VERSION ""

NS_ :

BS_:

BU_: TCM HCM IPMA_ADAS PSCM ABS_ESC TCCM TCM_DSL PCM_HEV PCM ECM_HEVDSL ECM_HEV ECM_Diesel ECM SIMA_DLCS BCMD_IPDB VDM CMR_DSMC SOBDMC_HPCM_FD1 CHCM GWM _delete AWD_DLCM GENERIC TSTR

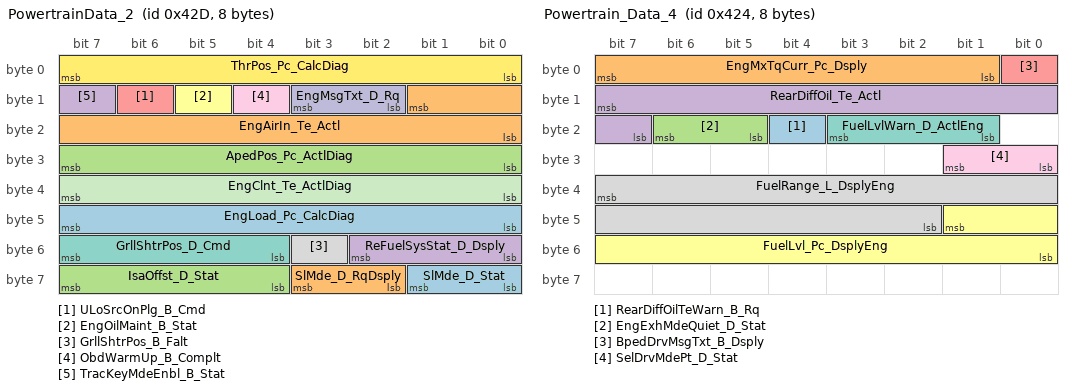
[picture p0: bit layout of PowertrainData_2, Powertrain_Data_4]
BO_ 1069 PowertrainData_2: 8 PCM_HEV
 SG_ SlMde_D_Stat : 57|2@0+ (1,0) [0|3] "SED"  GWM
 SG_ SlMde_D_RqDsply : 59|2@0+ (1,0) [0|3] "SED"  GWM
 SG_ IsaOffst_D_Stat : 63|4@0+ (1,0) [0|15] "SED"  GWM
 SG_ ReFuelSysStat_D_Dsply : 50|3@0+ (1,0) [0|7] "SED"  GWM
 SG_ ULoSrcOnPlg_B_Cmd : 14|1@0+ (1,0) [0|1] "SED"  SOBDMC_HPCM_FD1,GWM
 SG_ EngOilMaint_B_Stat : 13|1@0+ (1,0) [0|1] "SED"  SOBDMC_HPCM_FD1,GWM
 SG_ GrllShtrPos_D_Cmd : 55|4@0+ (1,0) [0|15] "SED"  GWM
 SG_ GrllShtrPos_B_Falt : 51|1@0+ (1,0) [0|1] "SED"  GWM
 SG_ ObdWarmUp_B_Complt : 12|1@0+ (1,0) [0|1] "SED"  SOBDMC_HPCM_FD1,GWM,TCM,TCM_DSL
 SG_ EngMsgTxt_D_Rq : 11|2@0+ (1,0) [0|3] "SED"  GWM
 SG_ EngClnt_Te_ActlDiag : 39|8@0+ (1,-40) [-40|215] "degC"  TCM,SOBDMC_HPCM_FD1,TCM_DSL,GWM,CHCM
 SG_ ThrPos_Pc_CalcDiag : 7|8@0+ (0.392157,0) [0|100.000035] "%"  TCM,GWM,TCM_DSL
 SG_ EngLoad_Pc_CalcDiag : 47|8@0+ (0.392157,0) [0|100.000035] "%"  TCM,SOBDMC_HPCM_FD1,TCM_DSL,GWM
 SG_ EngAirIn_Te_Actl : 9|10@0+ (0.25,-128) [-128|127.25] "degC"  TCM,GWM,TCM_DSL
 SG_ ApedPos_Pc_ActlDiag : 31|8@0+ (0.392157,0) [0|100.000035] "%"  TCM,SOBDMC_HPCM_FD1,TCM_DSL,GWM
 SG_ TracKeyMdeEnbl_B_Stat : 15|1@0+ (1,0) [0|1] "SED"  GWM

BO_ 1060 Powertrain_Data_4: 8 PCM_HEV
 SG_ RearDiffOilTeWarn_B_Rq : 20|1@0+ (1,0) [0|1] "SED"  GWM
 SG_ EngMxTqCurr_Pc_Dsply : 7|7@0+ (1,0) [0|100] "percent"  GWM
 SG_ EngExhMdeQuiet_D_Stat : 22|2@0+ (1,0) [0|3] "SED"  GWM
 SG_ RearDiffOil_Te_Actl : 15|9@0+ (1,-40) [-40|470] "degC"  GWM,AWD_DLCM
 SG_ BpedDrvMsgTxt_B_Dsply : 0|1@0+ (1,0) [0|1] "SED"  GWM
 SG_ FuelLvl_Pc_DsplyEng : 41|10@0+ (0.108696,-5.217408) [-5.217408|105.9786] "percent"  GWM
 SG_ FuelLvlWarn_D_ActlEng : 19|3@0+ (1,0) [0|7] "SED"  GWM
 SG_ FuelRange_L_DsplyEng : 39|14@0+ (0.1,0) [0|1638.3] "kilometer"  GWM
 SG_ SelDrvMdePt_D_Stat : 25|2@0+ (1,0) [0|3] "SED"  ABS_ESC,GWM

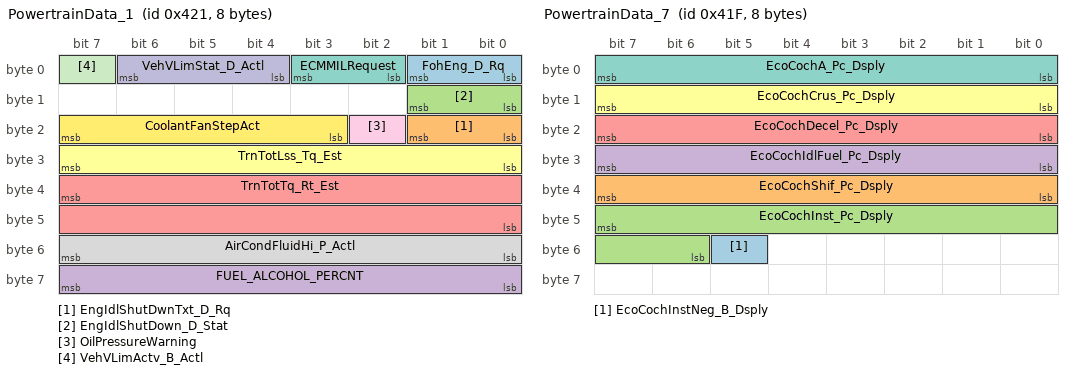
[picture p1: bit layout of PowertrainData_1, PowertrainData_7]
BO_ 1057 PowertrainData_1: 8 PCM_HEV
 SG_ FohEng_D_Rq : 1|2@0+ (1,0) [0|3] "SED"  GWM
 SG_ EngIdlShutDwnTxt_D_Rq : 17|2@0+ (1,0) [0|3] "SED"  GWM
 SG_ EngIdlShutDown_D_Stat : 9|2@0+ (1,0) [0|3] "SED"  GWM
 SG_ FUEL_ALCOHOL_PERCNT : 63|8@0+ (0.393700787,0) [0|99.999899898] "Percent"  GWM
 SG_ TrnTotTq_Rt_Est : 39|16@0+ (0.001,0) [0|65.533] "Unitless"  ABS_ESC,TCM,GWM,TCM_DSL
 SG_ TrnTotLss_Tq_Est : 31|8@0+ (0.5,0) [0|126.5] "Nm"  ABS_ESC,TCM,GWM,TCM_DSL
 SG_ ECMMILRequest : 3|2@0+ (1,0) [0|3] "SED"  GWM
 SG_ AirCondFluidHi_P_Actl : 55|8@0+ (0.125,0) [0|31.625] "bar"  SOBDMC_HPCM_FD1,GWM
 SG_ OilPressureWarning : 18|1@0+ (1,0) [0|1] "SED"  GWM
 SG_ VehVLimStat_D_Actl : 6|3@0+ (1,0) [0|7] "SED"  TCM,GWM,TCM_DSL
 SG_ VehVLimActv_B_Actl : 7|1@0+ (1,0) [0|1] "SED"  SOBDMC_HPCM_FD1,TCM,GWM,TCM_DSL
 SG_ CoolantFanStepAct : 23|5@0+ (1,0) [0|31] "Steps"  GWM

BO_ 1055 PowertrainData_7: 8 PCM_HEV
 SG_ EcoCochInstNeg_B_Dsply : 53|1@0+ (1,0) [0|1] "SED"  GWM
 SG_ EcoCochShif_Pc_Dsply : 39|8@0+ (0.392157,0) [0|100.000035] "percent"  GWM
 SG_ EcoCochInst_Pc_Dsply : 47|10@0+ (0.1,0) [0|102.3] "percent"  GWM
 SG_ EcoCochIdlFuel_Pc_Dsply : 31|8@0+ (0.392157,0) [0|100.000035] "percent"  GWM
 SG_ EcoCochDecel_Pc_Dsply : 23|8@0+ (0.392157,0) [0|100.000035] "percent"  GWM
 SG_ EcoCochCrus_Pc_Dsply : 15|8@0+ (0.392157,0) [0|100.000035] "percent"  GWM
 SG_ EcoCochA_Pc_Dsply : 7|8@0+ (0.392157,0) [0|100.000035] "percent"  GWM

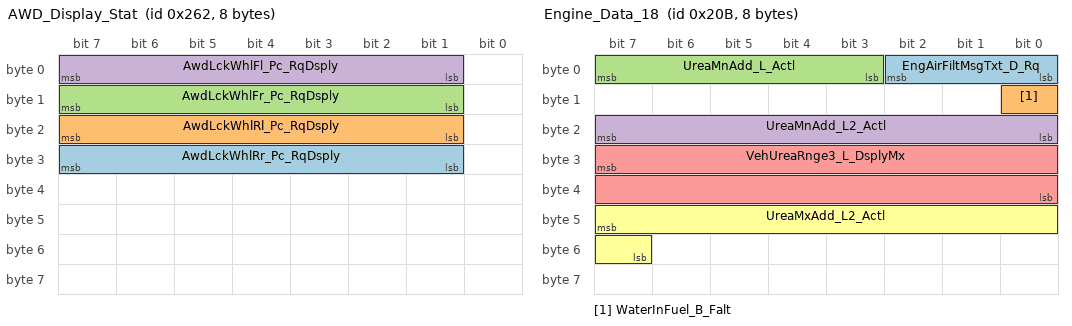
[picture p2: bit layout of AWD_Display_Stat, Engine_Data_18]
BO_ 610 AWD_Display_Stat: 8 PCM_HEV
 SG_ AwdLckWhlRr_Pc_RqDsply : 31|7@0+ (1,0) [0|127] "percent"  GWM
 SG_ AwdLckWhlRl_Pc_RqDsply : 23|7@0+ (1,0) [0|127] "percent"  GWM
 SG_ AwdLckWhlFr_Pc_RqDsply : 15|7@0+ (1,0) [0|127] "percent"  GWM
 SG_ AwdLckWhlFl_Pc_RqDsply : 7|7@0+ (1,0) [0|127] "percent"  GWM

BO_ 562 PowertrainData_11: 8 ECM
 SG_ GearNtrl_No_Cs : 15|8@0+ (1,0) [0|255] "unitless"  ABS_ESC,GWM
 SG_ GearNtrl_D_Stat : 7|2@0+ (1,0) [0|3] "SED"  ABS_ESC,GWM
 SG_ OnePdlDrv_D_Stat : 1|2@0+ (1,0) [0|3] "SED"  ABS_ESC,SOBDMC_HPCM_FD1
 SG_ GearNtrl_No_Cnt : 5|4@0+ (1,0) [0|15] "unitless"  ABS_ESC,GWM

BO_ 523 Engine_Data_18: 8 PCM
 SG_ EngAirFiltMsgTxt_D_Rq : 2|3@0+ (1,0) [0|7] "SED"  GWM
 SG_ WaterInFuel_B_Falt : 8|1@0+ (1,0) [0|1] "SED"  GWM
 SG_ UreaMnAdd_L_Actl : 7|5@0+ (1,0) [0|31] "litre"  GWM
 SG_ UreaMnAdd_L2_Actl : 23|8@0+ (0.1,0) [0|25.4] "litre"  GWM
 SG_ VehUreaRnge3_L_DsplyMx : 31|16@0+ (1,0) [0|65535] "unitless"  GWM
 SG_ UreaMxAdd_L2_Actl : 47|9@0+ (0.1,0) [0|51] "litre"  GWM

BO_ 519 PowertrainData_8: 8 ECM
 SG_ RearDiffLck_Tq_Rq : 7|14@0+ (1,0) [0|16381] "Nm"  GWM

BO_ 517 PowertrainData_6: 8 PCM_HEV
 SG_ FapLc_B_Err : 10|1@0+ (1,0) [0|1] "SED"  IPMA_ADAS,GWM
 SG_ BrkTot_Tq_RqFapLc : 7|13@0+ (4,0) [0|32764] "Nm"  ABS_ESC,GWM
 SG_ TrnAin_Pc_RqDrv : 9|10@0+ (0.1,0) [0|102.3] "percent"  GWM,AWD_DLCM,TCCM

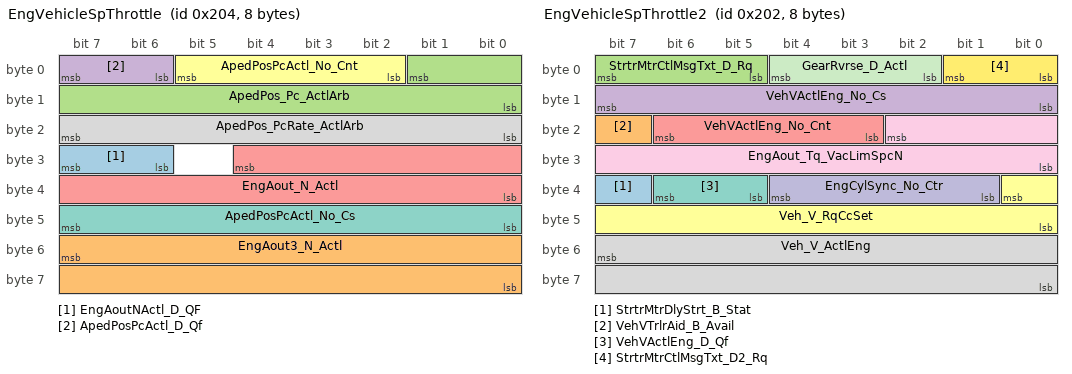
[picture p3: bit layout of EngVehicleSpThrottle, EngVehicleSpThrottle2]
BO_ 516 EngVehicleSpThrottle: 8 PCM_HEV
 SG_ EngAoutNActl_D_QF : 31|2@0+ (1,0) [0|3] "SED"  TCM,TCM_DSL,GWM
 SG_ EngAout3_N_Actl : 55|16@0+ (0.25,0) [0|16383.5] "RPM"  SOBDMC_HPCM_FD1,GWM
 SG_ ApedPos_Pc_ActlArb : 1|10@0+ (0.1,0) [0|102.3] "%"  TCM,CMR_DSMC,VDM,SOBDMC_HPCM_FD1,HCM,IPMA_ADAS,TCCM,ABS_ESC,PSCM,TCM_DSL,GWM,AWD_DLCM
 SG_ ApedPosPcActl_D_Qf : 7|2@0+ (1,0) [0|3] "SED"  CMR_DSMC,TCM,VDM,SOBDMC_HPCM_FD1,HCM,IPMA_ADAS,ABS_ESC,PSCM,TCM_DSL,GWM,AWD_DLCM
 SG_ EngAout_N_Actl : 28|13@0+ (2,0) [0|16382] "rpm"  TCM,VDM,HCM,ABS_ESC,PSCM,TCCM,TCM_DSL,GWM,AWD_DLCM
 SG_ ApedPosPcActl_No_Cnt : 5|4@0+ (1,0) [0|15] "Unitless"  TCM,SOBDMC_HPCM_FD1,ABS_ESC,TCM_DSL,GWM
 SG_ ApedPosPcActl_No_Cs : 47|8@0+ (1,0) [0|255] "Unitless"  TCM,SOBDMC_HPCM_FD1,ABS_ESC,TCM_DSL,GWM
 SG_ ApedPos_PcRate_ActlArb : 23|8@0+ (0.04,-5) [-5|5.12] "%/ms"  AWD_DLCM,TCM,TCM_DSL,GWM

BO_ 514 EngVehicleSpThrottle2: 8 PCM_HEV
 SG_ StrtrMtrDlyStrt_B_Stat : 39|1@0+ (1,0) [0|1] "SED"  GWM
 SG_ VehVTrlrAid_B_Avail : 23|1@0+ (1,0) [0|1] "SED"  PSCM,GWM
 SG_ StrtrMtrCtlMsgTxt_D_Rq : 7|3@0+ (1,0) [0|7] "SED"  GWM
 SG_ VehVActlEng_No_Cs : 15|8@0+ (1,0) [0|255] "Unitless"  ABS_ESC,PSCM,GWM
 SG_ VehVActlEng_No_Cnt : 22|4@0+ (1,0) [0|15] "Unitless"  ABS_ESC,PSCM,GWM
 SG_ Veh_V_RqCcSet : 32|9@0+ (0.5,0) [0|255.5] "kph"  TCM,IPMA_ADAS,PSCM,ABS_ESC,TCM_DSL,GWM,SOBDMC_HPCM_FD1
 SG_ VehVActlEng_D_Qf : 38|2@0+ (1,0) [0|3] "SED"  TCM,HCM,IPMA_ADAS,ABS_ESC,PSCM,TCM_DSL,GWM,VDM,AWD_DLCM
 SG_ Veh_V_ActlEng : 55|16@0+ (0.01,0) [0|655.35] "kph"  TCM,SOBDMC_HPCM_FD1,HCM,IPMA_ADAS,ABS_ESC,PSCM,TCM_DSL,VDM,GWM,AWD_DLCM
 SG_ EngAout_Tq_VacLimSpcN : 18|11@0+ (1,-500) [-500|1547] "Nm"  SOBDMC_HPCM_FD1,GWM
 SG_ EngCylSync_No_Ctr : 36|4@0+ (1,0) [0|15] "unitless"  SOBDMC_HPCM_FD1,GWM
 SG_ GearRvrse_D_Actl : 4|3@0+ (1,0) [0|7] "SED"  IPMA_ADAS,CMR_DSMC,ABS_ESC,PSCM,GWM,VDM,HCM,CHCM
 SG_ StrtrMtrCtlMsgTxt_D2_Rq : 1|2@0+ (1,0) [0|3] "SED"  GWM

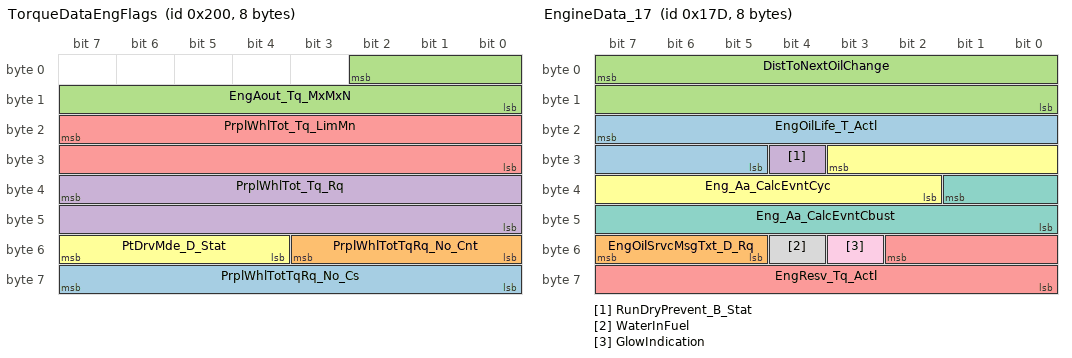
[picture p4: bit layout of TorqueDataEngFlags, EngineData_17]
BO_ 512 TorqueDataEngFlags: 8 PCM_HEV
 SG_ PrplWhlTotTqRq_No_Cs : 63|8@0+ (1,0) [0|255] "Unitless"  SOBDMC_HPCM_FD1,ABS_ESC,GWM
 SG_ PrplWhlTotTqRq_No_Cnt : 51|4@0+ (1,0) [0|15] "Unitless"  SOBDMC_HPCM_FD1,ABS_ESC,GWM
 SG_ EngAout_Tq_MxMxN : 2|11@0+ (1,-500) [-500|1547] "Nm"  SOBDMC_HPCM_FD1,GWM
 SG_ PrplWhlTot_Tq_Rq : 39|16@0+ (4,-131072) [-131072|131068] "Nm"  VDM,SOBDMC_HPCM_FD1,TCCM,ABS_ESC,GWM,AWD_DLCM
 SG_ PrplWhlTot_Tq_LimMn : 23|16@0+ (4,-131072) [-131072|131068] "Nm"  ABS_ESC,GWM
 SG_ PtDrvMde_D_Stat : 55|4@0+ (1,0) [0|15] "SED"  IPMA_ADAS,ABS_ESC,GWM

BO_ 382 EngineData_Gas: 8 PCM
 SG_ EngMnfldChrg_Te_Actl : 15|7@0+ (1,-20) [-20|105] "degC"  GWM
 SG_ EngInnrClnt_Te_Actl : 7|7@0+ (1,50) [50|175] "degC"  GWM

BO_ 381 EngineData_17: 8 ECM_HEVDSL
 SG_ EngOilLife_T_Actl : 23|11@0+ (1,0) [0|2047] "days"  GWM
 SG_ EngOilSrvcMsgTxt_D_Rq : 55|3@0+ (1,0) [0|7] "SED"  GWM
 SG_ DistToNextOilChange : 7|16@0+ (1,0) [0|65535] "unitless"  GWM
 SG_ RunDryPrevent_B_Stat : 28|1@0+ (1,0) [0|1] "SED"  GWM
 SG_ EngResv_Tq_Actl : 50|11@0+ (1,-500) [-500|1547] "Nm"  GWM
 SG_ Eng_Aa_CalcEvntCyc : 27|10@0+ (0.05,-25.6) [-25.6|25.55] "rpm/ms"  GWM
 SG_ Eng_Aa_CalcEvntCbust : 33|10@0+ (0.05,-25.6) [-25.6|25.55] "rpm/ms"  GWM
 SG_ WaterInFuel : 52|1@0+ (1,0) [0|1] "SED"  GWM
 SG_ GlowIndication : 51|1@0+ (1,0) [0|1] "SED"  GWM

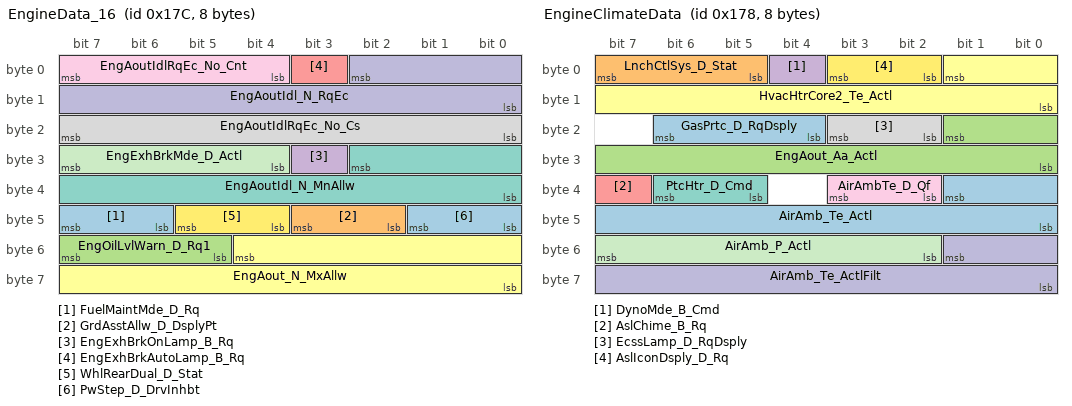
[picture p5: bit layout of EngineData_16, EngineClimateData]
BO_ 380 EngineData_16: 8 PCM
 SG_ FuelMaintMde_D_Rq : 47|2@0+ (1,0) [0|3] "SED"  SOBDMC_HPCM_FD1,GWM
 SG_ GrdAsstAllw_D_DsplyPt : 43|2@0+ (1,0) [0|3] "SED"  SOBDMC_HPCM_FD1,GWM
 SG_ EngOilLvlWarn_D_Rq1 : 55|3@0+ (1,0) [0|7] "SED"  GWM
 SG_ EngExhBrkOnLamp_B_Rq : 27|1@0+ (1,0) [0|1] "SED"  GWM
 SG_ EngExhBrkAutoLamp_B_Rq : 3|1@0+ (1,0) [0|1] "SED"  GWM
 SG_ EngAout_N_MxAllw : 52|13@0+ (2,0) [0|16382] "rpm"  TCM,SOBDMC_HPCM_FD1,TCM_DSL,GWM
 SG_ EngAoutIdl_N_MnAllw : 26|11@0+ (2,0) [0|4094] "rpm"  GWM
 SG_ EngAoutIdlRqEc_No_Cs : 23|8@0+ (1,0) [0|255] "Unitless"  GWM
 SG_ EngAoutIdlRqEc_No_Cnt : 7|4@0+ (1,0) [0|15] "Unitless"  GWM
 SG_ EngAoutIdl_N_RqEc : 2|11@0+ (2,0) [0|4094] "rpm"  GWM
 SG_ EngExhBrkMde_D_Actl : 31|4@0+ (1,0) [0|15] "SED"  TCM,TCM_DSL,GWM
 SG_ WhlRearDual_D_Stat : 45|2@0+ (1,0) [0|3] "SED"  TCM,TCM_DSL,GWM
 SG_ PwStep_D_DrvInhbt : 41|2@0+ (1,0) [0|3] "SED"  GWM

BO_ 377 EngineData_7: 8 PCM_HEV
 SG_ HvacAirFullOut_B_Rq : 23|1@0+ (1,0) [0|1] "SED"  GWM
 SG_ TrnManShif_D_IndDrv : 7|3@0+ (1,0) [0|7] "Unitless"  GWM
 SG_ EngAout_Tq_Actl : 2|11@0+ (1,-500) [-500|1547] "Nm"  SOBDMC_HPCM_FD1,GWM
 SG_ TrnManShifGear_D_IndDrv : 54|3@0+ (1,0) [0|7] "SED"  GWM
 SG_ EngFuelCutFull_B_Inhbt : 22|1@0+ (1,0) [0|1] "SED"  SOBDMC_HPCM_FD1,GWM
 SG_ EngDecelFuelCut_B_Allw : 21|1@0+ (1,0) [0|1] "SED"  TCM,TCM_DSL,GWM
 SG_ FuelFlw_Vl_Dsply : 49|10@0+ (25,0) [0|25575] "Micro_Liter"  SOBDMC_HPCM_FD1,GWM
 SG_ FuelFillInlet_B_Dsply : 32|1@0+ (1,0) [0|1] "SED"  GWM
 SG_ EngSrvcRqd_B_Rq : 19|1@0+ (1,0) [0|1] "SED"  GWM
 SG_ OdoCount : 47|8@0+ (0.2,0) [0|50.8] "Meters"  GWM
 SG_ EngOilLife_Pc_Actl : 39|7@0+ (1,0) [0|100] "Percent"  GWM
 SG_ EngTqSlwDly_T_Est : 18|11@0+ (1,0) [0|2047] "ms"  TCM,TCM_DSL,GWM
 SG_ TrnKickDown_B_RqDrv : 20|1@0+ (1,0) [0|1] "SED"  TCM,TCM_DSL,GWM
 SG_ FuelFilterLamp_B_Dsply : 50|1@0+ (1,0) [0|1] "SED"  GWM
 SG_ AirCondRec_B_Rq : 55|1@0+ (1,0) [0|1] "SED"  GWM
 SG_ AirCondClutch_B_Stats : 51|1@0+ (1,0) [0|1] "SED"  TCM,TCM_DSL,GWM
 SG_ EngAoutTqActl_D_Qf : 4|2@0+ (1,0) [0|3] "SED"  SOBDMC_HPCM_FD1,GWM

BO_ 376 EngineClimateData: 8 PCM_HEV
 SG_ GasPrtc_D_RqDsply : 22|3@0+ (1,0) [0|7] "SED"  GWM
 SG_ LnchCtlSys_D_Stat : 7|3@0+ (1,0) [0|7] "SED"  ABS_ESC,GWM
 SG_ EngAout_Aa_Actl : 17|10@0+ (0.05,-25.6) [-25.6|25.55] "rpm/ms"  TCM,TCM_DSL,ABS_ESC,GWM
 SG_ DynoMde_B_Cmd : 4|1@0+ (1,0) [0|1] "SED"  TCM,TCM_DSL,ABS_ESC,GWM
 SG_ AslChime_B_Rq : 39|1@0+ (1,0) [0|1] "SED"  GWM
 SG_ HvacHtrCore2_Te_Actl : 1|10@0+ (0.25,-50) [-50|205.5] "degC"  SOBDMC_HPCM_FD1,GWM
 SG_ PtcHtr_D_Cmd : 38|2@0+ (1,0) [0|3] "SED"  SOBDMC_HPCM_FD1,GWM
 SG_ EcssLamp_D_RqDsply : 19|2@0+ (1,0) [0|3] "SED"  GWM
 SG_ AirAmbTe_D_Qf : 35|2@0+ (1,0) [0|3] "SED"  TCM,SOBDMC_HPCM_FD1,IPMA_ADAS,TCM_DSL,ABS_ESC,TCCM,GWM,VDM,AWD_DLCM,CHCM
 SG_ AirAmb_Te_ActlFilt : 49|10@0+ (0.25,-128) [-128|127.75] "deg C"  TCM,SOBDMC_HPCM_FD1,IPMA_ADAS,TCM_DSL,VDM,GWM,CHCM
 SG_ AirAmb_P_Actl : 55|6@0+ (10,500) [500|1110] "mbar"  TCM,TCM_DSL,ABS_ESC,GWM,VDM
 SG_ AslIconDsply_D_Rq : 3|2@0+ (1,0) [0|3] "SED"  GWM
 SG_ AirAmb_Te_Actl : 33|10@0+ (0.25,-128) [-128|127.75] "degC"  VDM,TCM_DSL,TCM,TCCM,HCM,AWD_DLCM,ABS_ESC,GWM,CHCM

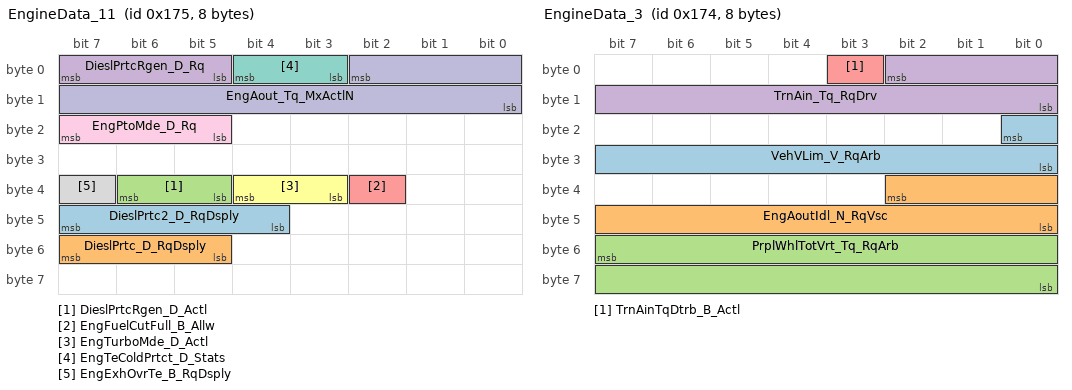
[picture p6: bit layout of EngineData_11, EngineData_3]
BO_ 373 EngineData_11: 8 ECM_HEVDSL
 SG_ DieslPrtc2_D_RqDsply : 47|4@0+ (1,0) [0|15] "SED"  GWM
 SG_ DieslPrtc_D_RqDsply : 55|3@0+ (1,0) [0|7] "SED"  GWM
 SG_ DieslPrtcRgen_D_Actl : 38|2@0+ (1,0) [0|3] "SED"  TCM,TCM_DSL,GWM
 SG_ DieslPrtcRgen_D_Rq : 7|3@0+ (1,0) [0|7] "SED"  GWM
 SG_ EngFuelCutFull_B_Allw : 34|1@0+ (1,0) [0|1] "SED"  SOBDMC_HPCM_FD1,GWM
 SG_ EngTurboMde_D_Actl : 36|2@0+ (1,0) [0|3] "SED"  TCM,TCM_DSL,GWM
 SG_ EngTeColdPrtct_D_Stats : 4|2@0+ (1,0) [0|3] "SED"  GWM
 SG_ EngExhOvrTe_B_RqDsply : 39|1@0+ (1,0) [0|1] "SED"  GWM
 SG_ EngPtoMde_D_Rq : 23|3@0+ (1,0) [0|7] "SED"  TCM,TCM_DSL,GWM
 SG_ EngAout_Tq_MxActlN : 2|11@0+ (1,-500) [-500|1547] "Nm"  GWM,GENERIC

BO_ 372 EngineData_3: 8 ECM
 SG_ VehVLim_V_RqArb : 16|9@0+ (0.5,0) [0|255.5] "kph"  TCM,TCM_DSL,GWM
 SG_ EngAoutIdl_N_RqVsc : 34|11@0+ (2,0) [0|4094] "rpm"  TCM,TCM_DSL,ABS_ESC,GWM
 SG_ PrplWhlTotVrt_Tq_RqArb : 55|16@0+ (4,-131072) [-131072|131068] "Nm"  TCM,TCM_DSL,GWM
 SG_ TrnAin_Tq_RqDrv : 2|11@0+ (1,-500) [-500|1547] "Nm"  TCM,TCM_DSL,GWM
 SG_ TrnAinTqDtrb_B_Actl : 3|1@0+ (1,0) [0|1] "SED"  TCM,TCM_DSL,GWM

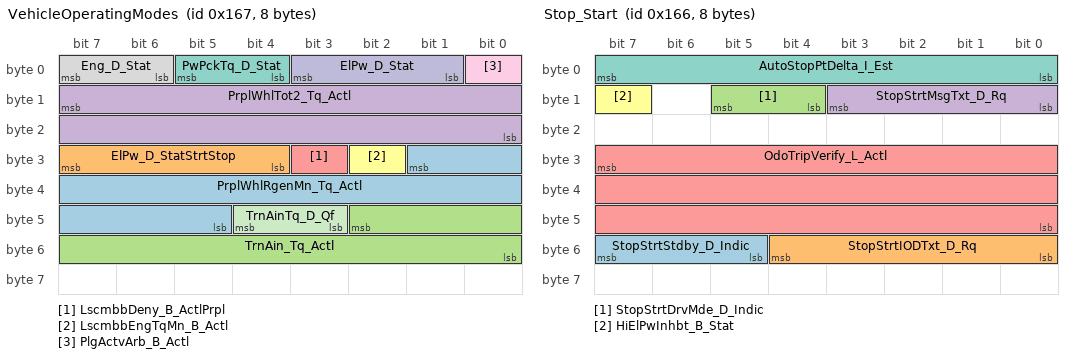
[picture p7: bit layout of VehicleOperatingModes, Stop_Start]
BO_ 359 VehicleOperatingModes: 8 PCM_HEV
 SG_ PrplWhlRgenMn_Tq_Actl : 25|13@0+ (4,-16380) [-16380|16380] "Nm"  ABS_ESC,GWM,AWD_DLCM
 SG_ ElPw_D_StatStrtStop : 31|4@0+ (1,0) [0|15] "SED"  PSCM,GWM,ABS_ESC
 SG_ TrnAin_Tq_Actl : 42|11@0+ (1,-500) [-500|1547] "Nm"  TCM,ABS_ESC,TCM_DSL,GWM,AWD_DLCM
 SG_ PrplWhlTot2_Tq_Actl : 15|16@0+ (4,-131072) [-131072|131060] "Nm"  VDM,ABS_ESC,ECM_HEV,PSCM,TCCM,GWM,AWD_DLCM
 SG_ LscmbbDeny_B_ActlPrpl : 27|1@0+ (1,0) [0|1] "SED"  ABS_ESC,GWM
 SG_ LscmbbEngTqMn_B_Actl : 26|1@0+ (1,0) [0|1] "SED"  ABS_ESC,GWM
 SG_ PwPckTq_D_Stat : 5|2@0+ (1,0) [0|3] "SED"  TCM,SOBDMC_HPCM_FD1,VDM,HCM,IPMA_ADAS,ABS_ESC,ECM_HEV,PSCM,TCCM,TCM_DSL,CMR_DSMC,GWM,AWD_DLCM,CHCM
 SG_ Eng_D_Stat : 7|2@0+ (1,0) [0|3] "SED"  TCM,VDM,ABS_ESC,TCM_DSL,GWM,AWD_DLCM
 SG_ PlgActvArb_B_Actl : 0|1@0+ (1,0) [0|1] "SED"  SOBDMC_HPCM_FD1,GWM,ECM_HEV
 SG_ ElPw_D_Stat : 3|3@0+ (1,0) [0|7] "SED"  TCM,VDM,HCM,IPMA_ADAS,ABS_ESC,ECM_HEV,PSCM,TCCM,TCM_DSL,GWM,CMR_DSMC,AWD_DLCM,CHCM
 SG_ TrnAinTq_D_Qf : 44|2@0+ (1,0) [0|3] "SED"  TCM,ABS_ESC,TCM_DSL,GWM,AWD_DLCM

BO_ 358 Stop_Start: 8 PCM_HEV
 SG_ StopStrtStdby_D_Indic : 55|3@0+ (1,0) [0|7] "SED"  GWM
 SG_ StopStrtIODTxt_D_Rq : 52|5@0+ (1,0) [0|31] "SED"  GWM
 SG_ StopStrtDrvMde_D_Indic : 13|2@0+ (1,0) [0|3] "SED"  GWM
 SG_ StopStrtMsgTxt_D_Rq : 11|4@0+ (1,0) [0|15] "SED"  GWM
 SG_ OdoTripVerify_L_Actl : 31|24@0+ (0.1,0) [0|1677721.4] "km"  GWM
 SG_ HiElPwInhbt_B_Stat : 15|1@0+ (1,0) [0|1] "SED"  GWM
 SG_ AutoStopPtDelta_I_Est : 7|8@0+ (1,-127) [-127|127] "Amps"  GWM

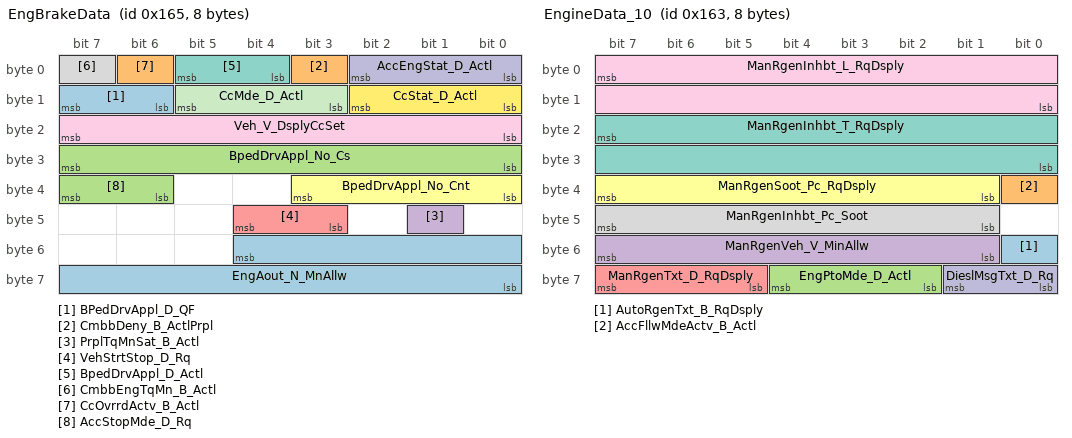
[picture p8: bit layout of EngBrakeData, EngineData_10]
BO_ 357 EngBrakeData: 8 PCM_HEV
 SG_ BPedDrvAppl_D_QF : 15|2@0+ (1,0) [0|3] "SED"  TCM,SOBDMC_HPCM_FD1,IPMA_ADAS,ABS_ESC,PSCM,TCM_DSL,GWM,VDM,CMR_DSMC,AWD_DLCM
 SG_ CmbbDeny_B_ActlPrpl : 3|1@0+ (1,0) [0|1] "SED"  IPMA_ADAS,GWM
 SG_ BpedDrvAppl_No_Cs : 31|8@0+ (1,0) [0|255] "Unitless"  SOBDMC_HPCM_FD1,GWM
 SG_ PrplTqMnSat_B_Actl : 41|1@0+ (1,0) [0|1] "SED"  IPMA_ADAS,GWM
 SG_ VehStrtStop_D_Rq : 44|2@0+ (1,0) [0|3] "SED"  SOBDMC_HPCM_FD1,GWM
 SG_ BpedDrvAppl_No_Cnt : 35|4@0+ (1,0) [0|15] "Unitless"  SOBDMC_HPCM_FD1,GWM
 SG_ BpedDrvAppl_D_Actl : 5|2@0+ (1,0) [0|3] "SED"  TCM,SOBDMC_HPCM_FD1,IPMA_ADAS,ABS_ESC,PSCM,TCCM,TCM_DSL,VDM,GWM,CMR_DSMC,AWD_DLCM
 SG_ CmbbEngTqMn_B_Actl : 7|1@0+ (1,0) [0|1] "SED"  IPMA_ADAS,GWM
 SG_ Veh_V_DsplyCcSet : 23|8@0+ (1,0) [0|253] "Unitless"  GWM,IPMA_ADAS
 SG_ AccEngStat_D_Actl : 2|3@0+ (1,0) [0|7] "SED"  IPMA_ADAS,GWM
 SG_ CcMde_D_Actl : 13|3@0+ (1,0) [0|7] "SED"  TCM,TCM_DSL,ABS_ESC,GWM,VDM
 SG_ CcStat_D_Actl : 10|3@0+ (1,0) [0|7] "SED"  TCM,SOBDMC_HPCM_FD1,IPMA_ADAS,ABS_ESC,TCCM,TCM_DSL,GWM,CMR_DSMC,AWD_DLCM
 SG_ EngAout_N_MnAllw : 52|13@0+ (2,0) [0|16382] "rpm"  TCM,SOBDMC_HPCM_FD1,TCM_DSL,GWM
 SG_ CcOvrrdActv_B_Actl : 6|1@0+ (1,0) [0|1] "SED"  TCM,IPMA_ADAS,ABS_ESC,TCCM,TCM_DSL,GWM,VDM,AWD_DLCM
 SG_ AccStopMde_D_Rq : 39|2@0+ (1,0) [0|3] "SED"  IPMA_ADAS,ABS_ESC,GWM

BO_ 355 EngineData_10: 8 ECM_HEVDSL
 SG_ AutoRgenTxt_B_RqDsply : 48|1@0+ (1,0) [0|1] "SED"  GWM
 SG_ AccFllwMdeActv_B_Actl : 32|1@0+ (1,0) [0|1] "SED"  TCM,TCM_DSL,GWM
 SG_ EngPtoMde_D_Actl : 60|3@0+ (1,0) [0|7] "SED"  TCM,TCM_DSL,GWM
 SG_ ManRgenVeh_V_MinAllw : 55|7@0+ (1,0) [0|126] "kilometer/hour"  GWM
 SG_ ManRgenTxt_D_RqDsply : 63|3@0+ (1,0) [0|7] "SED"  GWM
 SG_ ManRgenSoot_Pc_RqDsply : 39|7@0+ (1,0) [0|126] "%"  GWM
 SG_ ManRgenInhbt_T_RqDsply : 23|16@0+ (1,0) [0|65534] "Minutes"  GWM
 SG_ ManRgenInhbt_Pc_Soot : 47|7@0+ (1,0) [0|126] "%"  GWM
 SG_ ManRgenInhbt_L_RqDsply : 7|16@0+ (1,0) [0|65534] "kilometer"  GWM
 SG_ DieslMsgTxt_D_Rq : 57|2@0+ (1,0) [0|3] "SED"  GWM

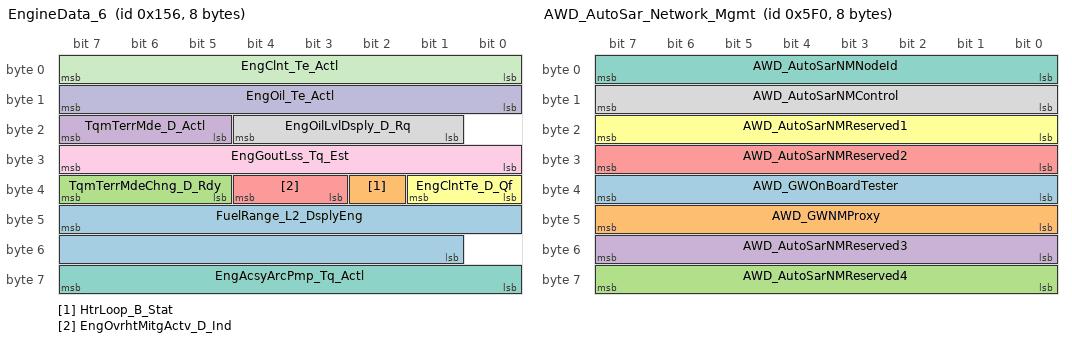
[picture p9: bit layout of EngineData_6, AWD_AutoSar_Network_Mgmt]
BO_ 342 EngineData_6: 8 PCM_HEV
 SG_ FuelRange_L2_DsplyEng : 47|15@0+ (0.1,0) [0|3276.7] "kilometer"  GWM
 SG_ HtrLoop_B_Stat : 34|1@0+ (1,0) [0|1] "SED"  SOBDMC_HPCM_FD1,GWM
 SG_ TqmTerrMdeChng_D_Rdy : 39|3@0+ (1,0) [0|7] "SED"  GWM
 SG_ TqmTerrMde_D_Actl : 23|3@0+ (1,0) [0|7] "SED"  GWM
 SG_ EngOvrhtMitgActv_D_Ind : 36|2@0+ (1,0) [0|3] "SED"  GWM
 SG_ EngClntTe_D_Qf : 33|2@0+ (1,0) [0|3] "SED"  VDM,SOBDMC_HPCM_FD1,ABS_ESC,TCM,TCM_DSL,GWM,AWD_DLCM,CHCM
 SG_ EngAcsyArcPmp_Tq_Actl : 63|8@0+ (0.5,0) [0|126.5] "Nm"  TCM,TCM_DSL,GWM
 SG_ EngOilLvlDsply_D_Rq : 20|4@0+ (1,0) [0|15] "SED"  GWM
 SG_ EngGoutLss_Tq_Est : 31|8@0+ (1,0) [0|255] "Nm"  SOBDMC_HPCM_FD1,GWM
 SG_ EngOil_Te_Actl : 15|8@0+ (1,-60) [-60|193] "degC"  TCM,TCM_DSL,GWM,AWD_DLCM
 SG_ EngClnt_Te_Actl : 7|8@0+ (1,-60) [-60|195] "degC"  VDM,SOBDMC_HPCM_FD1,ABS_ESC,TCM,TCM_DSL,GWM,AWD_DLCM,CHCM

BO_ 1520 AWD_AutoSar_Network_Mgmt: 8 AWD_DLCM
 SG_ AWD_GWOnBoardTester : 39|8@0+ (1,0) [0|255] "unitless"  GENERIC
 SG_ AWD_GWNMProxy : 47|8@0+ (1,0) [0|255] "unitless"  GENERIC
 SG_ AWD_AutoSarNMReserved4 : 63|8@0+ (1,0) [0|255] "unitless"  GENERIC
 SG_ AWD_AutoSarNMReserved3 : 55|8@0+ (1,0) [0|255] "unitless"  GENERIC
 SG_ AWD_AutoSarNMReserved2 : 31|8@0+ (1,0) [0|255] "unitless"  GENERIC
 SG_ AWD_AutoSarNMReserved1 : 23|8@0+ (1,0) [0|255] "unitless"  GENERIC
 SG_ AWD_AutoSarNMNodeId : 7|8@0+ (1,0) [0|255] "unitless"  GENERIC
 SG_ AWD_AutoSarNMControl : 15|8@0+ (1,0) [0|255] "unitless"  GENERIC

BO_ 71 Global_PATS_TargetInfo: 8 SOBDMC_HPCM_FD1
 SG_ immoTarget1Status : 7|3@0+ (1,0) [0|7] "SED"  TCM,ABS_ESC,TCM_DSL,GWM
 SG_ immoTarget1Data : 15|40@0+ (1,0) [0|1099511627775] "Encrypted"  ABS_ESC,GWM
 SG_ immoTarget1Cmd : 4|3@0+ (1,0) [0|7] "SED"  ABS_ESC,GWM

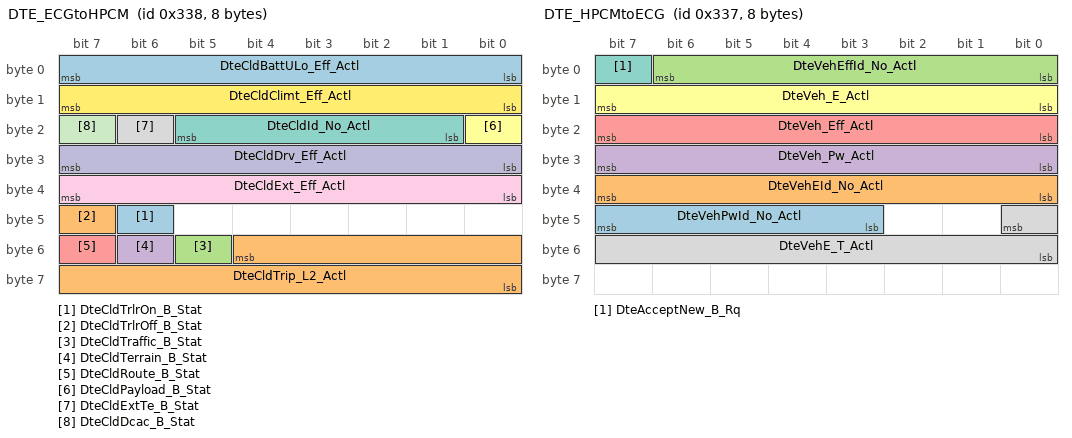
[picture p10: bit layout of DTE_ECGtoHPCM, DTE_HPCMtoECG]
BO_ 824 DTE_ECGtoHPCM: 8 GWM
 SG_ DteCldTrlrOn_B_Stat : 46|1@0+ (1,0) [0|1] "SED"  SOBDMC_HPCM_FD1
 SG_ DteCldTrlrOff_B_Stat : 47|1@0+ (1,0) [0|1] "SED"  SOBDMC_HPCM_FD1
 SG_ DteCldTraffic_B_Stat : 53|1@0+ (1,0) [0|1] "SED"  SOBDMC_HPCM_FD1
 SG_ DteCldTerrain_B_Stat : 54|1@0+ (1,0) [0|1] "SED"  SOBDMC_HPCM_FD1
 SG_ DteCldRoute_B_Stat : 55|1@0+ (1,0) [0|1] "SED"  SOBDMC_HPCM_FD1
 SG_ DteCldPayload_B_Stat : 16|1@0+ (1,0) [0|1] "SED"  SOBDMC_HPCM_FD1
 SG_ DteCldId_No_Actl : 21|5@0+ (1,0) [0|31] "unitless"  SOBDMC_HPCM_FD1
 SG_ DteCldExtTe_B_Stat : 22|1@0+ (1,0) [0|1] "SED"  SOBDMC_HPCM_FD1
 SG_ DteCldExt_Eff_Actl : 39|8@0+ (10,-1000) [-1000|1550] "watt*hour/km"  SOBDMC_HPCM_FD1
 SG_ DteCldDrv_Eff_Actl : 31|8@0+ (10,-1000) [-1000|1550] "watt*hour/km"  SOBDMC_HPCM_FD1
 SG_ DteCldDcac_B_Stat : 23|1@0+ (1,0) [0|1] "SED"  SOBDMC_HPCM_FD1
 SG_ DteCldClimt_Eff_Actl : 15|8@0+ (10,-1000) [-1000|1550] "watt*hour/km"  SOBDMC_HPCM_FD1
 SG_ DteCldBattULo_Eff_Actl : 7|8@0+ (10,-1000) [-1000|1550] "watt*hour/km"  SOBDMC_HPCM_FD1
 SG_ DteCldTrip_L2_Actl : 52|13@0+ (0.1,0) [0|818.9] "kilometer"  SOBDMC_HPCM_FD1

BO_ 823 DTE_HPCMtoECG: 8 SOBDMC_HPCM_FD1
 SG_ DteVehPwId_No_Actl : 47|5@0+ (1,0) [0|31] "unitless"  GWM
 SG_ DteVehEId_No_Actl : 39|8@0+ (1,0) [0|255] "unitless"  GWM
 SG_ DteVehEffId_No_Actl : 6|7@0+ (1,0) [0|127] "unitless"  GWM
 SG_ DteVeh_Pw_Actl : 31|8@0+ (50,0) [0|12750] "watts"  GWM
 SG_ DteVeh_Eff_Actl : 23|8@0+ (10,-1000) [-1000|1550] "watt*hour/km"  GWM
 SG_ DteVeh_E_Actl : 15|8@0+ (100,0) [0|25500] "watt*hour"  GWM
 SG_ DteAcceptNew_B_Rq : 7|1@0+ (1,0) [0|1] "SED"  GWM
 SG_ DteVehE_T_Actl : 40|9@0+ (10,0) [0|5110] "second"  GWM

BO_ 1920 TesterPhysicalReqSGM_FD1: 64 TSTR
 SG_ TesterPhysicalReqSGM : 7|64@0+ (1,0) [0|1.84467E+019] "unitless"  ECM_HEVDSL,PCM_HEV

BO_ 811 APIM_Data_FD1: 8 GWM
 SG_ SpeedoMajorUnit_D_Confg : 59|2@0+ (1,0) [0|3] "SED"  SOBDMC_HPCM_FD1
 SG_ ScMnSoc_Pc_RqMnu : 55|7@0+ (1,0) [0|125] "percent"  SOBDMC_HPCM_FD1
 SG_ ScEnbl_D_RqMnu : 57|2@0+ (1,0) [0|3] "SED"  SOBDMC_HPCM_FD1
 SG_ OnePdlDrvButtn_B_Falt : 16|1@0+ (1,0) [0|1] "SED"  PCM
 SG_ OnePdlDrvButtn_B_Stat : 48|1@0+ (1,0) [0|1] "SED"  PCM
 SG_ DistToStopover_L_Actl : 31|16@0+ (0.1,0) [0|6553.4] "kilometer"  SOBDMC_HPCM_FD1
 SG_ StopoverType_D_Stat : 47|3@0+ (1,0) [0|0] "SED"  SOBDMC_HPCM_FD1
 SG_ ExtLghtDsply_D_Stat : 7|3@0+ (1,0) [0|7] "SED"  GENERIC
 SG_ ExtLghtRight_D_RqMnu : 11|3@0+ (1,0) [0|7] "SED"  GENERIC
 SG_ AutoLghtOvrrd_B_RqDrv : 8|1@0+ (1,0) [0|1] "SED"  GENERIC
 SG_ ExtLghtRear_D_RqMnu : 14|3@0+ (1,0) [0|7] "SED"  GENERIC
 SG_ LongTermReset_B_RqMnu : 17|1@0+ (1,0) [0|1] "SED"  SOBDMC_HPCM_FD1
 SG_ ExtLghtLeft_D_RqMnu : 1|3@0+ (1,0) [0|7] "SED"  GENERIC
 SG_ ExtLghtFront_D_RqMnu : 4|3@0+ (1,0) [0|7] "SED"  GENERIC
 SG_ GoTEditMnte_T_RqMnu : 63|4@0+ (1,0) [0|15] "SED"  SOBDMC_HPCM_FD1
 SG_ GoTEditHr_T_RqMnu : 44|5@0+ (1,0) [0|29] "SED"  SOBDMC_HPCM_FD1
 SG_ BecRleas_No_RqMnu : 23|3@0+ (1,0) [0|7] "unitless"  GENERIC
 SG_ TrnkFrontRleas_No_RqMnu : 20|3@0+ (1,0) [0|7] "unitless"  GENERIC

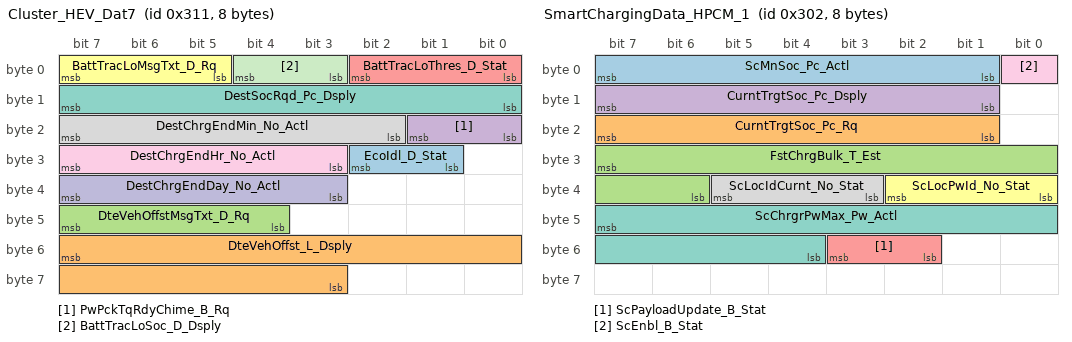
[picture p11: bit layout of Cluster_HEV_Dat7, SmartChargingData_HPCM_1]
BO_ 785 Cluster_HEV_Dat7: 8 SOBDMC_HPCM_FD1
 SG_ EcoIdl_D_Stat : 26|2@0+ (1,0) [0|3] "SED"  GWM
 SG_ DteVehOffst_L_Dsply : 55|13@0+ (0.1,-400) [-400|418.9] "kilometer"  GWM
 SG_ DteVehOffstMsgTxt_D_Rq : 47|4@0+ (1,0) [0|15] "SED"  GWM
 SG_ PwPckTqRdyChime_B_Rq : 17|2@0+ (1,0) [0|3] "SED"  GWM
 SG_ BattTracLoThres_D_Stat : 2|3@0+ (1,0) [0|7] "SED"  GWM
 SG_ BattTracLoMsgTxt_D_Rq : 7|3@0+ (1,0) [0|7] "SED"  GWM
 SG_ DestSocRqd_Pc_Dsply : 15|8@0+ (0.5,0) [0|127.5] "percent"  GWM
 SG_ DestChrgEndMin_No_Actl : 23|6@0+ (1,0) [0|63] "Minutes"  GWM
 SG_ DestChrgEndHr_No_Actl : 31|5@0+ (1,0) [0|31] "Hours"  GWM
 SG_ DestChrgEndDay_No_Actl : 39|5@0+ (1,0) [1|31] "days"  GWM
 SG_ BattTracLoSoc_D_Dsply : 4|2@0+ (1,0) [0|3] "SED"  GWM

BO_ 770 SmartChargingData_HPCM_1: 8 SOBDMC_HPCM_FD1
 SG_ ScMnSoc_Pc_Actl : 7|7@0+ (1,0) [0|127] "percent"  GWM
 SG_ CurntTrgtSoc_Pc_Rq : 23|7@0+ (1,0) [0|127] "percent"  GWM
 SG_ FstChrgBulk_T_Est : 31|10@0+ (1,0) [0|1023] "minute"  GWM
 SG_ CurntTrgtSoc_Pc_Dsply : 15|7@0+ (1,0) [0|127] "percent"  GWM
 SG_ ScPayloadUpdate_B_Stat : 51|2@0+ (1,0) [0|3] "SED"  GWM
 SG_ ScLocPwId_No_Stat : 34|3@0+ (1,0) [0|7] "unitless"  GWM
 SG_ ScChrgrPwMax_Pw_Actl : 47|12@0+ (50,0) [0|204700] "watts"  GWM
 SG_ ScLocIdCurnt_No_Stat : 37|3@0+ (1,0) [0|7] "unitless"  GWM
 SG_ ScEnbl_B_Stat : 0|1@0+ (1,0) [0|1] "SED"  GWM

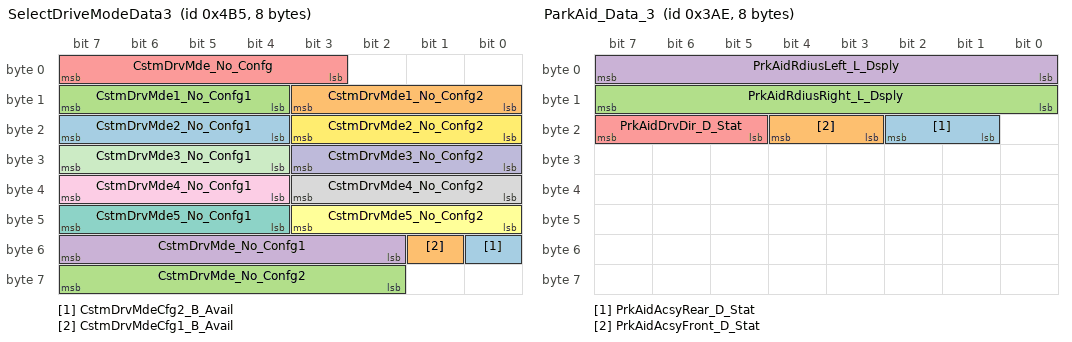
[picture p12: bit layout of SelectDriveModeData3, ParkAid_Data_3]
BO_ 1205 SelectDriveModeData3: 8 ABS_ESC
 SG_ CstmDrvMdeCfg2_B_Avail : 48|1@0+ (1,0) [0|1] "SED"  GWM
 SG_ CstmDrvMdeCfg1_B_Avail : 49|1@0+ (1,0) [0|1] "SED"  GWM
 SG_ CstmDrvMde_No_Confg2 : 63|6@0+ (1,0) [0|63] "unitless"  GWM
 SG_ CstmDrvMde_No_Confg1 : 55|6@0+ (1,0) [0|63] "unitless"  GWM
 SG_ CstmDrvMde_No_Confg : 7|5@0+ (1,0) [0|31] "unitless"  GWM
 SG_ CstmDrvMde5_No_Confg2 : 43|4@0+ (1,0) [0|15] "unitless"  GWM
 SG_ CstmDrvMde5_No_Confg1 : 47|4@0+ (1,0) [0|15] "unitless"  GWM
 SG_ CstmDrvMde4_No_Confg2 : 35|4@0+ (1,0) [0|15] "unitless"  GWM
 SG_ CstmDrvMde4_No_Confg1 : 39|4@0+ (1,0) [0|15] "unitless"  GWM
 SG_ CstmDrvMde3_No_Confg2 : 27|4@0+ (1,0) [0|15] "unitless"  GWM
 SG_ CstmDrvMde3_No_Confg1 : 31|4@0+ (1,0) [0|15] "unitless"  GWM
 SG_ CstmDrvMde2_No_Confg2 : 19|4@0+ (1,0) [0|15] "unitless"  GWM
 SG_ CstmDrvMde2_No_Confg1 : 23|4@0+ (1,0) [0|15] "unitless"  GWM
 SG_ CstmDrvMde1_No_Confg2 : 11|4@0+ (1,0) [0|15] "unitless"  GWM
 SG_ CstmDrvMde1_No_Confg1 : 15|4@0+ (1,0) [0|15] "unitless"  GWM

BO_ 942 ParkAid_Data_3: 8 IPMA_ADAS
 SG_ PrkAidAcsyRear_D_Stat : 18|2@0+ (1,0) [0|3] "SED"  GWM
 SG_ PrkAidAcsyFront_D_Stat : 20|2@0+ (1,0) [0|3] "SED"  GWM
 SG_ PrkAidRdiusRight_L_Dsply : 15|8@0+ (1,0) [0|255] "unitless"  GWM
 SG_ PrkAidRdiusLeft_L_Dsply : 7|8@0+ (1,0) [0|255] "unitless"  GWM
 SG_ PrkAidDrvDir_D_Stat : 23|3@0+ (1,0) [0|7] "SED"  GWM

BO_ 123 Battery_Traction_2_FD1: 8 GWM
 SG_ BattTrac_U2_Actl : 21|12@0+ (0.5,0) [0|2046.5] "volt"  SOBDMC_HPCM_FD1,ECM_HEV,PCM_HEV
 SG_ BattTrac_I2_Actl : 7|18@0+ (0.05,-6553.52) [-6553.52|6553.53] "ampere"  ECM_HEV,PCM_HEV

BO_ 1053 Battery_Data1_FD1: 8 GWM
 SG_ BattAuxCnnct_D_Cmd : 7|3@0+ (1,0) [0|7] "SED"  SOBDMC_HPCM_FD1

BO_ 2612052184 PARSEDPushFcGWM_ECGtoPSCM: 64 GWM
 SG_ PARSEDPushFcGWM_ECGtoPSCM : 7|29@0+ (1,0) [0|536870911] "unitless"  PSCM

BO_ 2612224187 PARSEDPushFc_CMRtoGWM_ECG: 64 CMR_DSMC
 SG_ PARSEDPushFcCMRtoGWM_ECG : 7|29@0+ (1,0) [0|536870911] "unitless"  GWM

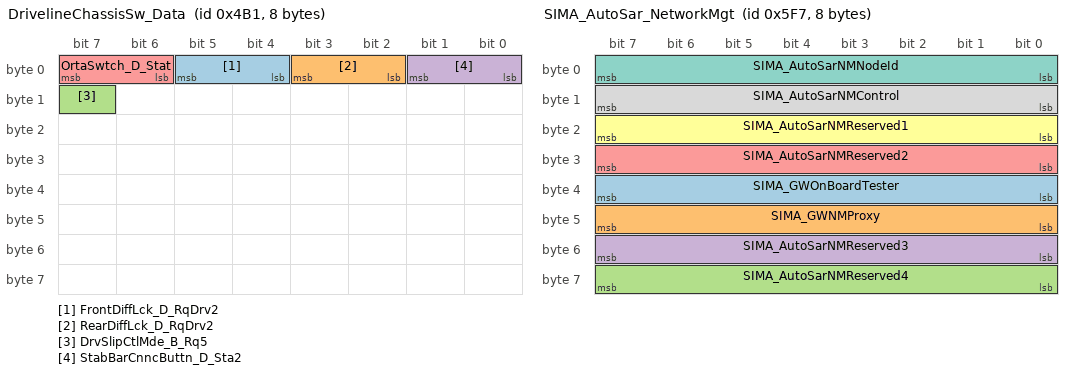
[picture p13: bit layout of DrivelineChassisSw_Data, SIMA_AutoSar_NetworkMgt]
BO_ 1201 DrivelineChassisSw_Data: 8 SIMA_DLCS
 SG_ FrontDiffLck_D_RqDrv2 : 5|2@0+ (1,0) [0|3] "SED"  GWM
 SG_ RearDiffLck_D_RqDrv2 : 3|2@0+ (1,0) [0|3] "SED"  GWM
 SG_ DrvSlipCtlMde_B_Rq5 : 15|1@0+ (1,0) [0|1] "SED"  GWM
 SG_ StabBarCnncButtn_D_Sta2 : 1|2@0+ (1,0) [0|3] "SED"  GWM
 SG_ OrtaSwtch_D_Stat : 7|2@0+ (1,0) [0|3] "SED"  ABS_ESC

BO_ 1912 TesterPhysicalResSIMA_DLCS: 64 SIMA_DLCS
 SG_ TesterPhysicalResSIMA : 7|64@0+ (1,0) [0|1.84467E+019] "unitless"  TSTR

BO_ 1904 TesterPhysicalReqSIMA_DLCS: 64 TSTR
 SG_ TesterPhysicalReqSIMA : 7|64@0+ (1,0) [0|1.84467E+019] "unitless"  SIMA_DLCS

BO_ 1527 SIMA_AutoSar_NetworkMgt: 8 SIMA_DLCS
 SG_ SIMA_GWOnBoardTester : 39|8@0+ (1,0) [0|255] "unitless"  GENERIC
 SG_ SIMA_GWNMProxy : 47|8@0+ (1,0) [0|255] "unitless"  GENERIC
 SG_ SIMA_AutoSarNMReserved4 : 63|8@0+ (1,0) [0|255] "unitless"  GENERIC
 SG_ SIMA_AutoSarNMReserved3 : 55|8@0+ (1,0) [0|255] "unitless"  GENERIC
 SG_ SIMA_AutoSarNMReserved2 : 31|8@0+ (1,0) [0|255] "unitless"  GENERIC
 SG_ SIMA_AutoSarNMReserved1 : 23|8@0+ (1,0) [0|255] "unitless"  GENERIC
 SG_ SIMA_AutoSarNMNodeId : 7|8@0+ (1,0) [0|255] "unitless"  GENERIC
 SG_ SIMA_AutoSarNMControl : 15|8@0+ (1,0) [0|255] "unitless"  GENERIC

BO_ 949 Tire_Pressure_Data_FD1: 8 GWM
 SG_ Tire_Press_RR_ORR_Data : 39|16@0+ (1,0) [0|65533] "kilopascal"  VDM
 SG_ Tire_Press_LR_OLR_Data : 55|16@0+ (1,0) [0|65533] "kilopascal"  VDM
 SG_ Tire_Press_LF_Data : 7|16@0+ (1,0) [0|65533] "kilopascal"  VDM
 SG_ Tire_Press_RF_Data : 23|16@0+ (1,0) [0|65533] "kilopascal"  VDM

BO_ 2612118744 PARSEDPushFcGWMtoHCM: 64 GWM
 SG_ PARSEDPushFcGWM_ECGtoHCM : 7|29@0+ (1,0) [0|536870911] "unitless"  HCM

BO_ 2612074712 PARSEDPushFcGWMtoSODCMD: 64 GWM
 SG_ PARSEDPushFcGWMtoSODCMD : 7|29@0+ (1,0) [0|536870911] "unitless"  IPMA_ADAS

BO_ 2612024536 PARSEDPushFcGWM_ECGtoCCM: 64 GWM
 SG_ PARSEDPushFcGWM_ECGtoCCM : 7|29@0+ (1,0) [0|536870911] "unitless"  IPMA_ADAS

BO_ 2612036824 PARSEDPushFcGWM_ECGtoIPMA: 64 GWM
 SG_ PARSEDPushFcGWM_ECGtoIPMA : 7|29@0+ (1,0) [0|536870911] "unitless"  IPMA_ADAS

BO_ 2612103384 PARSEDPushFcGWMtoSODL: 64 GWM
 SG_ PARSEDPushFcGWM_ECGtoSODL : 7|29@0+ (1,0) [0|536870911] "unitless"  IPMA_ADAS

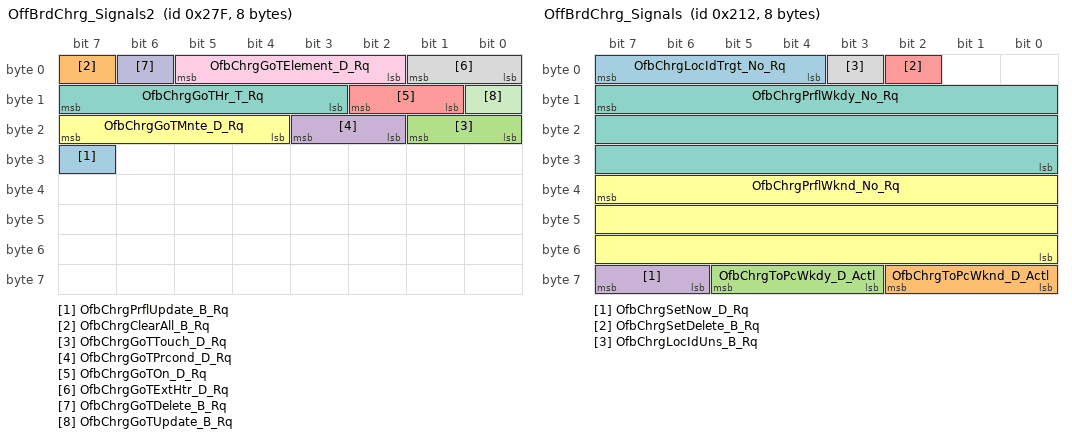
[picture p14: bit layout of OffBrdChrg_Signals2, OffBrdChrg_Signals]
BO_ 639 OffBrdChrg_Signals2: 8 GWM
 SG_ OfbChrgPrflUpdate_B_Rq : 31|1@0+ (1,0) [0|1] "SED"  SOBDMC_HPCM_FD1
 SG_ OfbChrgClearAll_B_Rq : 7|1@0+ (1,0) [0|1] "SED"  SOBDMC_HPCM_FD1
 SG_ OfbChrgGoTTouch_D_Rq : 17|2@0+ (1,0) [0|3] "SED"  SOBDMC_HPCM_FD1
 SG_ OfbChrgGoTPrcond_D_Rq : 19|2@0+ (1,0) [0|3] "SED"  SOBDMC_HPCM_FD1
 SG_ OfbChrgGoTOn_D_Rq : 10|2@0+ (1,0) [0|3] "SED"  SOBDMC_HPCM_FD1
 SG_ OfbChrgGoTMnte_D_Rq : 23|4@0+ (1,0) [0|15] "minute"  SOBDMC_HPCM_FD1
 SG_ OfbChrgGoTHr_T_Rq : 15|5@0+ (1,0) [0|29] "hour"  SOBDMC_HPCM_FD1
 SG_ OfbChrgGoTExtHtr_D_Rq : 1|2@0+ (1,0) [0|3] "SED"  SOBDMC_HPCM_FD1
 SG_ OfbChrgGoTElement_D_Rq : 5|4@0+ (1,0) [0|15] "Unitless"  SOBDMC_HPCM_FD1
 SG_ OfbChrgGoTDelete_B_Rq : 6|1@0+ (1,0) [0|1] "SED"  SOBDMC_HPCM_FD1
 SG_ OfbChrgGoTUpdate_B_Rq : 8|1@0+ (1,0) [0|1] "SED"  SOBDMC_HPCM_FD1

BO_ 530 OffBrdChrg_Signals: 8 GWM
 SG_ OfbChrgLocIdTrgt_No_Rq : 7|4@0+ (1,0) [0|15] "Unitless"  SOBDMC_HPCM_FD1
 SG_ OfbChrgToPcWknd_D_Actl : 58|3@0+ (1,0) [0|7] "percent"  SOBDMC_HPCM_FD1
 SG_ OfbChrgToPcWkdy_D_Actl : 61|3@0+ (1,0) [0|7] "percent"  SOBDMC_HPCM_FD1
 SG_ OfbChrgSetNow_D_Rq : 63|2@0+ (1,0) [0|3] "SED"  SOBDMC_HPCM_FD1
 SG_ OfbChrgSetDelete_B_Rq : 2|1@0+ (1,0) [0|1] "SED"  SOBDMC_HPCM_FD1
 SG_ OfbChrgPrflWknd_No_Rq : 39|24@0+ (1,0) [0|16777215] "unitless"  SOBDMC_HPCM_FD1
 SG_ OfbChrgPrflWkdy_No_Rq : 15|24@0+ (1,0) [0|16777215] "unitless"  SOBDMC_HPCM_FD1
 SG_ OfbChrgLocIdUns_B_Rq : 3|1@0+ (1,0) [0|1] "SED"  SOBDMC_HPCM_FD1

BO_ 550 ECG_Data4_FD1: 8 GWM
 SG_ PtWakeupActv1_B_Rq : 7|1@0+ (1,0) [0|1] "SED"  SOBDMC_HPCM_FD1

BO_ 879 BCMC_Data_FD1: 8 GWM
 SG_ WndwRearHeat_I_Actl : 7|11@0+ (0.1,0) [0|204.6] "ampere"  ECM_Diesel,ECM_HEVDSL
 SG_ WndwRearHeat_D_Stat : 12|3@0+ (1,0) [0|7] "SED"  ECM_Diesel,ECM_HEVDSL

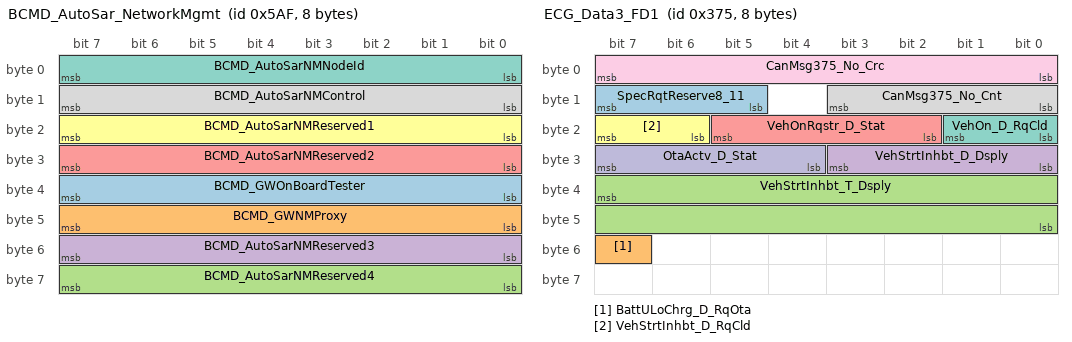
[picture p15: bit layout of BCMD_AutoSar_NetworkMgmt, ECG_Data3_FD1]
BO_ 1455 BCMD_AutoSar_NetworkMgmt: 8 BCMD_IPDB
 SG_ BCMD_GWOnBoardTester : 39|8@0+ (1,0) [0|255] "unitless"  GENERIC
 SG_ BCMD_GWNMProxy : 47|8@0+ (1,0) [0|255] "unitless"  GENERIC
 SG_ BCMD_AutoSarNMReserved4 : 63|8@0+ (1,0) [0|255] "unitless"  GENERIC
 SG_ BCMD_AutoSarNMReserved3 : 55|8@0+ (1,0) [0|255] "unitless"  GENERIC
 SG_ BCMD_AutoSarNMReserved2 : 31|8@0+ (1,0) [0|255] "unitless"  GENERIC
 SG_ BCMD_AutoSarNMReserved1 : 23|8@0+ (1,0) [0|255] "unitless"  GENERIC
 SG_ BCMD_AutoSarNMNodeId : 7|8@0+ (1,0) [0|255] "unitless"  GENERIC
 SG_ BCMD_AutoSarNMControl : 15|8@0+ (1,0) [0|255] "unitless"  GENERIC

BO_ 1775 TesterPhysicalResBCMD_IPDB: 64 BCMD_IPDB
 SG_ TesterPhysicalResBCMD_IPDB : 7|64@0+ (1,0) [0|1.84467E+019] "unitless"  TSTR

BO_ 1767 TesterPhysicalReqBCMD_IPDB: 64 TSTR
 SG_ TesterPhysicalReqBCMD_IPDB : 7|64@0+ (1,0) [0|1.84467E+019] "unitless"  BCMD_IPDB

BO_ 2612019416 PARSEDPushFcGWM_ECGtoPCM: 64 GWM
 SG_ PARSEDPushFcGWM_ECGtoPCM : 7|29@0+ (1,0) [0|536870911] "unitless"  SOBDMC_HPCM_FD1,ECM,ECM_Diesel,ECM_HEV,ECM_HEVDSL,PCM,PCM_HEV

BO_ 885 ECG_Data3_FD1: 8 GWM
 SG_ SpecRqtReserve8_11 : 15|3@0+ (1,0) [0|7] "unitless"  GENERIC
 SG_ BattULoChrg_D_RqOta : 55|1@0+ (1,0) [0|1] "SED"  GENERIC
 SG_ VehStrtInhbt_T_Dsply : 39|16@0+ (1,0) [0|65535] "second"  GENERIC
 SG_ VehStrtInhbt_D_Dsply : 27|4@0+ (1,0) [0|15] "SED"  GENERIC
 SG_ VehOnRqstr_D_Stat : 21|4@0+ (1,0) [0|15] "SED"  GENERIC
 SG_ VehStrtInhbt_D_RqCld : 23|2@0+ (1,0) [0|3] "SED"  GENERIC
 SG_ VehOn_D_RqCld : 17|2@0+ (1,0) [0|3] "SED"  GENERIC
 SG_ CanMsg375_No_Cnt : 11|4@0+ (1,0) [0|15] "unitless"  GENERIC
 SG_ CanMsg375_No_Crc : 7|8@0+ (1,0) [0|255] "unitless"  GENERIC
 SG_ OtaActv_D_Stat : 31|4@0+ (1,0) [0|15] "SED"  AWD_DLCM,TCM,TCM_DSL

BO_ 2612104408 PARSEDPushFcGWMtoSODR: 64 GWM
 SG_ PARSEDPushFcGWM_ECGtoSODR : 7|29@0+ (1,0) [0|536870911] "unitless"  IPMA_ADAS

BO_ 2612020440 PARSEDPushFcGWMtoSOBDMCFD1: 64 GWM
 SG_ PARSEDPushFcGWMtoSOBDMC : 7|29@0+ (1,0) [0|536870911] "unitless"  SOBDMC_HPCM_FD1

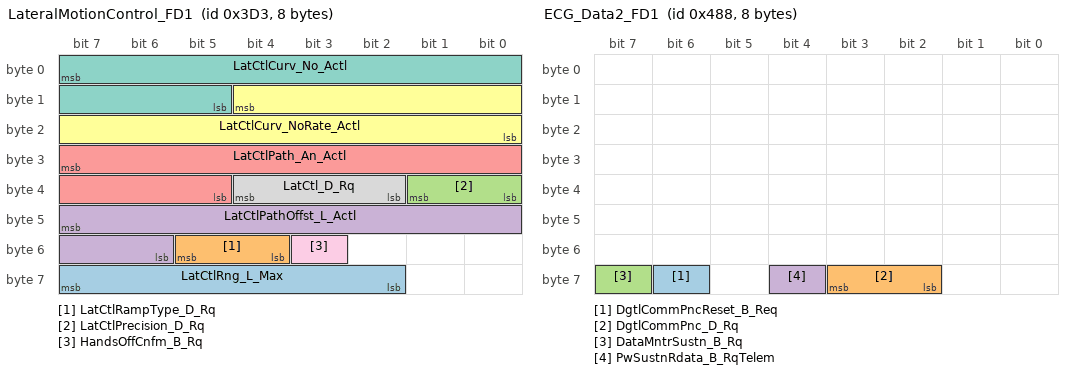
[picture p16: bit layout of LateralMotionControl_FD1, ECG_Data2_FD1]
BO_ 979 LateralMotionControl_FD1: 8 GWM
 SG_ LatCtlRng_L_Max : 63|6@0+ (2,0) [0|126] "meter"  PSCM
 SG_ LatCtlRampType_D_Rq : 53|2@0+ (1,0) [0|3] "SED"  PSCM
 SG_ LatCtlPrecision_D_Rq : 33|2@0+ (1,0) [0|3] "SED"  PSCM
 SG_ LatCtlPathOffst_L_Actl : 47|10@0+ (0.01,-5.12) [-5.12|5.11] "meter"  PSCM
 SG_ LatCtlPath_An_Actl : 31|11@0+ (0.0005,-0.5) [-0.5|0.5235] "radians"  PSCM
 SG_ LatCtlCurv_NoRate_Actl : 12|13@0+ (2.5E-007,-0.001024) [-0.001024|0.00102375] "1/meter"  PSCM
 SG_ LatCtlCurv_No_Actl : 7|11@0+ (2E-005,-0.02) [-0.02|0.02094] "1/meter"  PSCM
 SG_ LatCtl_D_Rq : 36|3@0+ (1,0) [0|7] "SED"  PSCM
 SG_ HandsOffCnfm_B_Rq : 51|1@0+ (1,0) [0|1] "SED"  PSCM

BO_ 739 HMI_Send_Signals_7_FD1: 8 GWM
 SG_ Partial_Amp_Shutdown : 15|1@0+ (1,0) [0|1] "SED"  GENERIC
 SG_ HMI_HMIMode_St : 2|3@0+ (1,0) [0|7] "SED"  PCM

BO_ 1160 ECG_Data2_FD1: 8 GWM
 SG_ DgtlCommPncReset_B_Req : 62|1@0+ (1,0) [0|1] "SED"  GENERIC
 SG_ DgtlCommPnc_D_Rq : 59|2@0+ (1,0) [0|3] "SED"  GENERIC
 SG_ DataMntrSustn_B_Rq : 63|1@0+ (1,0) [0|1] "SED"  ECM_HEV,PCM_HEV
 SG_ PwSustnRdata_B_RqTelem : 60|1@0+ (1,0) [0|1] "SED"  ECM_HEV,PCM_HEV

BO_ 1825 TesterPhysicalReqVDM_FD1: 64 TSTR
 SG_ TesterPhysicalReqVDM : 7|64@0+ (1,0) [0|1.84467E+019] "unitless"  VDM

BO_ 1001 Personality_SUMA_Data_FD1: 8 GWM
 SG_ AirSuspMsgTxt_D_Rq2 : 36|2@0+ (1,0) [0|3] "SED"  VDM
 SG_ PersIndexSuma_D_Actl : 39|3@0+ (1,0) [0|7] "SED"  GENERIC
 SG_ FeatNoSumaActl : 23|16@0+ (1,0) [0|65535] "Number"  GENERIC
 SG_ FeatConfigSumaActl : 7|16@0+ (1,0) [0|65535] "Undefined"  GENERIC

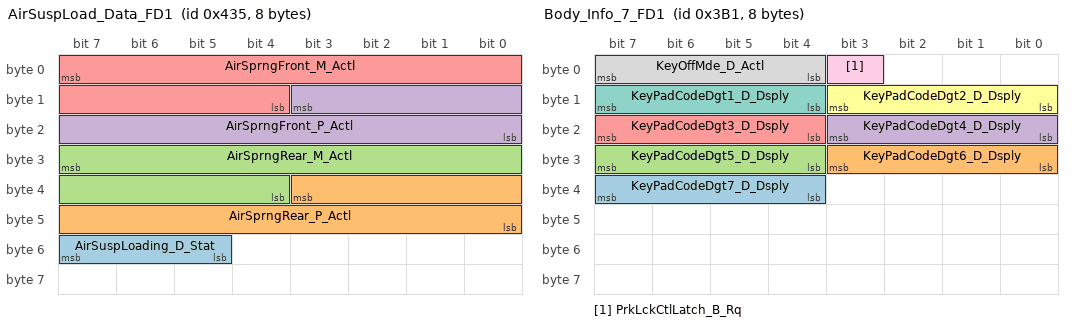
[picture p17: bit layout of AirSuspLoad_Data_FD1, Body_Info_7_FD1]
BO_ 1077 AirSuspLoad_Data_FD1: 8 GWM
 SG_ AirSuspLoading_D_Stat : 55|3@0+ (1,0) [0|7] "SED"  VDM
 SG_ AirSprngRear_P_Actl : 35|12@0+ (0.01,-5.92) [-5.92|35.02] "bar"  VDM
 SG_ AirSprngRear_M_Actl : 31|12@0+ (1,0) [0|4094] "kilogram"  VDM
 SG_ AirSprngFront_P_Actl : 11|12@0+ (0.01,-5.92) [-5.92|35.02] "bar"  VDM
 SG_ AirSprngFront_M_Actl : 7|12@0+ (1,0) [0|4094] "kilogram"  VDM

BO_ 945 Body_Info_7_FD1: 8 GWM
 SG_ KeyPadCodeDgt7_D_Dsply : 39|4@0+ (1,0) [0|15] "SED"  GENERIC
 SG_ KeyPadCodeDgt6_D_Dsply : 27|4@0+ (1,0) [0|15] "SED"  GENERIC
 SG_ KeyPadCodeDgt5_D_Dsply : 31|4@0+ (1,0) [0|15] "SED"  GENERIC
 SG_ KeyPadCodeDgt4_D_Dsply : 19|4@0+ (1,0) [0|15] "SED"  GENERIC
 SG_ KeyPadCodeDgt3_D_Dsply : 23|4@0+ (1,0) [0|15] "SED"  GENERIC
 SG_ KeyPadCodeDgt2_D_Dsply : 11|4@0+ (1,0) [0|15] "SED"  GENERIC
 SG_ KeyPadCodeDgt1_D_Dsply : 15|4@0+ (1,0) [0|15] "SED"  GENERIC
 SG_ KeyOffMde_D_Actl : 7|4@0+ (1,0) [0|15] "SED"  VDM
 SG_ PrkLckCtlLatch_B_Rq : 3|1@0+ (1,0) [0|1] "SED"  GENERIC

BO_ 2612073688 PARSEDPushFcGWMtoSODCMC: 64 GWM
 SG_ PARSEDPushFcGWMtoSODCMC : 7|29@0+ (1,0) [0|536870911] "unitless"  IPMA_ADAS

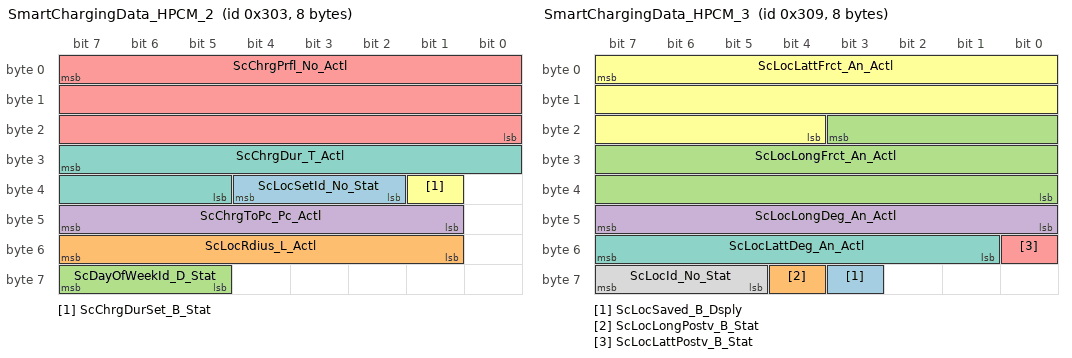
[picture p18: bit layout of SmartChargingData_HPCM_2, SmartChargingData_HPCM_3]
BO_ 771 SmartChargingData_HPCM_2: 8 SOBDMC_HPCM_FD1
 SG_ ScLocSetId_No_Stat : 36|3@0+ (1,0) [0|7] "unitless"  GWM
 SG_ ScLocRdius_L_Actl : 55|7@0+ (100,0) [0|12700] "meter"  GWM
 SG_ ScDayOfWeekId_D_Stat : 63|3@0+ (1,0) [0|7] "SED"  GWM
 SG_ ScChrgToPc_Pc_Actl : 47|7@0+ (1,0) [0|127] "percent"  GWM
 SG_ ScChrgPrfl_No_Actl : 7|24@0+ (1,0) [0|16777215] "unitless"  GWM
 SG_ ScChrgDurSet_B_Stat : 33|1@0+ (1,0) [0|1] "SED"  GWM
 SG_ ScChrgDur_T_Actl : 31|11@0+ (1,0) [0|2047] "minute"  GWM

BO_ 777 SmartChargingData_HPCM_3: 8 SOBDMC_HPCM_FD1
 SG_ ScLocSaved_B_Dsply : 59|1@0+ (1,0) [0|1] "SED"  GWM
 SG_ ScLocLongPostv_B_Stat : 60|1@0+ (1,0) [0|1] "SED"  GWM
 SG_ ScLocLongFrct_An_Actl : 19|20@0+ (1E-006,0) [0|1.048575] "degrees"  GWM
 SG_ ScLocLongDeg_An_Actl : 47|8@0+ (1,0) [0|255] "degrees"  GWM
 SG_ ScLocLattPostv_B_Stat : 48|1@0+ (1,0) [0|1] "SED"  GWM
 SG_ ScLocLattFrct_An_Actl : 7|20@0+ (1E-006,0) [0|1.048575] "degrees"  GWM
 SG_ ScLocLattDeg_An_Actl : 55|7@0+ (1,0) [0|127] "degrees"  GWM
 SG_ ScLocId_No_Stat : 63|3@0+ (1,0) [0|7] "unitless"  GWM

BO_ 1043 ABS_BrkData: 8 ABS_ESC
 SG_ SelDrvMdeHmi02_D_Rq : 47|5@0+ (1,0) [0|31] "SED"  GWM
 SG_ SelDrvMdeHmi04_D_Rq : 55|5@0+ (1,0) [0|31] "SED"  GWM
 SG_ IndvMdeSusp_No_Stat : 27|4@0+ (1,0) [0|15] "unitless"  GWM
 SG_ IndvMdeSte_No_Stat : 31|4@0+ (1,0) [0|15] "unitless"  GWM
 SG_ IndvMdeSel_No_Rq : 19|4@0+ (1,0) [0|15] "unitless"  GWM
 SG_ IndvMdeSel_D_Stat : 9|2@0+ (1,0) [0|3] "SED"  GWM
 SG_ IndvMdeMsgTxt_D_Rq : 23|4@0+ (1,0) [0|15] "SED"  GWM
 SG_ IndvMde5_B_Avail : 35|1@0+ (1,0) [0|1] "SED"  GWM
 SG_ IndvMde4_B_Avail : 36|1@0+ (1,0) [0|1] "SED"  GWM
 SG_ IndvMde3_B_Avail : 37|1@0+ (1,0) [0|1] "SED"  GWM
 SG_ IndvMde2_B_Avail : 38|1@0+ (1,0) [0|1] "SED"  GWM
 SG_ IndvMde1_B_Avail : 39|1@0+ (1,0) [0|1] "SED"  GWM
 SG_ TrailOnePdlMde_D_Ind : 15|3@0+ (1,0) [0|7] "SED"  GWM
 SG_ TrailOnePdlMsgTxt_D_Rq : 12|3@0+ (1,0) [0|7] "SED"  GWM
 SG_ OrtaSwtchLamp_B_Rq : 0|1@0+ (1,0) [0|1] "SED"  SIMA_DLCS,GWM
 SG_ OrtaMsgTxt_D_Rq : 4|4@0+ (1,0) [0|15] "SED"  GWM
 SG_ OrtaMde_D_Ind : 7|3@0+ (1,0) [0|7] "SED"  GWM

BO_ 1833 TesterPhysicalResVDM: 64 VDM
 SG_ TesterPhysicalResVDM : 7|64@0+ (1,0) [0|1.84467E+019] "unitless"  TSTR

BO_ 991 Personality_VDM_Data: 8 VDM
 SG_ PersIndexVdm_D_Actl : 39|3@0+ (1,0) [0|7] "SED"  GWM
 SG_ FeatNoVdmActl : 23|16@0+ (1,0) [0|65535] "Number"  GWM
 SG_ FeatConfigVdmActl : 7|16@0+ (1,0) [0|65535] "Undefined"  GWM

BO_ 395 HeadUpDisplayReq_FD1: 8 GWM
 SG_ SelDrvMdeCnfm_D_Stat : 35|2@0+ (1,0) [0|3] "SED"  ABS_ESC
 SG_ HudShifPoint_N_Rq : 29|6@0+ (100,2000) [2000|8300] "rpm"  GENERIC
 SG_ HudMde_D_Rq : 38|3@0+ (1,0) [0|7] "SED"  GENERIC
 SG_ HudLedMde_D_Rq : 31|2@0+ (1,0) [0|3] "SED"  GENERIC
 SG_ HudLedIntns_Pc_Rq : 22|7@0+ (1,0) [0|127] "percent"  GENERIC
 SG_ HudLed9On_B_Rq : 15|1@0+ (1,0) [0|1] "SED"  GENERIC
 SG_ HudLed8On_B_Rq : 0|1@0+ (1,0) [0|1] "SED"  GENERIC
 SG_ HudLed7On_B_Rq : 1|1@0+ (1,0) [0|1] "SED"  GENERIC
 SG_ HudLed6On_B_Rq : 2|1@0+ (1,0) [0|1] "SED"  GENERIC
 SG_ HudLed5On_B_Rq : 3|1@0+ (1,0) [0|1] "SED"  GENERIC
 SG_ HudLed4On_B_Rq : 4|1@0+ (1,0) [0|1] "SED"  GENERIC
 SG_ HudLed3On_B_Rq : 5|1@0+ (1,0) [0|1] "SED"  GENERIC
 SG_ HudLed2On_B_Rq : 6|1@0+ (1,0) [0|1] "SED"  GENERIC
 SG_ HudLed1On_B_Rq : 7|1@0+ (1,0) [0|1] "SED"  GENERIC
 SG_ HudLed18On_B_Rq : 39|1@0+ (1,0) [0|1] "SED"  GENERIC
 SG_ HudLed17On_B_Rq : 23|1@0+ (1,0) [0|1] "SED"  GENERIC
 SG_ HudLed16On_B_Rq : 8|1@0+ (1,0) [0|1] "SED"  GENERIC
 SG_ HudLed15On_B_Rq : 9|1@0+ (1,0) [0|1] "SED"  GENERIC
 SG_ HudLed14On_B_Rq : 10|1@0+ (1,0) [0|1] "SED"  GENERIC
 SG_ HudLed13On_B_Rq : 11|1@0+ (1,0) [0|1] "SED"  GENERIC
 SG_ HudLed12On_B_Rq : 12|1@0+ (1,0) [0|1] "SED"  GENERIC
 SG_ HudLed11On_B_Rq : 13|1@0+ (1,0) [0|1] "SED"  GENERIC
 SG_ HudLed10On_B_Rq : 14|1@0+ (1,0) [0|1] "SED"  GENERIC

BO_ 542 LocationServices_3_FD1: 8 GWM
 SG_ LocationServices_3 : 7|64@0+ (1,0) [0|1.84467440737096E+019] "unitless"  SOBDMC_HPCM_FD1

BO_ 1689 AWD_Rapid_Data_Response_2: 8 AWD_DLCM
 SG_ UUDTAWDResponse2 : 7|64@0+ (1,0) [0|1.84467440737096E+019] "unitless"  TSTR

BO_ 515 PowertrainData_12: 8 SOBDMC_HPCM_FD1
 SG_ PtIgnSwtch_D_Stat : 7|2@0+ (1,0) [0|3] "SED"  GWM

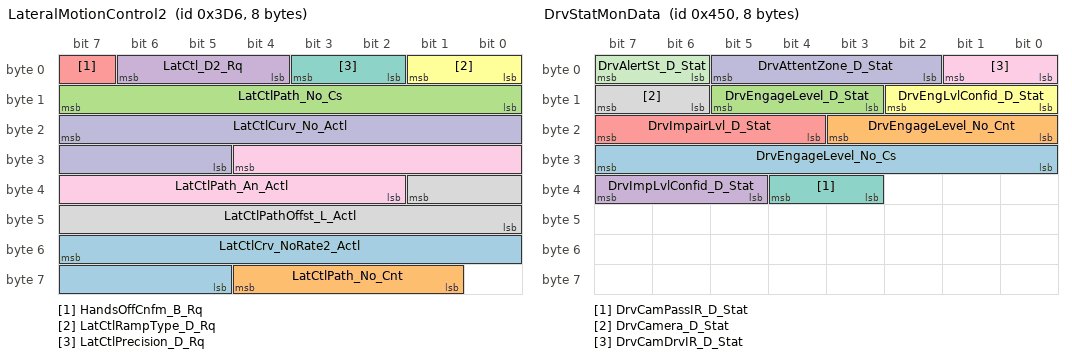
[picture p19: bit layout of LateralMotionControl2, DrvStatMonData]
BO_ 982 LateralMotionControl2: 8 IPMA_ADAS
 SG_ LatCtlCrv_NoRate2_Actl : 55|11@0+ (1E-006,-0.001024) [-0.001024|0.001023] "meter^2"  PSCM
 SG_ LatCtlPath_No_Cnt : 60|4@0+ (1,0) [0|15] "Unitless"  PSCM
 SG_ LatCtlPath_No_Cs : 15|8@0+ (1,0) [0|255] "Unitless"  PSCM
 SG_ LatCtl_D2_Rq : 6|3@0+ (1,0) [0|7] "SED"  PSCM
 SG_ HandsOffCnfm_B_Rq : 7|1@0+ (1,0) [0|1] "SED"  PSCM
 SG_ LatCtlRampType_D_Rq : 1|2@0+ (1,0) [0|3] "SED"  PSCM
 SG_ LatCtlPrecision_D_Rq : 3|2@0+ (1,0) [0|3] "SED"  PSCM
 SG_ LatCtlPathOffst_L_Actl : 33|10@0+ (0.01,-5.12) [-5.12|5.11] "meter"  PSCM
 SG_ LatCtlPath_An_Actl : 28|11@0+ (0.0005,-0.5) [-0.5|0.5235] "radians"  PSCM
 SG_ LatCtlCurv_No_Actl : 23|11@0+ (2E-005,-0.02) [-0.02|0.02094] "1/meter"  PSCM

BO_ 1104 DrvStatMonData: 8 CMR_DSMC
 SG_ DrvEngageLevel_No_Cs : 31|8@0+ (1,0) [0|255] "Unitless"  IPMA_ADAS
 SG_ DrvEngageLevel_No_Cnt : 19|4@0+ (1,0) [0|15] "Unitless"  IPMA_ADAS
 SG_ DrvEngageLevel_D_Stat : 13|3@0+ (1,0) [0|7] "SED"  IPMA_ADAS
 SG_ DrvImpLvlConfid_D_Stat : 39|3@0+ (1,0) [0|7] "SED"  IPMA_ADAS
 SG_ DrvImpairLvl_D_Stat : 23|4@0+ (1,0) [0|15] "SED"  IPMA_ADAS
 SG_ DrvEngLvlConfid_D_Stat : 10|3@0+ (1,0) [0|7] "SED"  IPMA_ADAS
 SG_ DrvCamPassIR_D_Stat : 36|2@0+ (1,0) [0|3] "SED"  IPMA_ADAS
 SG_ DrvCamera_D_Stat : 15|2@0+ (1,0) [0|3] "SED"  IPMA_ADAS
 SG_ DrvCamDrvIR_D_Stat : 1|2@0+ (1,0) [0|3] "SED"  IPMA_ADAS
 SG_ DrvAttentZone_D_Stat : 5|4@0+ (1,0) [0|15] "SED"  IPMA_ADAS
 SG_ DrvAlertSt_D_Stat : 7|2@0+ (1,0) [0|3] "SED"  IPMA_ADAS

BO_ 829 Low_Voltage_Power_Dat2_FD1: 8 GWM
 SG_ PwSrcULoMde2_D_Actl : 12|2@0+ (1,0) [0|3] "SED"  SOBDMC_HPCM_FD1,ECM_HEV,ECM_HEVDSL,PCM_HEV
 SG_ DcdcUHi3_I_Actl : 7|11@0+ (0.1,0) [0|204.5] "ampere"  ECM_HEV,ECM_HEVDSL,PCM_HEV,SOBDMC_HPCM_FD1

BO_ 2611070168 PARSEDPhysGWM_ECGtoHCM: 64 GWM
 SG_ PARSEDPhysGWM_ECGtoHCM : 7|29@0+ (1,0) [0|536870911] "unitless"  HCM,GENERIC

BO_ 2611175537 PARSEDPhysHCMtoGWM_ECG: 64 HCM
 SG_ PARSEDPhysHCMtoGWM_ECG : 7|29@0+ (1,0) [0|536870911] "unitless"  GWM

BO_ 2612224113 PARSEDPushHCMtoGWM_ECG: 64 HCM
 SG_ PARSEDPushHCMtoGWM_ECG : 7|29@0+ (1,0) [0|536870911] "unitless"  GWM

BO_ 2610021592 OTAPhysGWM_ECGtoHCM: 64 GWM
 SG_ OTAPhysGWM_ECGtoHCM : 7|29@0+ (1,0) [0|536870911] "unitless"  HCM,GENERIC

BO_ 2610126961 OTAPhysHCMtoGWM_ECG: 64 HCM
 SG_ OTAPhysHCMtoGWM_ECG : 7|29@0+ (1,0) [0|536870911] "unitless"  GWM

BO_ 2610975960 PARSEDPhysGWM_ECGtoCCM: 64 GWM
 SG_ PARSEDPhysGWM_ECGtoCCM : 7|29@0+ (1,0) [0|536870911] "unitless"  IPMA_ADAS

BO_ 2611175445 PARSEDPhysCCMtoGWM_ECG: 64 IPMA_ADAS
 SG_ PARSEDPhysCCMtoGWM_ECG : 7|29@0+ (1,0) [0|536870911] "unitless"  GWM

BO_ 2612224021 PARSEDPushCCMtoGWM_ECG: 64 IPMA_ADAS
 SG_ PARSEDPushCCMtoGWM_ECG : 7|29@0+ (1,0) [0|536870911] "unitless"  GWM

BO_ 2611025112 PARSEDPhysGWM_ECGtoSODCMC: 64 GWM
 SG_ PARSEDPhysGWM_ECGtoSODCMC : 7|29@0+ (1,0) [0|536870911] "unitless"  IPMA_ADAS

BO_ 2611175493 PARSEDPhysSODCMCtoGWM_ECG: 64 IPMA_ADAS
 SG_ PARSEDPhysSODCMCtoGWM_ECG : 7|29@0+ (1,0) [0|536870911] "unitless"  GWM

BO_ 2612224069 PARSEDPushSODCMCtoGWM: 64 IPMA_ADAS
 SG_ PARSEDPushSODCMCtoGWM : 7|29@0+ (1,0) [0|536870911] "unitless"  GWM

CM_ SG_ 1069 SlMde_D_Stat "IPC and HUD_ADV Receve from HS3 FGW 0x42D, not HS3 0x38A, MSG DCR 506.";
CM_ SG_ 1069 SlMde_D_RqDsply "IPC and HUD_ADV Receve from HS3 FGW 0x42D, not HS3 0x38A, MSG DCR 506.";
CM_ SG_ 1069 ObdWarmUp_B_Complt "Signal not transmitted on gas and diesel variants.";
CM_ SG_ 1069 EngMsgTxt_D_Rq "Signal not transmitted on diesel variants.";
CM_ SG_ 1069 EngClnt_Te_ActlDiag "Signal not transmitted on gas variants.";
CM_ SG_ 1069 EngLoad_Pc_CalcDiag "Signal not transmitted on gas variants.";
CM_ SG_ 1069 ApedPos_Pc_ActlDiag "Signal not transmitted on gas variants.";
CM_ SG_ 1057 FohEng_D_Rq "Signal not transmitted on vehicles that do not have the fuel operated heater feature.";
CM_ SG_ 1057 EngIdlShutDown_D_Stat "Signal not transmitted on diesel variants.";
CM_ SG_ 1057 FUEL_ALCOHOL_PERCNT "signal not transmitted on diesel and HEV variants.";
CM_ SG_ 1057 TrnTotTq_Rt_Est "Signal not transmitted on gas and HEV variants.";
CM_ SG_ 1057 TrnTotLss_Tq_Est "Signal not transmitted on gas and HEV variants.";
CM_ SG_ 1057 VehVLimStat_D_Actl "Signal not transmitted on gas and HEV variants.";
CM_ SG_ 1057 VehVLimActv_B_Actl "Signal not transmitted on gas and HEV variants.";
CM_ SG_ 562 GearNtrl_No_Cs "Powersplit HEVs with HF45, HPCM will Tx  this message.  For all other programs it will be Tx by PCM or TCM. ";
CM_ SG_ 562 GearNtrl_No_Cnt "Powersplit HEVs with HF45, HPCM will Tx  this message.  For all other programs it will be Tx by PCM or TCM. ";
CM_ SG_ 516 EngAout3_N_Actl "Signal not transmitted on gas and diesel variants.";
CM_ SG_ 516 ApedPos_Pc_ActlArb "ABSGenSigTimeoutTime=1000";
CM_ SG_ 516 ApedPosPcActl_No_Cnt "Signal not transmitted on gas and diesel variants.";
CM_ SG_ 516 ApedPosPcActl_No_Cs "Signal not transmitted on gas and diesel variants.";
CM_ SG_ 514 EngAout_Tq_VacLimSpcN "Signal not transmitted on gas and diesel variances.";
CM_ SG_ 514 EngCylSync_No_Ctr "Signal not transmitted on gas and diesel variances.";
CM_ SG_ 514 GearRvrse_D_Actl "Do not implement GearRvrse_D_Actl  until eTracker 8804151 is approved, 11/24/09";
CM_ SG_ 512 PrplWhlTotTqRq_No_Cs "Signal not transmitted on gas variants.";
CM_ SG_ 512 PrplWhlTotTqRq_No_Cnt "Signal not transmitted on gas variants.";
CM_ SG_ 512 EngAout_Tq_MxMxN "Signal not transmitted on gas variants.";
CM_ BO_ 382 "ECM, PCM Gas Only msg";
CM_ SG_ 377 EngFuelCutFull_B_Inhbt "Signal not transmitted on diesel variants.";
CM_ SG_ 377 FuelFlw_Vl_Dsply "Signal not transmitted on diesel variants.";
CM_ SG_ 377 FuelFillInlet_B_Dsply "Signal not transmitted on diesel variants.";
CM_ SG_ 377 OdoCount "Signal not transmitted on diesel variants.";
CM_ SG_ 377 EngOilLife_Pc_Actl "Signal not transmitted on diesel variants.";
CM_ SG_ 377 TrnKickDown_B_RqDrv "Signal not transmitted on diesel variants.";
CM_ SG_ 377 AirCondRec_B_Rq "Signal not transmitted on diesel variants.";
CM_ SG_ 377 AirCondClutch_B_Stats "Signal not transmitted on diesel variants.";
CM_ SG_ 376 EngAout_Aa_Actl "Signal not transmitted on HEV variants.";
CM_ SG_ 373 EngFuelCutFull_B_Allw "Signal not transmitted on diesel variances.";
CM_ SG_ 373 EngAout_Tq_MxActlN "Signal not transmitted on diesel variances.";
CM_ SG_ 359 TrnAin_Tq_Actl "Signal not transmitted on HEV variances.";
CM_ SG_ 359 PlgActvArb_B_Actl "Only supported on PHEV programs.  PlgActvArb_B_Actl HPCM will Tx on Powersplit PHEV’s,  On MHT PHEVs the PCM_HEV will Tx and HPCM will Rx. 
";
CM_ SG_ 359 TrnAinTq_D_Qf "Signal not transmitted on HEV variances.";
CM_ SG_ 358 HiElPwInhbt_B_Stat "Signal not transmitted on HEV programs";
CM_ SG_ 358 AutoStopPtDelta_I_Est "Signal not transmitted on vehicles that do not have autostop/stop-start feature.";
CM_ SG_ 357 BpedDrvAppl_D_Actl "CCMGenSigTimeoutTime=1000";
CM_ SG_ 357 CcStat_D_Actl "ABSGenSigTimeoutTime=1000";
CM_ SG_ 357 AccStopMde_D_Rq "ABSGenSigTimeoutTime=1000";
CM_ SG_ 342 EngOvrhtMitgActv_D_Ind "Signal not transmitted on diesel.";
CM_ SG_ 342 EngGoutLss_Tq_Est "Signal not transmitted on gas and diesel variants.";
CM_ BO_ 71 "Provide target function info. to control function of PATS";
CM_ SG_ 942 PrkAidRdiusRight_L_Dsply "MSGDCR 679, set all signals to OnChange";
CM_ SG_ 942 PrkAidRdiusLeft_L_Dsply "MSGDCR 679, set all signals to OnChange";
CM_ SG_ 942 PrkAidDrvDir_D_Stat "MSGDCR 679, set all signals to OnChange";
CM_ BO_ 949 "For 2010MY and beyond, use for SCT (non-CGEA) and CGEA modules";
CM_ SG_ 550 PtWakeupActv1_B_Rq "ECG Application signal";
CM_ BO_ 885 "NOTE: START BITS 8-11 MUST BE OPEN SPEC REQUIREMENT";
CM_ BO_ 739 "FCDIM Tx";
CM_ SG_ 739 Partial_Amp_Shutdown "Method Partial_Amp_Shutdown";
CM_ SG_ 739 HMI_HMIMode_St "Object ACU System Master.HMIMode
OR
Object NAV System Master.HMIMode
Refer Method HMIAudioMode in the SPSS";
CM_ SG_ 542 LocationServices_3 "Tx by HS3 APIM";
CM_ SG_ 982 LatCtlPath_No_Cnt "Signal not transmitted on gas variants.";
CM_ SG_ 982 LatCtlPath_No_Cs "Signal not transmitted on gas variants.";
CM_ SG_ 1104 DrvEngageLevel_No_Cs "Signal not transmitted on gas variants.";
CM_ SG_ 1104 DrvEngageLevel_No_Cnt "Signal not transmitted on gas variants.";
BA_DEF_ BO_  "VFrameFormat" ENUM  "StandardCAN","ExtendedCAN","reserved","reserved","reserved","reserved","reserved","reserved","reserved","reserved","reserved","reserved","reserved","reserved","StandardCAN_FD","ExtendedCAN_FD";
BA_DEF_ BO_  "DiagConnection" INT 0 256;
BA_DEF_ BO_  "FrameRouting" STRING ;
BA_DEF_ BO_  "FrameGatewayNetwork" STRING ;
BA_DEF_ BO_  "NetworkInitialization" ENUM  "No","Yes";
BA_DEF_ BO_  "FrameGatewayId" HEX 0 1407;
BA_DEF_ BO_  "EventRateOfChange" INT 10 10000;
BA_DEF_ BO_  "GenMsgStartDelayTime" INT 0 10000;
BA_DEF_ BO_  "GenMsgNrOfRepetition" INT 0 100;
BA_DEF_ BO_  "GenMsgDelayTime" INT 0 1000;
BA_DEF_ BO_  "GenMsgCycleTime" INT 0 100000;
BA_DEF_ BO_  "GenMsgSendType" ENUM  "FixedPeriodic","Event","EnabledPeriodic","NotUsed","NotUsed","EventPeriodic","NotUsed","NotUsed","NoMsgSendType";
BA_DEF_ SG_  "U_U55X_MY2022_Tx" ENUM  "No","Yes";
BA_DEF_ SG_  "U_CD542_MY2021_Tx" ENUM  "No","Yes";
BA_DEF_ SG_  "ECGUsedTxSignal" ENUM  "No","Yes";
BA_DEF_ SG_  "U_T6_MCA_MY2020_Tx" ENUM  "No","Yes";
BA_DEF_ SG_  "U_P702_MY2021_Tx" ENUM  "No","Yes";
BA_DEF_ SG_  "U_CX727_MY2021_Tx" ENUM  "No","Yes";
BA_DEF_ SG_  "U_U55X_MY2022_Rx" ENUM  "No","Yes";
BA_DEF_ SG_  "U_CD542_MY2021_Rx" ENUM  "No","Yes";
BA_DEF_ SG_  "ECGUsedRxSignal" ENUM  "No","Yes";
BA_DEF_ SG_  "U_T6_MCA_MY2020_Rx" ENUM  "No","Yes";
BA_DEF_ SG_  "U_P702_MY2021_Rx" ENUM  "No","Yes";
BA_DEF_ SG_  "U_CX727_MY2021_Rx" ENUM  "No","Yes";
BA_DEF_ SG_  "GenSigStartValue" HEX 0 268435455;
BA_DEF_ SG_  "MetaData" ENUM  "No","Yes";
BA_DEF_ SG_  "ContentDependant" ENUM  "No","Yes";
BA_DEF_ SG_  "GenSigStartValueInteger" INT 0 1000000000;
BA_DEF_ SG_  "UsedOnPgmDBC" ENUM  "No","Yes";
BA_DEF_ SG_  "WakeupSignal" ENUM  "No","Yes";
BA_DEF_ SG_  "GenSigInactiveValue" INT 0 100000;
BA_DEF_ SG_  "GenSigSendType" ENUM  "Cyclic","OnWrite","vector_leerstring","OnChange","vector_leerstring","IfActive","vector_leerstring","NoSigSendType";
BA_DEF_ BO_  "OvtpPushApplication" ENUM  "FALSE","TRUE";
BA_DEF_ BO_  "SCP_FreshnessValueLength" INT 0 512;
BA_DEF_ BO_  "SCP_FreshnessValueTxLength" INT 0 512;
BA_DEF_ BO_  "SCP_AuthInfoTxLength" INT 0 512;
BA_DEF_ BO_  "ProgBWConditional" STRING ;
BA_DEF_ BO_  "NmAsrMessage" ENUM  "No","Yes";
BA_DEF_ BO_  "TpApplType" STRING ;
BA_DEF_ BO_  "DiagState" ENUM  "No","Yes";
BA_DEF_ BO_  "TpTxIndex" INT 0 536870911;
BA_DEF_ BO_  "DiagRequest" ENUM  "No","Yes";
BA_DEF_ BO_  "DiagResponse" ENUM  "No","Yes";
BA_DEF_ BO_  "GenMsgILSupport" ENUM  "No","Yes";
BA_DEF_DEF_  "VFrameFormat" "ExtendedCAN_FD";
BA_DEF_DEF_  "DiagConnection" 0;
BA_DEF_DEF_  "FrameRouting" "";
BA_DEF_DEF_  "FrameGatewayNetwork" "NONE";
BA_DEF_DEF_  "NetworkInitialization" "Yes";
BA_DEF_DEF_  "FrameGatewayId" 0;
BA_DEF_DEF_  "EventRateOfChange" 10000;
BA_DEF_DEF_  "GenMsgStartDelayTime" 0;
BA_DEF_DEF_  "GenMsgNrOfRepetition" 1;
BA_DEF_DEF_  "GenMsgDelayTime" 20;
BA_DEF_DEF_  "GenMsgCycleTime" 0;
BA_DEF_DEF_  "GenMsgSendType" "NoMsgSendType";
BA_DEF_DEF_  "U_U55X_MY2022_Tx" "No";
BA_DEF_DEF_  "U_CD542_MY2021_Tx" "No";
BA_DEF_DEF_  "ECGUsedTxSignal" "No";
BA_DEF_DEF_  "U_T6_MCA_MY2020_Tx" "No";
BA_DEF_DEF_  "U_P702_MY2021_Tx" "No";
BA_DEF_DEF_  "U_CX727_MY2021_Tx" "No";
BA_DEF_DEF_  "U_U55X_MY2022_Rx" "No";
BA_DEF_DEF_  "U_CD542_MY2021_Rx" "No";
BA_DEF_DEF_  "ECGUsedRxSignal" "No";
BA_DEF_DEF_  "U_T6_MCA_MY2020_Rx" "No";
BA_DEF_DEF_  "U_P702_MY2021_Rx" "No";
BA_DEF_DEF_  "U_CX727_MY2021_Rx" "No";
BA_DEF_DEF_  "GenSigStartValue" 0;
BA_DEF_DEF_  "MetaData" "No";
BA_DEF_DEF_  "ContentDependant" "No";
BA_DEF_DEF_  "GenSigStartValueInteger" 0;
BA_DEF_DEF_  "UsedOnPgmDBC" "Yes";
BA_DEF_DEF_  "WakeupSignal" "No";
BA_DEF_DEF_  "GenSigInactiveValue" 0;
BA_DEF_DEF_  "GenSigSendType" "NoSigSendType";
BA_DEF_DEF_  "OvtpPushApplication" "FALSE";
BA_DEF_DEF_  "SCP_FreshnessValueLength" 64;
BA_DEF_DEF_  "SCP_FreshnessValueTxLength" 11;
BA_DEF_DEF_  "SCP_AuthInfoTxLength" 53;
BA_DEF_DEF_  "ProgBWConditional" "NONE";
BA_DEF_DEF_  "NmAsrMessage" "No";
BA_DEF_DEF_  "TpApplType" "";
BA_DEF_DEF_  "DiagState" "No";
BA_DEF_DEF_  "TpTxIndex" 0;
BA_DEF_DEF_  "DiagRequest" "No";
BA_DEF_DEF_  "DiagResponse" "No";
BA_DEF_DEF_  "GenMsgILSupport" "Yes";
BA_ "GenMsgCycleTime" BO_ 1069 100;
BA_ "GenMsgSendType" BO_ 1069 0;
BA_ "VFrameFormat" BO_ 1069 14;
BA_ "GenMsgCycleTime" BO_ 1060 100;
BA_ "GenMsgSendType" BO_ 1060 0;
BA_ "VFrameFormat" BO_ 1060 14;
BA_ "GenMsgCycleTime" BO_ 1057 100;
BA_ "GenMsgSendType" BO_ 1057 0;
BA_ "VFrameFormat" BO_ 1057 14;
BA_ "GenMsgCycleTime" BO_ 1055 100;
BA_ "GenMsgSendType" BO_ 1055 0;
BA_ "VFrameFormat" BO_ 1055 14;
BA_ "GenMsgCycleTime" BO_ 610 100;
BA_ "GenMsgSendType" BO_ 610 0;
BA_ "VFrameFormat" BO_ 610 14;
BA_ "GenMsgCycleTime" BO_ 562 100;
BA_ "GenMsgSendType" BO_ 562 0;
BA_ "VFrameFormat" BO_ 562 14;
BA_ "GenMsgCycleTime" BO_ 523 1000;
BA_ "GenMsgSendType" BO_ 523 0;
BA_ "VFrameFormat" BO_ 523 14;
BA_ "GenMsgDelayTime" BO_ 519 10;
BA_ "GenMsgCycleTime" BO_ 519 20;
BA_ "GenMsgSendType" BO_ 519 0;
BA_ "VFrameFormat" BO_ 519 14;
BA_ "GenMsgDelayTime" BO_ 517 0;
BA_ "GenMsgCycleTime" BO_ 517 10;
BA_ "GenMsgSendType" BO_ 517 0;
BA_ "VFrameFormat" BO_ 517 14;
BA_ "GenMsgDelayTime" BO_ 516 0;
BA_ "GenMsgCycleTime" BO_ 516 10;
BA_ "GenMsgSendType" BO_ 516 0;
BA_ "VFrameFormat" BO_ 516 14;
BA_ "GenMsgDelayTime" BO_ 514 10;
BA_ "GenMsgCycleTime" BO_ 514 20;
BA_ "GenMsgSendType" BO_ 514 0;
BA_ "VFrameFormat" BO_ 514 14;
BA_ "GenMsgDelayTime" BO_ 512 10;
BA_ "GenMsgCycleTime" BO_ 512 20;
BA_ "GenMsgSendType" BO_ 512 0;
BA_ "VFrameFormat" BO_ 512 14;
BA_ "GenMsgCycleTime" BO_ 382 1000;
BA_ "GenMsgSendType" BO_ 382 0;
BA_ "VFrameFormat" BO_ 382 14;
BA_ "GenMsgCycleTime" BO_ 381 100;
BA_ "GenMsgSendType" BO_ 381 0;
BA_ "VFrameFormat" BO_ 381 14;
BA_ "GenMsgCycleTime" BO_ 380 100;
BA_ "GenMsgSendType" BO_ 380 0;
BA_ "VFrameFormat" BO_ 380 14;
BA_ "GenMsgCycleTime" BO_ 377 100;
BA_ "GenMsgSendType" BO_ 377 0;
BA_ "VFrameFormat" BO_ 377 14;
BA_ "GenMsgCycleTime" BO_ 376 100;
BA_ "GenMsgSendType" BO_ 376 0;
BA_ "VFrameFormat" BO_ 376 14;
BA_ "GenMsgDelayTime" BO_ 373 10;
BA_ "GenMsgCycleTime" BO_ 373 20;
BA_ "GenMsgSendType" BO_ 373 0;
BA_ "VFrameFormat" BO_ 373 14;
BA_ "GenMsgDelayTime" BO_ 372 10;
BA_ "GenMsgCycleTime" BO_ 372 20;
BA_ "GenMsgSendType" BO_ 372 0;
BA_ "VFrameFormat" BO_ 372 14;
BA_ "GenMsgDelayTime" BO_ 359 0;
BA_ "GenMsgCycleTime" BO_ 359 10;
BA_ "GenMsgSendType" BO_ 359 0;
BA_ "VFrameFormat" BO_ 359 14;
BA_ "GenMsgCycleTime" BO_ 358 100;
BA_ "GenMsgSendType" BO_ 358 0;
BA_ "VFrameFormat" BO_ 358 14;
BA_ "GenMsgDelayTime" BO_ 357 10;
BA_ "GenMsgCycleTime" BO_ 357 20;
BA_ "GenMsgSendType" BO_ 357 0;
BA_ "VFrameFormat" BO_ 357 14;
BA_ "GenMsgCycleTime" BO_ 355 100;
BA_ "GenMsgSendType" BO_ 355 0;
BA_ "VFrameFormat" BO_ 355 14;
BA_ "GenMsgCycleTime" BO_ 342 100;
BA_ "GenMsgSendType" BO_ 342 0;
BA_ "VFrameFormat" BO_ 342 14;
BA_ "NetworkInitialization" BO_ 1520 0;
BA_ "GenMsgCycleTime" BO_ 1520 1000;
BA_ "GenMsgSendType" BO_ 1520 0;
BA_ "NmAsrMessage" BO_ 1520 1;
BA_ "GenMsgILSupport" BO_ 1520 0;
BA_ "VFrameFormat" BO_ 1520 14;
BA_ "GenMsgDelayTime" BO_ 71 10;
BA_ "GenMsgCycleTime" BO_ 71 20;
BA_ "GenMsgSendType" BO_ 71 0;
BA_ "VFrameFormat" BO_ 71 14;
BA_ "GenMsgCycleTime" BO_ 824 1000;
BA_ "GenMsgSendType" BO_ 824 5;
BA_ "VFrameFormat" BO_ 824 14;
BA_ "GenMsgCycleTime" BO_ 823 1000;
BA_ "GenMsgSendType" BO_ 823 5;
BA_ "VFrameFormat" BO_ 823 14;
BA_ "NetworkInitialization" BO_ 1920 0;
BA_ "GenMsgDelayTime" BO_ 1920 0;
BA_ "GenMsgSendType" BO_ 1920 1;
BA_ "DiagRequest" BO_ 1920 1;
BA_ "GenMsgILSupport" BO_ 1920 0;
BA_ "VFrameFormat" BO_ 1920 14;
BA_ "FrameRouting" BO_ 811 "HS3_CAN,0x32B;";
BA_ "FrameGatewayNetwork" BO_ 811 "HS3_CAN";
BA_ "FrameGatewayId" BO_ 811 811;
BA_ "VFrameFormat" BO_ 811 14;
BA_ "GenMsgCycleTime" BO_ 785 1000;
BA_ "GenMsgSendType" BO_ 785 5;
BA_ "VFrameFormat" BO_ 785 14;
BA_ "GenMsgCycleTime" BO_ 770 1000;
BA_ "GenMsgSendType" BO_ 770 5;
BA_ "VFrameFormat" BO_ 770 14;
BA_ "GenMsgStartDelayTime" BO_ 1205 1130;
BA_ "GenMsgCycleTime" BO_ 1205 100000;
BA_ "GenMsgSendType" BO_ 1205 5;
BA_ "VFrameFormat" BO_ 1205 14;
BA_ "GenMsgCycleTime" BO_ 942 1000;
BA_ "GenMsgSendType" BO_ 942 5;
BA_ "VFrameFormat" BO_ 942 14;
BA_ "FrameRouting" BO_ 123 "HS1_CAN,0x7B;";
BA_ "FrameGatewayNetwork" BO_ 123 "HS1_CAN";
BA_ "FrameGatewayId" BO_ 123 123;
BA_ "VFrameFormat" BO_ 123 14;
BA_ "FrameRouting" BO_ 1053 "HS1_CAN,0x41D;";
BA_ "FrameGatewayNetwork" BO_ 1053 "HS1_CAN";
BA_ "FrameGatewayId" BO_ 1053 1053;
BA_ "VFrameFormat" BO_ 1053 14;
BA_ "NetworkInitialization" BO_ 2612052184 0;
BA_ "GenMsgDelayTime" BO_ 2612052184 0;
BA_ "GenMsgSendType" BO_ 2612052184 1;
BA_ "OvtpPushApplication" BO_ 2612052184 1;
BA_ "TpTxIndex" BO_ 2612052184 464568536;
BA_ "NetworkInitialization" BO_ 2612224187 0;
BA_ "GenMsgDelayTime" BO_ 2612224187 0;
BA_ "GenMsgSendType" BO_ 2612224187 1;
BA_ "TpTxIndex" BO_ 2612224187 464710872;
BA_ "GenMsgCycleTime" BO_ 1201 1000;
BA_ "GenMsgSendType" BO_ 1201 5;
BA_ "VFrameFormat" BO_ 1201 14;
BA_ "NetworkInitialization" BO_ 1912 0;
BA_ "GenMsgDelayTime" BO_ 1912 0;
BA_ "GenMsgSendType" BO_ 1912 1;
BA_ "DiagResponse" BO_ 1912 1;
BA_ "GenMsgILSupport" BO_ 1912 0;
BA_ "VFrameFormat" BO_ 1912 14;
BA_ "NetworkInitialization" BO_ 1904 0;
BA_ "GenMsgDelayTime" BO_ 1904 0;
BA_ "GenMsgSendType" BO_ 1904 1;
BA_ "DiagRequest" BO_ 1904 1;
BA_ "GenMsgILSupport" BO_ 1904 0;
BA_ "VFrameFormat" BO_ 1904 14;
BA_ "NetworkInitialization" BO_ 1527 0;
BA_ "GenMsgCycleTime" BO_ 1527 1000;
BA_ "GenMsgSendType" BO_ 1527 0;
BA_ "NmAsrMessage" BO_ 1527 1;
BA_ "GenMsgILSupport" BO_ 1527 0;
BA_ "VFrameFormat" BO_ 1527 14;
BA_ "FrameRouting" BO_ 949 "HS1_CAN,0x3B5;";
BA_ "FrameGatewayNetwork" BO_ 949 "HS1_CAN";
BA_ "FrameGatewayId" BO_ 949 949;
BA_ "VFrameFormat" BO_ 949 14;
BA_ "NetworkInitialization" BO_ 2612118744 0;
BA_ "GenMsgDelayTime" BO_ 2612118744 0;
BA_ "GenMsgSendType" BO_ 2612118744 1;
BA_ "OvtpPushApplication" BO_ 2612118744 1;
BA_ "TpTxIndex" BO_ 2612118744 464635096;
BA_ "DiagRequest" BO_ 2612074712 1;
BA_ "DiagConnection" BO_ 2612074712 29;
BA_ "NetworkInitialization" BO_ 2612074712 0;
BA_ "GenMsgDelayTime" BO_ 2612074712 0;
BA_ "GenMsgSendType" BO_ 2612074712 1;
BA_ "OvtpPushApplication" BO_ 2612074712 1;
BA_ "TpTxIndex" BO_ 2612074712 464591064;
BA_ "DiagRequest" BO_ 2612024536 1;
BA_ "DiagConnection" BO_ 2612024536 27;
BA_ "NetworkInitialization" BO_ 2612024536 0;
BA_ "GenMsgDelayTime" BO_ 2612024536 0;
BA_ "GenMsgSendType" BO_ 2612024536 1;
BA_ "OvtpPushApplication" BO_ 2612024536 1;
BA_ "TpTxIndex" BO_ 2612024536 464540888;
BA_ "DiagRequest" BO_ 2612036824 1;
BA_ "DiagConnection" BO_ 2612036824 28;
BA_ "NetworkInitialization" BO_ 2612036824 0;
BA_ "GenMsgDelayTime" BO_ 2612036824 0;
BA_ "GenMsgSendType" BO_ 2612036824 1;
BA_ "OvtpPushApplication" BO_ 2612036824 1;
BA_ "TpTxIndex" BO_ 2612036824 464553176;
BA_ "DiagRequest" BO_ 2612103384 1;
BA_ "DiagConnection" BO_ 2612103384 30;
BA_ "NetworkInitialization" BO_ 2612103384 0;
BA_ "GenMsgDelayTime" BO_ 2612103384 0;
BA_ "GenMsgSendType" BO_ 2612103384 1;
BA_ "OvtpPushApplication" BO_ 2612103384 1;
BA_ "TpTxIndex" BO_ 2612103384 464619736;
BA_ "GenMsgCycleTime" BO_ 639 1000;
BA_ "GenMsgSendType" BO_ 639 5;
BA_ "VFrameFormat" BO_ 639 14;
BA_ "GenMsgCycleTime" BO_ 530 1000;
BA_ "GenMsgSendType" BO_ 530 5;
BA_ "VFrameFormat" BO_ 530 14;
BA_ "GenMsgCycleTime" BO_ 550 1000;
BA_ "GenMsgSendType" BO_ 550 5;
BA_ "VFrameFormat" BO_ 550 14;
BA_ "FrameRouting" BO_ 879 "HS1_CAN,0x36F;";
BA_ "FrameGatewayNetwork" BO_ 879 "HS1_CAN";
BA_ "FrameGatewayId" BO_ 879 879;
BA_ "VFrameFormat" BO_ 879 14;
BA_ "NetworkInitialization" BO_ 1455 0;
BA_ "GenMsgCycleTime" BO_ 1455 1000;
BA_ "GenMsgSendType" BO_ 1455 0;
BA_ "NmAsrMessage" BO_ 1455 1;
BA_ "GenMsgILSupport" BO_ 1455 0;
BA_ "VFrameFormat" BO_ 1455 14;
BA_ "NetworkInitialization" BO_ 1775 0;
BA_ "GenMsgDelayTime" BO_ 1775 0;
BA_ "GenMsgSendType" BO_ 1775 1;
BA_ "DiagResponse" BO_ 1775 1;
BA_ "GenMsgILSupport" BO_ 1775 0;
BA_ "VFrameFormat" BO_ 1775 14;
BA_ "NetworkInitialization" BO_ 1767 0;
BA_ "GenMsgDelayTime" BO_ 1767 0;
BA_ "GenMsgSendType" BO_ 1767 1;
BA_ "DiagRequest" BO_ 1767 1;
BA_ "GenMsgILSupport" BO_ 1767 0;
BA_ "VFrameFormat" BO_ 1767 14;
BA_ "NetworkInitialization" BO_ 2612019416 0;
BA_ "GenMsgDelayTime" BO_ 2612019416 0;
BA_ "GenMsgSendType" BO_ 2612019416 1;
BA_ "OvtpPushApplication" BO_ 2612019416 1;
BA_ "TpTxIndex" BO_ 2612019416 464535768;
BA_ "GenMsgCycleTime" BO_ 885 200;
BA_ "GenMsgSendType" BO_ 885 0;
BA_ "VFrameFormat" BO_ 885 14;
BA_ "DiagRequest" BO_ 2612104408 1;
BA_ "DiagConnection" BO_ 2612104408 31;
BA_ "NetworkInitialization" BO_ 2612104408 0;
BA_ "GenMsgDelayTime" BO_ 2612104408 0;
BA_ "GenMsgSendType" BO_ 2612104408 1;
BA_ "OvtpPushApplication" BO_ 2612104408 1;
BA_ "TpTxIndex" BO_ 2612104408 464620760;
BA_ "NetworkInitialization" BO_ 2612020440 0;
BA_ "GenMsgDelayTime" BO_ 2612020440 0;
BA_ "GenMsgSendType" BO_ 2612020440 1;
BA_ "OvtpPushApplication" BO_ 2612020440 1;
BA_ "TpTxIndex" BO_ 2612020440 464536792;
BA_ "FrameRouting" BO_ 979 "HS2_CAN,0x3D3";
BA_ "FrameGatewayNetwork" BO_ 979 "HS2_CAN";
BA_ "FrameGatewayId" BO_ 979 979;
BA_ "VFrameFormat" BO_ 979 14;
BA_ "FrameRouting" BO_ 739 "HS3_CAN,0x2E3;";
BA_ "FrameGatewayNetwork" BO_ 739 "HS3_CAN";
BA_ "FrameGatewayId" BO_ 739 739;
BA_ "VFrameFormat" BO_ 739 14;
BA_ "GenMsgCycleTime" BO_ 1160 1000;
BA_ "GenMsgSendType" BO_ 1160 5;
BA_ "VFrameFormat" BO_ 1160 14;
BA_ "NetworkInitialization" BO_ 1825 0;
BA_ "GenMsgDelayTime" BO_ 1825 0;
BA_ "GenMsgSendType" BO_ 1825 1;
BA_ "DiagRequest" BO_ 1825 1;
BA_ "GenMsgILSupport" BO_ 1825 0;
BA_ "VFrameFormat" BO_ 1825 14;
BA_ "FrameRouting" BO_ 1001 "HS2_CAN,0x3E9";
BA_ "FrameGatewayNetwork" BO_ 1001 "HS2_CAN";
BA_ "FrameGatewayId" BO_ 1001 1001;
BA_ "VFrameFormat" BO_ 1001 14;
BA_ "FrameRouting" BO_ 1077 "HS2_CAN,0x435;";
BA_ "FrameGatewayNetwork" BO_ 1077 "HS2_CAN";
BA_ "FrameGatewayId" BO_ 1077 1077;
BA_ "VFrameFormat" BO_ 1077 14;
BA_ "FrameRouting" BO_ 945 "HS1_CAN,0x3B1;";
BA_ "FrameGatewayNetwork" BO_ 945 "HS1_CAN";
BA_ "FrameGatewayId" BO_ 945 945;
BA_ "VFrameFormat" BO_ 945 14;
BA_ "DiagRequest" BO_ 2612073688 1;
BA_ "DiagConnection" BO_ 2612073688 80;
BA_ "NetworkInitialization" BO_ 2612073688 0;
BA_ "GenMsgDelayTime" BO_ 2612073688 0;
BA_ "GenMsgSendType" BO_ 2612073688 1;
BA_ "OvtpPushApplication" BO_ 2612073688 1;
BA_ "TpTxIndex" BO_ 2612073688 464590040;
BA_ "GenMsgCycleTime" BO_ 771 1000;
BA_ "GenMsgSendType" BO_ 771 5;
BA_ "VFrameFormat" BO_ 771 14;
BA_ "GenMsgCycleTime" BO_ 777 1000;
BA_ "GenMsgSendType" BO_ 777 5;
BA_ "VFrameFormat" BO_ 777 14;
BA_ "GenMsgCycleTime" BO_ 1043 1000;
BA_ "GenMsgSendType" BO_ 1043 5;
BA_ "VFrameFormat" BO_ 1043 14;
BA_ "NetworkInitialization" BO_ 1833 0;
BA_ "GenMsgDelayTime" BO_ 1833 0;
BA_ "GenMsgSendType" BO_ 1833 1;
BA_ "DiagResponse" BO_ 1833 1;
BA_ "GenMsgILSupport" BO_ 1833 0;
BA_ "VFrameFormat" BO_ 1833 14;
BA_ "GenMsgCycleTime" BO_ 991 1000;
BA_ "GenMsgSendType" BO_ 991 5;
BA_ "VFrameFormat" BO_ 991 14;
BA_ "FrameRouting" BO_ 395 "HS3_CAN,0x18B;";
BA_ "FrameGatewayNetwork" BO_ 395 "HS3_CAN";
BA_ "FrameGatewayId" BO_ 395 395;
BA_ "VFrameFormat" BO_ 395 14;
BA_ "FrameRouting" BO_ 542 "HS4_CAN,0x21E;";
BA_ "FrameGatewayNetwork" BO_ 542 "HS4_CAN";
BA_ "FrameGatewayId" BO_ 542 542;
BA_ "VFrameFormat" BO_ 542 14;
BA_ "GenMsgSendType" BO_ 1689 1;
BA_ "TpApplType" BO_ 1689 "DiagUUDTResponse";
BA_ "GenMsgILSupport" BO_ 1689 0;
BA_ "VFrameFormat" BO_ 1689 14;
BA_ "GenMsgCycleTime" BO_ 515 100;
BA_ "GenMsgSendType" BO_ 515 5;
BA_ "VFrameFormat" BO_ 515 14;
BA_ "GenMsgCycleTime" BO_ 982 50;
BA_ "GenMsgSendType" BO_ 982 0;
BA_ "VFrameFormat" BO_ 982 14;
BA_ "GenMsgCycleTime" BO_ 1104 200;
BA_ "GenMsgSendType" BO_ 1104 0;
BA_ "VFrameFormat" BO_ 1104 14;
BA_ "FrameRouting" BO_ 829 "HS1_CAN,0x33D;";
BA_ "FrameGatewayNetwork" BO_ 829 "HS1_CAN";
BA_ "FrameGatewayId" BO_ 829 829;
BA_ "VFrameFormat" BO_ 829 14;
BA_ "NetworkInitialization" BO_ 2611070168 0;
BA_ "GenMsgDelayTime" BO_ 2611070168 0;
BA_ "GenMsgSendType" BO_ 2611070168 1;
BA_ "TpTxIndex" BO_ 2611070168 463586520;
BA_ "NetworkInitialization" BO_ 2611175537 0;
BA_ "GenMsgDelayTime" BO_ 2611175537 0;
BA_ "GenMsgSendType" BO_ 2611175537 1;
BA_ "TpTxIndex" BO_ 2611175537 463586520;
BA_ "NetworkInitialization" BO_ 2612224113 0;
BA_ "GenMsgDelayTime" BO_ 2612224113 0;
BA_ "GenMsgSendType" BO_ 2612224113 1;
BA_ "OvtpPushApplication" BO_ 2612224113 1;
BA_ "TpTxIndex" BO_ 2612224113 464635096;
BA_ "NetworkInitialization" BO_ 2610021592 0;
BA_ "GenMsgDelayTime" BO_ 2610021592 0;
BA_ "GenMsgSendType" BO_ 2610021592 1;
BA_ "TpTxIndex" BO_ 2610021592 462537944;
BA_ "NetworkInitialization" BO_ 2610126961 0;
BA_ "GenMsgDelayTime" BO_ 2610126961 0;
BA_ "GenMsgSendType" BO_ 2610126961 1;
BA_ "TpTxIndex" BO_ 2610126961 462537944;
BA_ "DiagRequest" BO_ 2610975960 1;
BA_ "DiagConnection" BO_ 2610975960 21;
BA_ "NetworkInitialization" BO_ 2610975960 0;
BA_ "GenMsgDelayTime" BO_ 2610975960 0;
BA_ "GenMsgSendType" BO_ 2610975960 1;
BA_ "TpTxIndex" BO_ 2610975960 463492312;
BA_ "NetworkInitialization" BO_ 2611175445 0;
BA_ "GenMsgDelayTime" BO_ 2611175445 0;
BA_ "GenMsgSendType" BO_ 2611175445 1;
BA_ "TpTxIndex" BO_ 2611175445 463492312;
BA_ "DiagConnection" BO_ 2611175445 21;
BA_ "DiagResponse" BO_ 2611175445 1;
BA_ "NetworkInitialization" BO_ 2612224021 0;
BA_ "GenMsgDelayTime" BO_ 2612224021 0;
BA_ "GenMsgSendType" BO_ 2612224021 1;
BA_ "OvtpPushApplication" BO_ 2612224021 1;
BA_ "TpTxIndex" BO_ 2612224021 464540888;
BA_ "DiagResponse" BO_ 2612224021 1;
BA_ "DiagConnection" BO_ 2612224021 27;
BA_ "DiagRequest" BO_ 2611025112 1;
BA_ "DiagConnection" BO_ 2611025112 23;
BA_ "NetworkInitialization" BO_ 2611025112 0;
BA_ "GenMsgDelayTime" BO_ 2611025112 0;
BA_ "GenMsgSendType" BO_ 2611025112 1;
BA_ "TpTxIndex" BO_ 2611025112 463541464;
BA_ "NetworkInitialization" BO_ 2611175493 0;
BA_ "GenMsgDelayTime" BO_ 2611175493 0;
BA_ "GenMsgSendType" BO_ 2611175493 1;
BA_ "TpTxIndex" BO_ 2611175493 463541464;
BA_ "DiagConnection" BO_ 2611175493 23;
BA_ "DiagResponse" BO_ 2611175493 1;
BA_ "DiagConnection" BO_ 2612224069 80;
BA_ "NetworkInitialization" BO_ 2612224069 0;
BA_ "GenMsgDelayTime" BO_ 2612224069 0;
BA_ "GenMsgSendType" BO_ 2612224069 1;
BA_ "OvtpPushApplication" BO_ 2612224069 1;
BA_ "TpTxIndex" BO_ 2612224069 464590040;
BA_ "DiagResponse" BO_ 2612224069 1;
BA_ "U_P702_MY2021_Tx" SG_ 1069 SlMde_D_Stat 1;
BA_ "U_CD542_MY2021_Tx" SG_ 1069 SlMde_D_Stat 1;
BA_ "U_T6_MCA_MY2020_Tx" SG_ 1069 SlMde_D_Stat 1;
BA_ "U_P702_MY2021_Tx" SG_ 1069 SlMde_D_RqDsply 1;
BA_ "U_CD542_MY2021_Tx" SG_ 1069 SlMde_D_RqDsply 1;
BA_ "U_T6_MCA_MY2020_Tx" SG_ 1069 SlMde_D_RqDsply 1;
BA_ "U_P702_MY2021_Tx" SG_ 1069 IsaOffst_D_Stat 1;
BA_ "U_CD542_MY2021_Tx" SG_ 1069 IsaOffst_D_Stat 1;
BA_ "U_T6_MCA_MY2020_Tx" SG_ 1069 IsaOffst_D_Stat 1;
BA_ "U_CD542_MY2021_Tx" SG_ 1069 ReFuelSysStat_D_Dsply 1;
BA_ "U_CX727_MY2021_Tx" SG_ 1069 ReFuelSysStat_D_Dsply 1;
BA_ "WakeupSignal" SG_ 1069 ReFuelSysStat_D_Dsply 1;
BA_ "U_CD542_MY2021_Tx" SG_ 1069 ULoSrcOnPlg_B_Cmd 1;
BA_ "U_CX727_MY2021_Tx" SG_ 1069 ULoSrcOnPlg_B_Cmd 1;
BA_ "U_CD542_MY2021_Rx" SG_ 1069 ULoSrcOnPlg_B_Cmd 1;
BA_ "U_CX727_MY2021_Rx" SG_ 1069 ULoSrcOnPlg_B_Cmd 1;
BA_ "U_CD542_MY2021_Tx" SG_ 1069 EngOilMaint_B_Stat 1;
BA_ "U_CX727_MY2021_Tx" SG_ 1069 EngOilMaint_B_Stat 1;
BA_ "U_CD542_MY2021_Rx" SG_ 1069 EngOilMaint_B_Stat 1;
BA_ "U_CX727_MY2021_Rx" SG_ 1069 EngOilMaint_B_Stat 1;
BA_ "U_CX727_MY2021_Tx" SG_ 1069 GrllShtrPos_D_Cmd 1;
BA_ "U_U55X_MY2022_Tx" SG_ 1069 GrllShtrPos_D_Cmd 1;
BA_ "U_CD542_MY2021_Tx" SG_ 1069 GrllShtrPos_D_Cmd 1;
BA_ "U_T6_MCA_MY2020_Tx" SG_ 1069 GrllShtrPos_D_Cmd 1;
BA_ "U_P702_MY2021_Tx" SG_ 1069 GrllShtrPos_D_Cmd 1;
BA_ "U_CX727_MY2021_Tx" SG_ 1069 GrllShtrPos_B_Falt 1;
BA_ "U_U55X_MY2022_Tx" SG_ 1069 GrllShtrPos_B_Falt 1;
BA_ "U_CD542_MY2021_Tx" SG_ 1069 GrllShtrPos_B_Falt 1;
BA_ "U_T6_MCA_MY2020_Tx" SG_ 1069 GrllShtrPos_B_Falt 1;
BA_ "U_P702_MY2021_Tx" SG_ 1069 GrllShtrPos_B_Falt 1;
BA_ "U_CD542_MY2021_Tx" SG_ 1069 ObdWarmUp_B_Complt 1;
BA_ "U_CX727_MY2021_Tx" SG_ 1069 ObdWarmUp_B_Complt 1;
BA_ "U_P702_MY2021_Tx" SG_ 1069 ObdWarmUp_B_Complt 1;
BA_ "U_CD542_MY2021_Rx" SG_ 1069 ObdWarmUp_B_Complt 1;
BA_ "U_P702_MY2021_Rx" SG_ 1069 ObdWarmUp_B_Complt 1;
BA_ "U_CX727_MY2021_Rx" SG_ 1069 ObdWarmUp_B_Complt 1;
BA_ "ContentDependant" SG_ 1069 ObdWarmUp_B_Complt 1;
BA_ "U_CX727_MY2021_Tx" SG_ 1069 EngMsgTxt_D_Rq 1;
BA_ "U_U55X_MY2022_Tx" SG_ 1069 EngMsgTxt_D_Rq 1;
BA_ "U_CD542_MY2021_Tx" SG_ 1069 EngMsgTxt_D_Rq 1;
BA_ "U_T6_MCA_MY2020_Tx" SG_ 1069 EngMsgTxt_D_Rq 1;
BA_ "U_P702_MY2021_Tx" SG_ 1069 EngMsgTxt_D_Rq 1;
BA_ "ContentDependant" SG_ 1069 EngMsgTxt_D_Rq 1;
BA_ "U_T6_MCA_MY2020_Tx" SG_ 1069 EngClnt_Te_ActlDiag 1;
BA_ "U_CD542_MY2021_Tx" SG_ 1069 EngClnt_Te_ActlDiag 1;
BA_ "U_CX727_MY2021_Tx" SG_ 1069 EngClnt_Te_ActlDiag 1;
BA_ "U_P702_MY2021_Tx" SG_ 1069 EngClnt_Te_ActlDiag 1;
BA_ "U_T6_MCA_MY2020_Rx" SG_ 1069 EngClnt_Te_ActlDiag 1;
BA_ "U_CD542_MY2021_Rx" SG_ 1069 EngClnt_Te_ActlDiag 1;
BA_ "U_P702_MY2021_Rx" SG_ 1069 EngClnt_Te_ActlDiag 1;
BA_ "U_CX727_MY2021_Rx" SG_ 1069 EngClnt_Te_ActlDiag 1;
BA_ "ContentDependant" SG_ 1069 EngClnt_Te_ActlDiag 1;
BA_ "U_P702_MY2021_Rx" SG_ 1069 ThrPos_Pc_CalcDiag 1;
BA_ "U_T6_MCA_MY2020_Tx" SG_ 1069 EngLoad_Pc_CalcDiag 1;
BA_ "U_CD542_MY2021_Tx" SG_ 1069 EngLoad_Pc_CalcDiag 1;
BA_ "U_CX727_MY2021_Tx" SG_ 1069 EngLoad_Pc_CalcDiag 1;
BA_ "U_P702_MY2021_Tx" SG_ 1069 EngLoad_Pc_CalcDiag 1;
BA_ "U_T6_MCA_MY2020_Rx" SG_ 1069 EngLoad_Pc_CalcDiag 1;
BA_ "U_P702_MY2021_Rx" SG_ 1069 EngLoad_Pc_CalcDiag 1;
BA_ "U_CD542_MY2021_Rx" SG_ 1069 EngLoad_Pc_CalcDiag 1;
BA_ "U_CX727_MY2021_Rx" SG_ 1069 EngLoad_Pc_CalcDiag 1;
BA_ "ContentDependant" SG_ 1069 EngLoad_Pc_CalcDiag 1;
BA_ "U_CX727_MY2021_Tx" SG_ 1069 EngAirIn_Te_Actl 1;
BA_ "U_U55X_MY2022_Tx" SG_ 1069 EngAirIn_Te_Actl 1;
BA_ "U_CD542_MY2021_Tx" SG_ 1069 EngAirIn_Te_Actl 1;
BA_ "U_T6_MCA_MY2020_Tx" SG_ 1069 EngAirIn_Te_Actl 1;
BA_ "U_P702_MY2021_Tx" SG_ 1069 EngAirIn_Te_Actl 1;
BA_ "U_T6_MCA_MY2020_Rx" SG_ 1069 EngAirIn_Te_Actl 1;
BA_ "U_P702_MY2021_Rx" SG_ 1069 EngAirIn_Te_Actl 1;
BA_ "U_T6_MCA_MY2020_Tx" SG_ 1069 ApedPos_Pc_ActlDiag 1;
BA_ "U_CD542_MY2021_Tx" SG_ 1069 ApedPos_Pc_ActlDiag 1;
BA_ "U_CX727_MY2021_Tx" SG_ 1069 ApedPos_Pc_ActlDiag 1;
BA_ "U_P702_MY2021_Tx" SG_ 1069 ApedPos_Pc_ActlDiag 1;
BA_ "U_T6_MCA_MY2020_Rx" SG_ 1069 ApedPos_Pc_ActlDiag 1;
BA_ "U_CD542_MY2021_Rx" SG_ 1069 ApedPos_Pc_ActlDiag 1;
BA_ "U_P702_MY2021_Rx" SG_ 1069 ApedPos_Pc_ActlDiag 1;
BA_ "U_CX727_MY2021_Rx" SG_ 1069 ApedPos_Pc_ActlDiag 1;
BA_ "ContentDependant" SG_ 1069 ApedPos_Pc_ActlDiag 1;
BA_ "U_T6_MCA_MY2020_Tx" SG_ 1060 RearDiffOilTeWarn_B_Rq 1;
BA_ "U_P702_MY2021_Tx" SG_ 1060 RearDiffOilTeWarn_B_Rq 1;
BA_ "GenSigStartValue" SG_ 1060 EngExhMdeQuiet_D_Stat 2;
BA_ "GenSigStartValueInteger" SG_ 1060 EngExhMdeQuiet_D_Stat 2;
BA_ "U_T6_MCA_MY2020_Tx" SG_ 1060 RearDiffOil_Te_Actl 1;
BA_ "U_P702_MY2021_Tx" SG_ 1060 RearDiffOil_Te_Actl 1;
BA_ "U_T6_MCA_MY2020_Rx" SG_ 1060 RearDiffOil_Te_Actl 1;
BA_ "GenSigStartValue" SG_ 1060 RearDiffOil_Te_Actl 77;
BA_ "GenSigStartValueInteger" SG_ 1060 RearDiffOil_Te_Actl 77;
BA_ "U_CX727_MY2021_Tx" SG_ 1060 BpedDrvMsgTxt_B_Dsply 1;
BA_ "U_U55X_MY2022_Tx" SG_ 1060 BpedDrvMsgTxt_B_Dsply 1;
BA_ "U_CD542_MY2021_Tx" SG_ 1060 BpedDrvMsgTxt_B_Dsply 1;
BA_ "U_T6_MCA_MY2020_Tx" SG_ 1060 BpedDrvMsgTxt_B_Dsply 1;
BA_ "U_P702_MY2021_Tx" SG_ 1060 BpedDrvMsgTxt_B_Dsply 1;
BA_ "U_U55X_MY2022_Tx" SG_ 1060 FuelLvl_Pc_DsplyEng 1;
BA_ "U_CD542_MY2021_Tx" SG_ 1060 FuelLvl_Pc_DsplyEng 1;
BA_ "U_T6_MCA_MY2020_Tx" SG_ 1060 FuelLvl_Pc_DsplyEng 1;
BA_ "U_P702_MY2021_Tx" SG_ 1060 FuelLvl_Pc_DsplyEng 1;
BA_ "GenSigStartValueInteger" SG_ 1060 FuelLvl_Pc_DsplyEng 48;
BA_ "U_U55X_MY2022_Tx" SG_ 1060 FuelLvlWarn_D_ActlEng 1;
BA_ "U_CD542_MY2021_Tx" SG_ 1060 FuelLvlWarn_D_ActlEng 1;
BA_ "U_T6_MCA_MY2020_Tx" SG_ 1060 FuelLvlWarn_D_ActlEng 1;
BA_ "U_P702_MY2021_Tx" SG_ 1060 FuelLvlWarn_D_ActlEng 1;
BA_ "U_U55X_MY2022_Tx" SG_ 1060 FuelRange_L_DsplyEng 1;
BA_ "U_CD542_MY2021_Tx" SG_ 1060 FuelRange_L_DsplyEng 1;
BA_ "U_T6_MCA_MY2020_Tx" SG_ 1060 FuelRange_L_DsplyEng 1;
BA_ "U_P702_MY2021_Tx" SG_ 1060 FuelRange_L_DsplyEng 1;
BA_ "U_CX727_MY2021_Tx" SG_ 1060 SelDrvMdePt_D_Stat 1;
BA_ "U_U55X_MY2022_Tx" SG_ 1060 SelDrvMdePt_D_Stat 1;
BA_ "U_CD542_MY2021_Tx" SG_ 1060 SelDrvMdePt_D_Stat 1;
BA_ "U_T6_MCA_MY2020_Tx" SG_ 1060 SelDrvMdePt_D_Stat 1;
BA_ "U_P702_MY2021_Tx" SG_ 1060 SelDrvMdePt_D_Stat 1;
BA_ "U_U55X_MY2022_Rx" SG_ 1060 SelDrvMdePt_D_Stat 1;
BA_ "U_CD542_MY2021_Rx" SG_ 1060 SelDrvMdePt_D_Stat 1;
BA_ "U_T6_MCA_MY2020_Rx" SG_ 1060 SelDrvMdePt_D_Stat 1;
BA_ "U_P702_MY2021_Rx" SG_ 1060 SelDrvMdePt_D_Stat 1;
BA_ "U_T6_MCA_MY2020_Tx" SG_ 1057 FohEng_D_Rq 1;
BA_ "U_P702_MY2021_Tx" SG_ 1057 FohEng_D_Rq 1;
BA_ "GenSigStartValue" SG_ 1057 FohEng_D_Rq 2;
BA_ "ContentDependant" SG_ 1057 FohEng_D_Rq 1;
BA_ "GenSigStartValueInteger" SG_ 1057 FohEng_D_Rq 2;
BA_ "U_U55X_MY2022_Tx" SG_ 1057 EngIdlShutDwnTxt_D_Rq 1;
BA_ "U_T6_MCA_MY2020_Tx" SG_ 1057 EngIdlShutDwnTxt_D_Rq 1;
BA_ "U_P702_MY2021_Tx" SG_ 1057 EngIdlShutDwnTxt_D_Rq 1;
BA_ "U_CD542_MY2021_Tx" SG_ 1057 EngIdlShutDwnTxt_D_Rq 1;
BA_ "U_CX727_MY2021_Tx" SG_ 1057 EngIdlShutDwnTxt_D_Rq 1;
BA_ "U_U55X_MY2022_Tx" SG_ 1057 EngIdlShutDown_D_Stat 1;
BA_ "U_T6_MCA_MY2020_Tx" SG_ 1057 EngIdlShutDown_D_Stat 1;
BA_ "U_P702_MY2021_Tx" SG_ 1057 EngIdlShutDown_D_Stat 1;
BA_ "U_CD542_MY2021_Tx" SG_ 1057 EngIdlShutDown_D_Stat 1;
BA_ "U_CX727_MY2021_Tx" SG_ 1057 EngIdlShutDown_D_Stat 1;
BA_ "ECGUsedRxSignal" SG_ 1057 EngIdlShutDown_D_Stat 1;
BA_ "U_T6_MCA_MY2020_Rx" SG_ 1057 EngIdlShutDown_D_Stat 1;
BA_ "ContentDependant" SG_ 1057 EngIdlShutDown_D_Stat 1;
BA_ "U_U55X_MY2022_Tx" SG_ 1057 FUEL_ALCOHOL_PERCNT 1;
BA_ "U_T6_MCA_MY2020_Tx" SG_ 1057 FUEL_ALCOHOL_PERCNT 1;
BA_ "U_P702_MY2021_Tx" SG_ 1057 FUEL_ALCOHOL_PERCNT 1;
BA_ "U_CD542_MY2021_Tx" SG_ 1057 FUEL_ALCOHOL_PERCNT 1;
BA_ "U_CX727_MY2021_Tx" SG_ 1057 FUEL_ALCOHOL_PERCNT 1;
BA_ "GenSigStartValue" SG_ 1057 FUEL_ALCOHOL_PERCNT 255;
BA_ "ContentDependant" SG_ 1057 FUEL_ALCOHOL_PERCNT 1;
BA_ "GenSigStartValueInteger" SG_ 1057 FUEL_ALCOHOL_PERCNT 255;
BA_ "U_T6_MCA_MY2020_Tx" SG_ 1057 TrnTotTq_Rt_Est 1;
BA_ "U_P702_MY2021_Tx" SG_ 1057 TrnTotTq_Rt_Est 1;
BA_ "ContentDependant" SG_ 1057 TrnTotTq_Rt_Est 1;
BA_ "U_T6_MCA_MY2020_Tx" SG_ 1057 TrnTotLss_Tq_Est 1;
BA_ "U_P702_MY2021_Tx" SG_ 1057 TrnTotLss_Tq_Est 1;
BA_ "ContentDependant" SG_ 1057 TrnTotLss_Tq_Est 1;
BA_ "U_U55X_MY2022_Tx" SG_ 1057 ECMMILRequest 1;
BA_ "U_T6_MCA_MY2020_Tx" SG_ 1057 ECMMILRequest 1;
BA_ "U_P702_MY2021_Tx" SG_ 1057 ECMMILRequest 1;
BA_ "U_CD542_MY2021_Tx" SG_ 1057 ECMMILRequest 1;
BA_ "U_CX727_MY2021_Tx" SG_ 1057 ECMMILRequest 1;
BA_ "U_U55X_MY2022_Tx" SG_ 1057 AirCondFluidHi_P_Actl 1;
BA_ "U_T6_MCA_MY2020_Tx" SG_ 1057 AirCondFluidHi_P_Actl 1;
BA_ "U_P702_MY2021_Tx" SG_ 1057 AirCondFluidHi_P_Actl 1;
BA_ "U_CD542_MY2021_Tx" SG_ 1057 AirCondFluidHi_P_Actl 1;
BA_ "U_CX727_MY2021_Tx" SG_ 1057 AirCondFluidHi_P_Actl 1;
BA_ "U_CD542_MY2021_Rx" SG_ 1057 AirCondFluidHi_P_Actl 1;
BA_ "U_P702_MY2021_Rx" SG_ 1057 AirCondFluidHi_P_Actl 1;
BA_ "U_CX727_MY2021_Rx" SG_ 1057 AirCondFluidHi_P_Actl 1;
BA_ "U_U55X_MY2022_Tx" SG_ 1057 OilPressureWarning 1;
BA_ "U_T6_MCA_MY2020_Tx" SG_ 1057 OilPressureWarning 1;
BA_ "U_P702_MY2021_Tx" SG_ 1057 OilPressureWarning 1;
BA_ "U_CD542_MY2021_Tx" SG_ 1057 OilPressureWarning 1;
BA_ "U_CX727_MY2021_Tx" SG_ 1057 OilPressureWarning 1;
BA_ "U_T6_MCA_MY2020_Tx" SG_ 1057 VehVLimStat_D_Actl 1;
BA_ "U_P702_MY2021_Tx" SG_ 1057 VehVLimStat_D_Actl 1;
BA_ "U_T6_MCA_MY2020_Rx" SG_ 1057 VehVLimStat_D_Actl 1;
BA_ "U_P702_MY2021_Rx" SG_ 1057 VehVLimStat_D_Actl 1;
BA_ "ContentDependant" SG_ 1057 VehVLimStat_D_Actl 1;
BA_ "U_T6_MCA_MY2020_Tx" SG_ 1057 VehVLimActv_B_Actl 1;
BA_ "U_P702_MY2021_Tx" SG_ 1057 VehVLimActv_B_Actl 1;
BA_ "U_CD542_MY2021_Tx" SG_ 1057 VehVLimActv_B_Actl 1;
BA_ "U_CX727_MY2021_Tx" SG_ 1057 VehVLimActv_B_Actl 1;
BA_ "U_T6_MCA_MY2020_Rx" SG_ 1057 VehVLimActv_B_Actl 1;
BA_ "U_P702_MY2021_Rx" SG_ 1057 VehVLimActv_B_Actl 1;
BA_ "U_CD542_MY2021_Rx" SG_ 1057 VehVLimActv_B_Actl 1;
BA_ "U_CX727_MY2021_Rx" SG_ 1057 VehVLimActv_B_Actl 1;
BA_ "ContentDependant" SG_ 1057 VehVLimActv_B_Actl 1;
BA_ "U_U55X_MY2022_Tx" SG_ 1057 CoolantFanStepAct 1;
BA_ "U_T6_MCA_MY2020_Tx" SG_ 1057 CoolantFanStepAct 1;
BA_ "U_P702_MY2021_Tx" SG_ 1057 CoolantFanStepAct 1;
BA_ "U_CD542_MY2021_Tx" SG_ 1057 CoolantFanStepAct 1;
BA_ "U_CX727_MY2021_Tx" SG_ 1057 CoolantFanStepAct 1;
BA_ "U_U55X_MY2022_Tx" SG_ 1055 EcoCochInstNeg_B_Dsply 1;
BA_ "U_CD542_MY2021_Tx" SG_ 1055 EcoCochInstNeg_B_Dsply 1;
BA_ "U_T6_MCA_MY2020_Tx" SG_ 1055 EcoCochInstNeg_B_Dsply 1;
BA_ "U_P702_MY2021_Tx" SG_ 1055 EcoCochInstNeg_B_Dsply 1;
BA_ "U_CX727_MY2021_Tx" SG_ 1055 EcoCochInstNeg_B_Dsply 1;
BA_ "ECGUsedRxSignal" SG_ 1055 EcoCochInstNeg_B_Dsply 1;
BA_ "U_T6_MCA_MY2020_Rx" SG_ 1055 EcoCochInstNeg_B_Dsply 1;
BA_ "U_U55X_MY2022_Tx" SG_ 1055 EcoCochShif_Pc_Dsply 1;
BA_ "U_CD542_MY2021_Tx" SG_ 1055 EcoCochShif_Pc_Dsply 1;
BA_ "U_T6_MCA_MY2020_Tx" SG_ 1055 EcoCochShif_Pc_Dsply 1;
BA_ "U_P702_MY2021_Tx" SG_ 1055 EcoCochShif_Pc_Dsply 1;
BA_ "U_CX727_MY2021_Tx" SG_ 1055 EcoCochShif_Pc_Dsply 1;
BA_ "ECGUsedRxSignal" SG_ 1055 EcoCochShif_Pc_Dsply 1;
BA_ "U_T6_MCA_MY2020_Rx" SG_ 1055 EcoCochShif_Pc_Dsply 1;
BA_ "GenSigStartValue" SG_ 1055 EcoCochShif_Pc_Dsply 255;
BA_ "GenSigStartValueInteger" SG_ 1055 EcoCochShif_Pc_Dsply 255;
BA_ "U_U55X_MY2022_Tx" SG_ 1055 EcoCochInst_Pc_Dsply 1;
BA_ "U_CD542_MY2021_Tx" SG_ 1055 EcoCochInst_Pc_Dsply 1;
BA_ "U_T6_MCA_MY2020_Tx" SG_ 1055 EcoCochInst_Pc_Dsply 1;
BA_ "U_P702_MY2021_Tx" SG_ 1055 EcoCochInst_Pc_Dsply 1;
BA_ "U_CX727_MY2021_Tx" SG_ 1055 EcoCochInst_Pc_Dsply 1;
BA_ "ECGUsedRxSignal" SG_ 1055 EcoCochInst_Pc_Dsply 1;
BA_ "U_T6_MCA_MY2020_Rx" SG_ 1055 EcoCochInst_Pc_Dsply 1;
BA_ "GenSigStartValue" SG_ 1055 EcoCochInst_Pc_Dsply 100;
BA_ "GenSigStartValueInteger" SG_ 1055 EcoCochInst_Pc_Dsply 1000;
BA_ "U_U55X_MY2022_Tx" SG_ 1055 EcoCochIdlFuel_Pc_Dsply 1;
BA_ "U_CD542_MY2021_Tx" SG_ 1055 EcoCochIdlFuel_Pc_Dsply 1;
BA_ "U_T6_MCA_MY2020_Tx" SG_ 1055 EcoCochIdlFuel_Pc_Dsply 1;
BA_ "U_P702_MY2021_Tx" SG_ 1055 EcoCochIdlFuel_Pc_Dsply 1;
BA_ "U_CX727_MY2021_Tx" SG_ 1055 EcoCochIdlFuel_Pc_Dsply 1;
BA_ "ECGUsedRxSignal" SG_ 1055 EcoCochIdlFuel_Pc_Dsply 1;
BA_ "U_T6_MCA_MY2020_Rx" SG_ 1055 EcoCochIdlFuel_Pc_Dsply 1;
BA_ "GenSigStartValue" SG_ 1055 EcoCochIdlFuel_Pc_Dsply 255;
BA_ "GenSigStartValueInteger" SG_ 1055 EcoCochIdlFuel_Pc_Dsply 255;
BA_ "U_U55X_MY2022_Tx" SG_ 1055 EcoCochDecel_Pc_Dsply 1;
BA_ "U_CD542_MY2021_Tx" SG_ 1055 EcoCochDecel_Pc_Dsply 1;
BA_ "U_T6_MCA_MY2020_Tx" SG_ 1055 EcoCochDecel_Pc_Dsply 1;
BA_ "U_P702_MY2021_Tx" SG_ 1055 EcoCochDecel_Pc_Dsply 1;
BA_ "U_CX727_MY2021_Tx" SG_ 1055 EcoCochDecel_Pc_Dsply 1;
BA_ "ECGUsedRxSignal" SG_ 1055 EcoCochDecel_Pc_Dsply 1;
BA_ "U_T6_MCA_MY2020_Rx" SG_ 1055 EcoCochDecel_Pc_Dsply 1;
BA_ "GenSigStartValue" SG_ 1055 EcoCochDecel_Pc_Dsply 255;
BA_ "GenSigStartValueInteger" SG_ 1055 EcoCochDecel_Pc_Dsply 255;
BA_ "U_U55X_MY2022_Tx" SG_ 1055 EcoCochCrus_Pc_Dsply 1;
BA_ "U_CD542_MY2021_Tx" SG_ 1055 EcoCochCrus_Pc_Dsply 1;
BA_ "U_T6_MCA_MY2020_Tx" SG_ 1055 EcoCochCrus_Pc_Dsply 1;
BA_ "U_P702_MY2021_Tx" SG_ 1055 EcoCochCrus_Pc_Dsply 1;
BA_ "U_CX727_MY2021_Tx" SG_ 1055 EcoCochCrus_Pc_Dsply 1;
BA_ "ECGUsedRxSignal" SG_ 1055 EcoCochCrus_Pc_Dsply 1;
BA_ "U_T6_MCA_MY2020_Rx" SG_ 1055 EcoCochCrus_Pc_Dsply 1;
BA_ "GenSigStartValue" SG_ 1055 EcoCochCrus_Pc_Dsply 255;
BA_ "GenSigStartValueInteger" SG_ 1055 EcoCochCrus_Pc_Dsply 255;
BA_ "U_U55X_MY2022_Tx" SG_ 1055 EcoCochA_Pc_Dsply 1;
BA_ "U_CD542_MY2021_Tx" SG_ 1055 EcoCochA_Pc_Dsply 1;
BA_ "U_T6_MCA_MY2020_Tx" SG_ 1055 EcoCochA_Pc_Dsply 1;
BA_ "U_P702_MY2021_Tx" SG_ 1055 EcoCochA_Pc_Dsply 1;
BA_ "U_CX727_MY2021_Tx" SG_ 1055 EcoCochA_Pc_Dsply 1;
BA_ "ECGUsedRxSignal" SG_ 1055 EcoCochA_Pc_Dsply 1;
BA_ "U_T6_MCA_MY2020_Rx" SG_ 1055 EcoCochA_Pc_Dsply 1;
BA_ "GenSigStartValue" SG_ 1055 EcoCochA_Pc_Dsply 255;
BA_ "GenSigStartValueInteger" SG_ 1055 EcoCochA_Pc_Dsply 255;
BA_ "U_CX727_MY2021_Tx" SG_ 610 AwdLckWhlRr_Pc_RqDsply 1;
BA_ "U_T6_MCA_MY2020_Tx" SG_ 610 AwdLckWhlRr_Pc_RqDsply 1;
BA_ "U_CX727_MY2021_Tx" SG_ 610 AwdLckWhlRl_Pc_RqDsply 1;
BA_ "U_T6_MCA_MY2020_Tx" SG_ 610 AwdLckWhlRl_Pc_RqDsply 1;
BA_ "U_CX727_MY2021_Tx" SG_ 610 AwdLckWhlFr_Pc_RqDsply 1;
BA_ "U_T6_MCA_MY2020_Tx" SG_ 610 AwdLckWhlFr_Pc_RqDsply 1;
BA_ "U_CX727_MY2021_Tx" SG_ 610 AwdLckWhlFl_Pc_RqDsply 1;
BA_ "U_T6_MCA_MY2020_Tx" SG_ 610 AwdLckWhlFl_Pc_RqDsply 1;
BA_ "U_CD542_MY2021_Tx" SG_ 562 GearNtrl_No_Cs 1;
BA_ "U_T6_MCA_MY2020_Tx" SG_ 562 GearNtrl_No_Cs 1;
BA_ "U_P702_MY2021_Tx" SG_ 562 GearNtrl_No_Cs 1;
BA_ "U_CD542_MY2021_Rx" SG_ 562 GearNtrl_No_Cs 1;
BA_ "U_T6_MCA_MY2020_Rx" SG_ 562 GearNtrl_No_Cs 1;
BA_ "U_CX727_MY2021_Rx" SG_ 562 GearNtrl_No_Cs 1;
BA_ "MetaData" SG_ 562 GearNtrl_No_Cs 1;
BA_ "ContentDependant" SG_ 562 GearNtrl_No_Cs 1;
BA_ "U_CD542_MY2021_Tx" SG_ 562 GearNtrl_D_Stat 1;
BA_ "U_T6_MCA_MY2020_Tx" SG_ 562 GearNtrl_D_Stat 1;
BA_ "U_P702_MY2021_Tx" SG_ 562 GearNtrl_D_Stat 1;
BA_ "U_U55X_MY2022_Rx" SG_ 562 GearNtrl_D_Stat 1;
BA_ "U_CD542_MY2021_Rx" SG_ 562 GearNtrl_D_Stat 1;
BA_ "U_T6_MCA_MY2020_Rx" SG_ 562 GearNtrl_D_Stat 1;
BA_ "U_P702_MY2021_Rx" SG_ 562 GearNtrl_D_Stat 1;
BA_ "U_CX727_MY2021_Rx" SG_ 562 GearNtrl_D_Stat 1;
BA_ "GenSigSendType" SG_ 562 GearNtrl_D_Stat 3;
BA_ "GenSigStartValue" SG_ 562 GearNtrl_D_Stat 2;
BA_ "GenSigStartValueInteger" SG_ 562 GearNtrl_D_Stat 2;
BA_ "GenSigSendType" SG_ 562 OnePdlDrv_D_Stat 3;
BA_ "U_CD542_MY2021_Tx" SG_ 562 GearNtrl_No_Cnt 1;
BA_ "U_T6_MCA_MY2020_Tx" SG_ 562 GearNtrl_No_Cnt 1;
BA_ "U_P702_MY2021_Tx" SG_ 562 GearNtrl_No_Cnt 1;
BA_ "U_CD542_MY2021_Rx" SG_ 562 GearNtrl_No_Cnt 1;
BA_ "U_T6_MCA_MY2020_Rx" SG_ 562 GearNtrl_No_Cnt 1;
BA_ "U_CX727_MY2021_Rx" SG_ 562 GearNtrl_No_Cnt 1;
BA_ "MetaData" SG_ 562 GearNtrl_No_Cnt 1;
BA_ "ContentDependant" SG_ 562 GearNtrl_No_Cnt 1;
BA_ "U_T6_MCA_MY2020_Tx" SG_ 523 EngAirFiltMsgTxt_D_Rq 1;
BA_ "U_P702_MY2021_Tx" SG_ 523 EngAirFiltMsgTxt_D_Rq 1;
BA_ "U_T6_MCA_MY2020_Tx" SG_ 523 WaterInFuel_B_Falt 1;
BA_ "U_P702_MY2021_Tx" SG_ 523 WaterInFuel_B_Falt 1;
BA_ "U_T6_MCA_MY2020_Tx" SG_ 523 UreaMnAdd_L2_Actl 1;
BA_ "U_P702_MY2021_Tx" SG_ 523 UreaMnAdd_L2_Actl 1;
BA_ "U_T6_MCA_MY2020_Tx" SG_ 523 VehUreaRnge3_L_DsplyMx 1;
BA_ "U_P702_MY2021_Tx" SG_ 523 VehUreaRnge3_L_DsplyMx 1;
BA_ "ECGUsedRxSignal" SG_ 523 VehUreaRnge3_L_DsplyMx 1;
BA_ "U_T6_MCA_MY2020_Rx" SG_ 523 VehUreaRnge3_L_DsplyMx 1;
BA_ "U_T6_MCA_MY2020_Tx" SG_ 523 UreaMxAdd_L2_Actl 1;
BA_ "U_P702_MY2021_Tx" SG_ 523 UreaMxAdd_L2_Actl 1;
BA_ "GenSigStartValue" SG_ 523 UreaMxAdd_L2_Actl 510;
BA_ "GenSigStartValueInteger" SG_ 523 UreaMxAdd_L2_Actl 510;
BA_ "GenSigStartValue" SG_ 519 RearDiffLck_Tq_Rq 16382;
BA_ "GenSigStartValueInteger" SG_ 519 RearDiffLck_Tq_Rq 16382;
BA_ "U_CX727_MY2021_Tx" SG_ 517 FapLc_B_Err 1;
BA_ "U_CD542_MY2021_Tx" SG_ 517 FapLc_B_Err 1;
BA_ "U_T6_MCA_MY2020_Tx" SG_ 517 FapLc_B_Err 1;
BA_ "U_P702_MY2021_Tx" SG_ 517 FapLc_B_Err 1;
BA_ "U_CD542_MY2021_Rx" SG_ 517 FapLc_B_Err 1;
BA_ "U_T6_MCA_MY2020_Rx" SG_ 517 FapLc_B_Err 1;
BA_ "U_CX727_MY2021_Tx" SG_ 517 BrkTot_Tq_RqFapLc 1;
BA_ "U_CD542_MY2021_Tx" SG_ 517 BrkTot_Tq_RqFapLc 1;
BA_ "U_T6_MCA_MY2020_Tx" SG_ 517 BrkTot_Tq_RqFapLc 1;
BA_ "U_P702_MY2021_Tx" SG_ 517 BrkTot_Tq_RqFapLc 1;
BA_ "U_U55X_MY2022_Rx" SG_ 517 BrkTot_Tq_RqFapLc 1;
BA_ "U_CD542_MY2021_Rx" SG_ 517 BrkTot_Tq_RqFapLc 1;
BA_ "U_T6_MCA_MY2020_Rx" SG_ 517 BrkTot_Tq_RqFapLc 1;
BA_ "U_P702_MY2021_Rx" SG_ 517 BrkTot_Tq_RqFapLc 1;
BA_ "U_CX727_MY2021_Rx" SG_ 517 BrkTot_Tq_RqFapLc 1;
BA_ "U_CD542_MY2021_Tx" SG_ 517 TrnAin_Pc_RqDrv 1;
BA_ "U_T6_MCA_MY2020_Tx" SG_ 517 TrnAin_Pc_RqDrv 1;
BA_ "U_P702_MY2021_Tx" SG_ 517 TrnAin_Pc_RqDrv 1;
BA_ "U_T6_MCA_MY2020_Rx" SG_ 517 TrnAin_Pc_RqDrv 1;
BA_ "U_T6_MCA_MY2020_Tx" SG_ 516 EngAoutNActl_D_QF 1;
BA_ "U_P702_MY2021_Tx" SG_ 516 EngAoutNActl_D_QF 1;
BA_ "U_CX727_MY2021_Tx" SG_ 516 EngAoutNActl_D_QF 1;
BA_ "U_T6_MCA_MY2020_Rx" SG_ 516 EngAoutNActl_D_QF 1;
BA_ "U_P702_MY2021_Rx" SG_ 516 EngAoutNActl_D_QF 1;
BA_ "GenSigStartValue" SG_ 516 EngAoutNActl_D_QF 1;
BA_ "MetaData" SG_ 516 EngAoutNActl_D_QF 1;
BA_ "GenSigStartValueInteger" SG_ 516 EngAoutNActl_D_QF 1;
BA_ "U_CD542_MY2021_Tx" SG_ 516 EngAout3_N_Actl 1;
BA_ "U_P702_MY2021_Tx" SG_ 516 EngAout3_N_Actl 1;
BA_ "U_CD542_MY2021_Rx" SG_ 516 EngAout3_N_Actl 1;
BA_ "U_P702_MY2021_Rx" SG_ 516 EngAout3_N_Actl 1;
BA_ "U_CX727_MY2021_Rx" SG_ 516 EngAout3_N_Actl 1;
BA_ "ContentDependant" SG_ 516 EngAout3_N_Actl 1;
BA_ "U_CX727_MY2021_Tx" SG_ 516 ApedPos_Pc_ActlArb 1;
BA_ "U_U55X_MY2022_Tx" SG_ 516 ApedPos_Pc_ActlArb 1;
BA_ "U_CD542_MY2021_Tx" SG_ 516 ApedPos_Pc_ActlArb 1;
BA_ "U_T6_MCA_MY2020_Tx" SG_ 516 ApedPos_Pc_ActlArb 1;
BA_ "U_P702_MY2021_Tx" SG_ 516 ApedPos_Pc_ActlArb 1;
BA_ "ECGUsedRxSignal" SG_ 516 ApedPos_Pc_ActlArb 1;
BA_ "U_U55X_MY2022_Rx" SG_ 516 ApedPos_Pc_ActlArb 1;
BA_ "U_T6_MCA_MY2020_Rx" SG_ 516 ApedPos_Pc_ActlArb 1;
BA_ "U_CD542_MY2021_Rx" SG_ 516 ApedPos_Pc_ActlArb 1;
BA_ "U_P702_MY2021_Rx" SG_ 516 ApedPos_Pc_ActlArb 1;
BA_ "U_CX727_MY2021_Rx" SG_ 516 ApedPos_Pc_ActlArb 1;
BA_ "U_CX727_MY2021_Tx" SG_ 516 ApedPosPcActl_D_Qf 1;
BA_ "U_U55X_MY2022_Tx" SG_ 516 ApedPosPcActl_D_Qf 1;
BA_ "U_CD542_MY2021_Tx" SG_ 516 ApedPosPcActl_D_Qf 1;
BA_ "U_T6_MCA_MY2020_Tx" SG_ 516 ApedPosPcActl_D_Qf 1;
BA_ "U_P702_MY2021_Tx" SG_ 516 ApedPosPcActl_D_Qf 1;
BA_ "U_U55X_MY2022_Rx" SG_ 516 ApedPosPcActl_D_Qf 1;
BA_ "U_T6_MCA_MY2020_Rx" SG_ 516 ApedPosPcActl_D_Qf 1;
BA_ "U_CD542_MY2021_Rx" SG_ 516 ApedPosPcActl_D_Qf 1;
BA_ "U_P702_MY2021_Rx" SG_ 516 ApedPosPcActl_D_Qf 1;
BA_ "U_CX727_MY2021_Rx" SG_ 516 ApedPosPcActl_D_Qf 1;
BA_ "GenSigStartValue" SG_ 516 ApedPosPcActl_D_Qf 1;
BA_ "MetaData" SG_ 516 ApedPosPcActl_D_Qf 1;
BA_ "GenSigStartValueInteger" SG_ 516 ApedPosPcActl_D_Qf 1;
BA_ "U_CX727_MY2021_Tx" SG_ 516 EngAout_N_Actl 1;
BA_ "U_U55X_MY2022_Tx" SG_ 516 EngAout_N_Actl 1;
BA_ "U_CD542_MY2021_Tx" SG_ 516 EngAout_N_Actl 1;
BA_ "U_T6_MCA_MY2020_Tx" SG_ 516 EngAout_N_Actl 1;
BA_ "U_P702_MY2021_Tx" SG_ 516 EngAout_N_Actl 1;
BA_ "ECGUsedRxSignal" SG_ 516 EngAout_N_Actl 1;
BA_ "U_U55X_MY2022_Rx" SG_ 516 EngAout_N_Actl 1;
BA_ "U_CD542_MY2021_Rx" SG_ 516 EngAout_N_Actl 1;
BA_ "U_CX727_MY2021_Rx" SG_ 516 EngAout_N_Actl 1;
BA_ "U_T6_MCA_MY2020_Rx" SG_ 516 EngAout_N_Actl 1;
BA_ "U_P702_MY2021_Rx" SG_ 516 EngAout_N_Actl 1;
BA_ "U_T6_MCA_MY2020_Tx" SG_ 516 ApedPosPcActl_No_Cnt 1;
BA_ "U_CX727_MY2021_Tx" SG_ 516 ApedPosPcActl_No_Cnt 1;
BA_ "U_CD542_MY2021_Tx" SG_ 516 ApedPosPcActl_No_Cnt 1;
BA_ "U_P702_MY2021_Tx" SG_ 516 ApedPosPcActl_No_Cnt 1;
BA_ "U_U55X_MY2022_Rx" SG_ 516 ApedPosPcActl_No_Cnt 1;
BA_ "U_CD542_MY2021_Rx" SG_ 516 ApedPosPcActl_No_Cnt 1;
BA_ "U_P702_MY2021_Rx" SG_ 516 ApedPosPcActl_No_Cnt 1;
BA_ "U_CX727_MY2021_Rx" SG_ 516 ApedPosPcActl_No_Cnt 1;
BA_ "MetaData" SG_ 516 ApedPosPcActl_No_Cnt 1;
BA_ "ContentDependant" SG_ 516 ApedPosPcActl_No_Cnt 1;
BA_ "U_T6_MCA_MY2020_Tx" SG_ 516 ApedPosPcActl_No_Cs 1;
BA_ "U_CX727_MY2021_Tx" SG_ 516 ApedPosPcActl_No_Cs 1;
BA_ "U_CD542_MY2021_Tx" SG_ 516 ApedPosPcActl_No_Cs 1;
BA_ "U_P702_MY2021_Tx" SG_ 516 ApedPosPcActl_No_Cs 1;
BA_ "U_U55X_MY2022_Rx" SG_ 516 ApedPosPcActl_No_Cs 1;
BA_ "U_CD542_MY2021_Rx" SG_ 516 ApedPosPcActl_No_Cs 1;
BA_ "U_P702_MY2021_Rx" SG_ 516 ApedPosPcActl_No_Cs 1;
BA_ "U_CX727_MY2021_Rx" SG_ 516 ApedPosPcActl_No_Cs 1;
BA_ "MetaData" SG_ 516 ApedPosPcActl_No_Cs 1;
BA_ "ContentDependant" SG_ 516 ApedPosPcActl_No_Cs 1;
BA_ "U_CX727_MY2021_Tx" SG_ 516 ApedPos_PcRate_ActlArb 1;
BA_ "U_U55X_MY2022_Tx" SG_ 516 ApedPos_PcRate_ActlArb 1;
BA_ "U_CD542_MY2021_Tx" SG_ 516 ApedPos_PcRate_ActlArb 1;
BA_ "U_T6_MCA_MY2020_Tx" SG_ 516 ApedPos_PcRate_ActlArb 1;
BA_ "U_P702_MY2021_Tx" SG_ 516 ApedPos_PcRate_ActlArb 1;
BA_ "U_T6_MCA_MY2020_Rx" SG_ 516 ApedPos_PcRate_ActlArb 1;
BA_ "U_P702_MY2021_Rx" SG_ 516 ApedPos_PcRate_ActlArb 1;
BA_ "U_CX727_MY2021_Tx" SG_ 514 StrtrMtrDlyStrt_B_Stat 1;
BA_ "U_U55X_MY2022_Tx" SG_ 514 StrtrMtrDlyStrt_B_Stat 1;
BA_ "U_CD542_MY2021_Tx" SG_ 514 StrtrMtrDlyStrt_B_Stat 1;
BA_ "U_T6_MCA_MY2020_Tx" SG_ 514 StrtrMtrDlyStrt_B_Stat 1;
BA_ "U_P702_MY2021_Tx" SG_ 514 StrtrMtrDlyStrt_B_Stat 1;
BA_ "U_U55X_MY2022_Tx" SG_ 514 VehVTrlrAid_B_Avail 1;
BA_ "U_T6_MCA_MY2020_Tx" SG_ 514 VehVTrlrAid_B_Avail 1;
BA_ "U_P702_MY2021_Tx" SG_ 514 VehVTrlrAid_B_Avail 1;
BA_ "U_T6_MCA_MY2020_Rx" SG_ 514 VehVTrlrAid_B_Avail 1;
BA_ "U_P702_MY2021_Rx" SG_ 514 VehVTrlrAid_B_Avail 1;
BA_ "U_CX727_MY2021_Tx" SG_ 514 StrtrMtrCtlMsgTxt_D_Rq 1;
BA_ "U_U55X_MY2022_Tx" SG_ 514 StrtrMtrCtlMsgTxt_D_Rq 1;
BA_ "U_CD542_MY2021_Tx" SG_ 514 StrtrMtrCtlMsgTxt_D_Rq 1;
BA_ "U_T6_MCA_MY2020_Tx" SG_ 514 StrtrMtrCtlMsgTxt_D_Rq 1;
BA_ "U_P702_MY2021_Tx" SG_ 514 StrtrMtrCtlMsgTxt_D_Rq 1;
BA_ "U_CX727_MY2021_Tx" SG_ 514 VehVActlEng_No_Cs 1;
BA_ "U_U55X_MY2022_Tx" SG_ 514 VehVActlEng_No_Cs 1;
BA_ "U_CD542_MY2021_Tx" SG_ 514 VehVActlEng_No_Cs 1;
BA_ "U_T6_MCA_MY2020_Tx" SG_ 514 VehVActlEng_No_Cs 1;
BA_ "U_P702_MY2021_Tx" SG_ 514 VehVActlEng_No_Cs 1;
BA_ "U_CD542_MY2021_Rx" SG_ 514 VehVActlEng_No_Cs 1;
BA_ "U_T6_MCA_MY2020_Rx" SG_ 514 VehVActlEng_No_Cs 1;
BA_ "U_P702_MY2021_Rx" SG_ 514 VehVActlEng_No_Cs 1;
BA_ "U_CX727_MY2021_Rx" SG_ 514 VehVActlEng_No_Cs 1;
BA_ "MetaData" SG_ 514 VehVActlEng_No_Cs 1;
BA_ "U_CX727_MY2021_Tx" SG_ 514 VehVActlEng_No_Cnt 1;
BA_ "U_U55X_MY2022_Tx" SG_ 514 VehVActlEng_No_Cnt 1;
BA_ "U_CD542_MY2021_Tx" SG_ 514 VehVActlEng_No_Cnt 1;
BA_ "U_T6_MCA_MY2020_Tx" SG_ 514 VehVActlEng_No_Cnt 1;
BA_ "U_P702_MY2021_Tx" SG_ 514 VehVActlEng_No_Cnt 1;
BA_ "U_CD542_MY2021_Rx" SG_ 514 VehVActlEng_No_Cnt 1;
BA_ "U_T6_MCA_MY2020_Rx" SG_ 514 VehVActlEng_No_Cnt 1;
BA_ "U_P702_MY2021_Rx" SG_ 514 VehVActlEng_No_Cnt 1;
BA_ "U_CX727_MY2021_Rx" SG_ 514 VehVActlEng_No_Cnt 1;
BA_ "MetaData" SG_ 514 VehVActlEng_No_Cnt 1;
BA_ "U_CX727_MY2021_Tx" SG_ 514 Veh_V_RqCcSet 1;
BA_ "U_U55X_MY2022_Tx" SG_ 514 Veh_V_RqCcSet 1;
BA_ "U_CD542_MY2021_Tx" SG_ 514 Veh_V_RqCcSet 1;
BA_ "U_T6_MCA_MY2020_Tx" SG_ 514 Veh_V_RqCcSet 1;
BA_ "U_P702_MY2021_Tx" SG_ 514 Veh_V_RqCcSet 1;
BA_ "U_CD542_MY2021_Rx" SG_ 514 Veh_V_RqCcSet 1;
BA_ "U_U55X_MY2022_Rx" SG_ 514 Veh_V_RqCcSet 1;
BA_ "U_CX727_MY2021_Rx" SG_ 514 Veh_V_RqCcSet 1;
BA_ "U_T6_MCA_MY2020_Rx" SG_ 514 Veh_V_RqCcSet 1;
BA_ "U_P702_MY2021_Rx" SG_ 514 Veh_V_RqCcSet 1;
BA_ "U_CX727_MY2021_Tx" SG_ 514 VehVActlEng_D_Qf 1;
BA_ "U_U55X_MY2022_Tx" SG_ 514 VehVActlEng_D_Qf 1;
BA_ "U_CD542_MY2021_Tx" SG_ 514 VehVActlEng_D_Qf 1;
BA_ "U_T6_MCA_MY2020_Tx" SG_ 514 VehVActlEng_D_Qf 1;
BA_ "U_P702_MY2021_Tx" SG_ 514 VehVActlEng_D_Qf 1;
BA_ "U_U55X_MY2022_Rx" SG_ 514 VehVActlEng_D_Qf 1;
BA_ "U_CD542_MY2021_Rx" SG_ 514 VehVActlEng_D_Qf 1;
BA_ "U_CX727_MY2021_Rx" SG_ 514 VehVActlEng_D_Qf 1;
BA_ "U_T6_MCA_MY2020_Rx" SG_ 514 VehVActlEng_D_Qf 1;
BA_ "U_P702_MY2021_Rx" SG_ 514 VehVActlEng_D_Qf 1;
BA_ "MetaData" SG_ 514 VehVActlEng_D_Qf 1;
BA_ "U_CX727_MY2021_Tx" SG_ 514 Veh_V_ActlEng 1;
BA_ "U_U55X_MY2022_Tx" SG_ 514 Veh_V_ActlEng 1;
BA_ "U_CD542_MY2021_Tx" SG_ 514 Veh_V_ActlEng 1;
BA_ "U_T6_MCA_MY2020_Tx" SG_ 514 Veh_V_ActlEng 1;
BA_ "U_P702_MY2021_Tx" SG_ 514 Veh_V_ActlEng 1;
BA_ "ECGUsedRxSignal" SG_ 514 Veh_V_ActlEng 1;
BA_ "U_U55X_MY2022_Rx" SG_ 514 Veh_V_ActlEng 1;
BA_ "U_T6_MCA_MY2020_Rx" SG_ 514 Veh_V_ActlEng 1;
BA_ "U_CD542_MY2021_Rx" SG_ 514 Veh_V_ActlEng 1;
BA_ "U_P702_MY2021_Rx" SG_ 514 Veh_V_ActlEng 1;
BA_ "U_CX727_MY2021_Rx" SG_ 514 Veh_V_ActlEng 1;
BA_ "U_CD542_MY2021_Tx" SG_ 514 EngAout_Tq_VacLimSpcN 1;
BA_ "U_CX727_MY2021_Tx" SG_ 514 EngAout_Tq_VacLimSpcN 1;
BA_ "U_CD542_MY2021_Rx" SG_ 514 EngAout_Tq_VacLimSpcN 1;
BA_ "U_CX727_MY2021_Rx" SG_ 514 EngAout_Tq_VacLimSpcN 1;
BA_ "ContentDependant" SG_ 514 EngAout_Tq_VacLimSpcN 1;
BA_ "U_CD542_MY2021_Tx" SG_ 514 EngCylSync_No_Ctr 1;
BA_ "U_CX727_MY2021_Tx" SG_ 514 EngCylSync_No_Ctr 1;
BA_ "U_CD542_MY2021_Rx" SG_ 514 EngCylSync_No_Ctr 1;
BA_ "U_CX727_MY2021_Rx" SG_ 514 EngCylSync_No_Ctr 1;
BA_ "ContentDependant" SG_ 514 EngCylSync_No_Ctr 1;
BA_ "U_CX727_MY2021_Tx" SG_ 514 GearRvrse_D_Actl 1;
BA_ "U_U55X_MY2022_Tx" SG_ 514 GearRvrse_D_Actl 1;
BA_ "U_CD542_MY2021_Tx" SG_ 514 GearRvrse_D_Actl 1;
BA_ "U_T6_MCA_MY2020_Tx" SG_ 514 GearRvrse_D_Actl 1;
BA_ "U_P702_MY2021_Tx" SG_ 514 GearRvrse_D_Actl 1;
BA_ "ECGUsedRxSignal" SG_ 514 GearRvrse_D_Actl 1;
BA_ "U_U55X_MY2022_Rx" SG_ 514 GearRvrse_D_Actl 1;
BA_ "U_CD542_MY2021_Rx" SG_ 514 GearRvrse_D_Actl 1;
BA_ "U_P702_MY2021_Rx" SG_ 514 GearRvrse_D_Actl 1;
BA_ "U_CX727_MY2021_Rx" SG_ 514 GearRvrse_D_Actl 1;
BA_ "U_T6_MCA_MY2020_Rx" SG_ 514 GearRvrse_D_Actl 1;
BA_ "GenSigStartValue" SG_ 514 GearRvrse_D_Actl 7;
BA_ "GenSigStartValueInteger" SG_ 514 GearRvrse_D_Actl 7;
BA_ "U_U55X_MY2022_Tx" SG_ 514 StrtrMtrCtlMsgTxt_D2_Rq 1;
BA_ "U_CD542_MY2021_Tx" SG_ 514 StrtrMtrCtlMsgTxt_D2_Rq 1;
BA_ "U_T6_MCA_MY2020_Tx" SG_ 514 StrtrMtrCtlMsgTxt_D2_Rq 1;
BA_ "U_P702_MY2021_Tx" SG_ 514 StrtrMtrCtlMsgTxt_D2_Rq 1;
BA_ "U_CD542_MY2021_Tx" SG_ 512 PrplWhlTotTqRq_No_Cs 1;
BA_ "U_CX727_MY2021_Tx" SG_ 512 PrplWhlTotTqRq_No_Cs 1;
BA_ "U_P702_MY2021_Tx" SG_ 512 PrplWhlTotTqRq_No_Cs 1;
BA_ "U_U55X_MY2022_Rx" SG_ 512 PrplWhlTotTqRq_No_Cs 1;
BA_ "U_P702_MY2021_Rx" SG_ 512 PrplWhlTotTqRq_No_Cs 1;
BA_ "U_CD542_MY2021_Rx" SG_ 512 PrplWhlTotTqRq_No_Cs 1;
BA_ "U_CX727_MY2021_Rx" SG_ 512 PrplWhlTotTqRq_No_Cs 1;
BA_ "MetaData" SG_ 512 PrplWhlTotTqRq_No_Cs 1;
BA_ "ContentDependant" SG_ 512 PrplWhlTotTqRq_No_Cs 1;
BA_ "U_CD542_MY2021_Tx" SG_ 512 PrplWhlTotTqRq_No_Cnt 1;
BA_ "U_CX727_MY2021_Tx" SG_ 512 PrplWhlTotTqRq_No_Cnt 1;
BA_ "U_P702_MY2021_Tx" SG_ 512 PrplWhlTotTqRq_No_Cnt 1;
BA_ "U_U55X_MY2022_Rx" SG_ 512 PrplWhlTotTqRq_No_Cnt 1;
BA_ "U_P702_MY2021_Rx" SG_ 512 PrplWhlTotTqRq_No_Cnt 1;
BA_ "U_CD542_MY2021_Rx" SG_ 512 PrplWhlTotTqRq_No_Cnt 1;
BA_ "U_CX727_MY2021_Rx" SG_ 512 PrplWhlTotTqRq_No_Cnt 1;
BA_ "MetaData" SG_ 512 PrplWhlTotTqRq_No_Cnt 1;
BA_ "ContentDependant" SG_ 512 PrplWhlTotTqRq_No_Cnt 1;
BA_ "U_CD542_MY2021_Tx" SG_ 512 EngAout_Tq_MxMxN 1;
BA_ "U_CX727_MY2021_Tx" SG_ 512 EngAout_Tq_MxMxN 1;
BA_ "U_CD542_MY2021_Rx" SG_ 512 EngAout_Tq_MxMxN 1;
BA_ "U_CX727_MY2021_Rx" SG_ 512 EngAout_Tq_MxMxN 1;
BA_ "ContentDependant" SG_ 512 EngAout_Tq_MxMxN 1;
BA_ "U_CX727_MY2021_Tx" SG_ 512 PrplWhlTot_Tq_Rq 1;
BA_ "U_U55X_MY2022_Tx" SG_ 512 PrplWhlTot_Tq_Rq 1;
BA_ "U_CD542_MY2021_Tx" SG_ 512 PrplWhlTot_Tq_Rq 1;
BA_ "U_T6_MCA_MY2020_Tx" SG_ 512 PrplWhlTot_Tq_Rq 1;
BA_ "U_P702_MY2021_Tx" SG_ 512 PrplWhlTot_Tq_Rq 1;
BA_ "U_U55X_MY2022_Rx" SG_ 512 PrplWhlTot_Tq_Rq 1;
BA_ "U_T6_MCA_MY2020_Rx" SG_ 512 PrplWhlTot_Tq_Rq 1;
BA_ "U_P702_MY2021_Rx" SG_ 512 PrplWhlTot_Tq_Rq 1;
BA_ "U_CD542_MY2021_Rx" SG_ 512 PrplWhlTot_Tq_Rq 1;
BA_ "U_CX727_MY2021_Rx" SG_ 512 PrplWhlTot_Tq_Rq 1;
BA_ "U_CX727_MY2021_Tx" SG_ 512 PrplWhlTot_Tq_LimMn 1;
BA_ "U_U55X_MY2022_Tx" SG_ 512 PrplWhlTot_Tq_LimMn 1;
BA_ "U_CD542_MY2021_Tx" SG_ 512 PrplWhlTot_Tq_LimMn 1;
BA_ "U_T6_MCA_MY2020_Tx" SG_ 512 PrplWhlTot_Tq_LimMn 1;
BA_ "U_P702_MY2021_Tx" SG_ 512 PrplWhlTot_Tq_LimMn 1;
BA_ "U_U55X_MY2022_Rx" SG_ 512 PrplWhlTot_Tq_LimMn 1;
BA_ "U_CD542_MY2021_Rx" SG_ 512 PrplWhlTot_Tq_LimMn 1;
BA_ "U_T6_MCA_MY2020_Rx" SG_ 512 PrplWhlTot_Tq_LimMn 1;
BA_ "U_P702_MY2021_Rx" SG_ 512 PrplWhlTot_Tq_LimMn 1;
BA_ "U_CX727_MY2021_Rx" SG_ 512 PrplWhlTot_Tq_LimMn 1;
BA_ "U_T6_MCA_MY2020_Tx" SG_ 512 PtDrvMde_D_Stat 1;
BA_ "U_P702_MY2021_Tx" SG_ 512 PtDrvMde_D_Stat 1;
BA_ "U_CD542_MY2021_Rx" SG_ 512 PtDrvMde_D_Stat 1;
BA_ "U_T6_MCA_MY2020_Rx" SG_ 512 PtDrvMde_D_Stat 1;
BA_ "GenSigStartValue" SG_ 382 EngMnfldChrg_Te_Actl 126;
BA_ "GenSigStartValueInteger" SG_ 382 EngMnfldChrg_Te_Actl 126;
BA_ "GenSigStartValue" SG_ 382 EngInnrClnt_Te_Actl 126;
BA_ "GenSigStartValueInteger" SG_ 382 EngInnrClnt_Te_Actl 56;
BA_ "U_T6_MCA_MY2020_Tx" SG_ 381 EngOilLife_T_Actl 1;
BA_ "U_P702_MY2021_Tx" SG_ 381 EngOilLife_T_Actl 1;
BA_ "U_T6_MCA_MY2020_Tx" SG_ 381 EngOilSrvcMsgTxt_D_Rq 1;
BA_ "U_P702_MY2021_Tx" SG_ 381 EngOilSrvcMsgTxt_D_Rq 1;
BA_ "ECGUsedRxSignal" SG_ 381 EngOilSrvcMsgTxt_D_Rq 1;
BA_ "U_T6_MCA_MY2020_Rx" SG_ 381 EngOilSrvcMsgTxt_D_Rq 1;
BA_ "U_T6_MCA_MY2020_Tx" SG_ 381 DistToNextOilChange 1;
BA_ "U_P702_MY2021_Tx" SG_ 381 DistToNextOilChange 1;
BA_ "U_T6_MCA_MY2020_Tx" SG_ 381 RunDryPrevent_B_Stat 1;
BA_ "U_P702_MY2021_Tx" SG_ 381 RunDryPrevent_B_Stat 1;
BA_ "U_T6_MCA_MY2020_Tx" SG_ 381 WaterInFuel 1;
BA_ "U_P702_MY2021_Tx" SG_ 381 WaterInFuel 1;
BA_ "ECGUsedRxSignal" SG_ 381 WaterInFuel 1;
BA_ "U_T6_MCA_MY2020_Rx" SG_ 381 WaterInFuel 1;
BA_ "U_T6_MCA_MY2020_Tx" SG_ 381 GlowIndication 1;
BA_ "U_P702_MY2021_Tx" SG_ 381 GlowIndication 1;
BA_ "U_CD542_MY2021_Tx" SG_ 380 FuelMaintMde_D_Rq 1;
BA_ "U_CX727_MY2021_Tx" SG_ 380 FuelMaintMde_D_Rq 1;
BA_ "U_CD542_MY2021_Rx" SG_ 380 FuelMaintMde_D_Rq 1;
BA_ "U_CX727_MY2021_Rx" SG_ 380 FuelMaintMde_D_Rq 1;
BA_ "U_CD542_MY2021_Tx" SG_ 380 GrdAsstAllw_D_DsplyPt 1;
BA_ "U_CX727_MY2021_Tx" SG_ 380 GrdAsstAllw_D_DsplyPt 1;
BA_ "U_CD542_MY2021_Rx" SG_ 380 GrdAsstAllw_D_DsplyPt 1;
BA_ "U_CX727_MY2021_Rx" SG_ 380 GrdAsstAllw_D_DsplyPt 1;
BA_ "GenSigStartValue" SG_ 380 GrdAsstAllw_D_DsplyPt 1;
BA_ "GenSigStartValueInteger" SG_ 380 GrdAsstAllw_D_DsplyPt 1;
BA_ "U_CX727_MY2021_Tx" SG_ 380 EngOilLvlWarn_D_Rq1 1;
BA_ "U_U55X_MY2022_Tx" SG_ 380 EngOilLvlWarn_D_Rq1 1;
BA_ "U_CD542_MY2021_Tx" SG_ 380 EngOilLvlWarn_D_Rq1 1;
BA_ "U_T6_MCA_MY2020_Tx" SG_ 380 EngOilLvlWarn_D_Rq1 1;
BA_ "U_P702_MY2021_Tx" SG_ 380 EngOilLvlWarn_D_Rq1 1;
BA_ "WakeupSignal" SG_ 380 EngOilLvlWarn_D_Rq1 1;
BA_ "U_T6_MCA_MY2020_Tx" SG_ 380 EngExhBrkOnLamp_B_Rq 1;
BA_ "U_P702_MY2021_Tx" SG_ 380 EngExhBrkOnLamp_B_Rq 1;
BA_ "U_T6_MCA_MY2020_Tx" SG_ 380 EngExhBrkAutoLamp_B_Rq 1;
BA_ "U_P702_MY2021_Tx" SG_ 380 EngExhBrkAutoLamp_B_Rq 1;
BA_ "U_T6_MCA_MY2020_Tx" SG_ 380 EngAout_N_MxAllw 1;
BA_ "U_P702_MY2021_Tx" SG_ 380 EngAout_N_MxAllw 1;
BA_ "U_CD542_MY2021_Tx" SG_ 380 EngAout_N_MxAllw 1;
BA_ "U_CX727_MY2021_Tx" SG_ 380 EngAout_N_MxAllw 1;
BA_ "U_CD542_MY2021_Rx" SG_ 380 EngAout_N_MxAllw 1;
BA_ "U_P702_MY2021_Rx" SG_ 380 EngAout_N_MxAllw 1;
BA_ "U_CX727_MY2021_Rx" SG_ 380 EngAout_N_MxAllw 1;
BA_ "MetaData" SG_ 380 EngAoutIdlRqEc_No_Cs 1;
BA_ "MetaData" SG_ 380 EngAoutIdlRqEc_No_Cnt 1;
BA_ "U_T6_MCA_MY2020_Tx" SG_ 380 EngExhBrkMde_D_Actl 1;
BA_ "U_P702_MY2021_Tx" SG_ 380 EngExhBrkMde_D_Actl 1;
BA_ "U_T6_MCA_MY2020_Rx" SG_ 380 EngExhBrkMde_D_Actl 1;
BA_ "U_P702_MY2021_Rx" SG_ 380 EngExhBrkMde_D_Actl 1;
BA_ "U_P702_MY2021_Rx" SG_ 380 WhlRearDual_D_Stat 1;
BA_ "U_CX727_MY2021_Tx" SG_ 377 HvacAirFullOut_B_Rq 1;
BA_ "U_U55X_MY2022_Tx" SG_ 377 HvacAirFullOut_B_Rq 1;
BA_ "U_CD542_MY2021_Tx" SG_ 377 HvacAirFullOut_B_Rq 1;
BA_ "U_T6_MCA_MY2020_Tx" SG_ 377 HvacAirFullOut_B_Rq 1;
BA_ "U_P702_MY2021_Tx" SG_ 377 HvacAirFullOut_B_Rq 1;
BA_ "U_CX727_MY2021_Tx" SG_ 377 TrnManShif_D_IndDrv 1;
BA_ "U_CD542_MY2021_Tx" SG_ 377 TrnManShif_D_IndDrv 1;
BA_ "U_T6_MCA_MY2020_Tx" SG_ 377 TrnManShif_D_IndDrv 1;
BA_ "U_CD542_MY2021_Tx" SG_ 377 EngAout_Tq_Actl 1;
BA_ "U_CX727_MY2021_Tx" SG_ 377 EngAout_Tq_Actl 1;
BA_ "U_CD542_MY2021_Rx" SG_ 377 EngAout_Tq_Actl 1;
BA_ "U_CX727_MY2021_Rx" SG_ 377 EngAout_Tq_Actl 1;
BA_ "U_CX727_MY2021_Tx" SG_ 377 TrnManShifGear_D_IndDrv 1;
BA_ "U_CD542_MY2021_Tx" SG_ 377 TrnManShifGear_D_IndDrv 1;
BA_ "U_T6_MCA_MY2020_Tx" SG_ 377 TrnManShifGear_D_IndDrv 1;
BA_ "U_CD542_MY2021_Tx" SG_ 377 EngFuelCutFull_B_Inhbt 1;
BA_ "U_CX727_MY2021_Tx" SG_ 377 EngFuelCutFull_B_Inhbt 1;
BA_ "U_CD542_MY2021_Rx" SG_ 377 EngFuelCutFull_B_Inhbt 1;
BA_ "U_CX727_MY2021_Rx" SG_ 377 EngFuelCutFull_B_Inhbt 1;
BA_ "ContentDependant" SG_ 377 EngFuelCutFull_B_Inhbt 1;
BA_ "U_CX727_MY2021_Tx" SG_ 377 FuelFlw_Vl_Dsply 1;
BA_ "U_U55X_MY2022_Tx" SG_ 377 FuelFlw_Vl_Dsply 1;
BA_ "U_CD542_MY2021_Tx" SG_ 377 FuelFlw_Vl_Dsply 1;
BA_ "U_T6_MCA_MY2020_Tx" SG_ 377 FuelFlw_Vl_Dsply 1;
BA_ "U_P702_MY2021_Tx" SG_ 377 FuelFlw_Vl_Dsply 1;
BA_ "ECGUsedRxSignal" SG_ 377 FuelFlw_Vl_Dsply 1;
BA_ "U_T6_MCA_MY2020_Rx" SG_ 377 FuelFlw_Vl_Dsply 1;
BA_ "U_CD542_MY2021_Rx" SG_ 377 FuelFlw_Vl_Dsply 1;
BA_ "U_CX727_MY2021_Rx" SG_ 377 FuelFlw_Vl_Dsply 1;
BA_ "ContentDependant" SG_ 377 FuelFlw_Vl_Dsply 1;
BA_ "U_U55X_MY2022_Tx" SG_ 377 FuelFillInlet_B_Dsply 1;
BA_ "U_CD542_MY2021_Tx" SG_ 377 FuelFillInlet_B_Dsply 1;
BA_ "U_T6_MCA_MY2020_Tx" SG_ 377 FuelFillInlet_B_Dsply 1;
BA_ "U_P702_MY2021_Tx" SG_ 377 FuelFillInlet_B_Dsply 1;
BA_ "ContentDependant" SG_ 377 FuelFillInlet_B_Dsply 1;
BA_ "U_CD542_MY2021_Tx" SG_ 377 EngSrvcRqd_B_Rq 1;
BA_ "U_CX727_MY2021_Tx" SG_ 377 EngSrvcRqd_B_Rq 1;
BA_ "U_U55X_MY2022_Tx" SG_ 377 EngSrvcRqd_B_Rq 1;
BA_ "U_T6_MCA_MY2020_Tx" SG_ 377 EngSrvcRqd_B_Rq 1;
BA_ "U_P702_MY2021_Tx" SG_ 377 EngSrvcRqd_B_Rq 1;
BA_ "ECGUsedRxSignal" SG_ 377 EngSrvcRqd_B_Rq 1;
BA_ "U_T6_MCA_MY2020_Rx" SG_ 377 EngSrvcRqd_B_Rq 1;
BA_ "U_CX727_MY2021_Tx" SG_ 377 OdoCount 1;
BA_ "U_U55X_MY2022_Tx" SG_ 377 OdoCount 1;
BA_ "U_CD542_MY2021_Tx" SG_ 377 OdoCount 1;
BA_ "U_T6_MCA_MY2020_Tx" SG_ 377 OdoCount 1;
BA_ "U_P702_MY2021_Tx" SG_ 377 OdoCount 1;
BA_ "ContentDependant" SG_ 377 OdoCount 1;
BA_ "U_CX727_MY2021_Tx" SG_ 377 EngOilLife_Pc_Actl 1;
BA_ "U_U55X_MY2022_Tx" SG_ 377 EngOilLife_Pc_Actl 1;
BA_ "U_CD542_MY2021_Tx" SG_ 377 EngOilLife_Pc_Actl 1;
BA_ "U_T6_MCA_MY2020_Tx" SG_ 377 EngOilLife_Pc_Actl 1;
BA_ "U_P702_MY2021_Tx" SG_ 377 EngOilLife_Pc_Actl 1;
BA_ "ECGUsedRxSignal" SG_ 377 EngOilLife_Pc_Actl 1;
BA_ "U_T6_MCA_MY2020_Rx" SG_ 377 EngOilLife_Pc_Actl 1;
BA_ "ContentDependant" SG_ 377 EngOilLife_Pc_Actl 1;
BA_ "U_T6_MCA_MY2020_Tx" SG_ 377 TrnKickDown_B_RqDrv 1;
BA_ "ContentDependant" SG_ 377 TrnKickDown_B_RqDrv 1;
BA_ "U_T6_MCA_MY2020_Tx" SG_ 377 FuelFilterLamp_B_Dsply 1;
BA_ "U_P702_MY2021_Tx" SG_ 377 FuelFilterLamp_B_Dsply 1;
BA_ "ECGUsedRxSignal" SG_ 377 FuelFilterLamp_B_Dsply 1;
BA_ "U_T6_MCA_MY2020_Rx" SG_ 377 FuelFilterLamp_B_Dsply 1;
BA_ "U_CX727_MY2021_Tx" SG_ 377 AirCondRec_B_Rq 1;
BA_ "U_U55X_MY2022_Tx" SG_ 377 AirCondRec_B_Rq 1;
BA_ "U_CD542_MY2021_Tx" SG_ 377 AirCondRec_B_Rq 1;
BA_ "U_T6_MCA_MY2020_Tx" SG_ 377 AirCondRec_B_Rq 1;
BA_ "U_P702_MY2021_Tx" SG_ 377 AirCondRec_B_Rq 1;
BA_ "ContentDependant" SG_ 377 AirCondRec_B_Rq 1;
BA_ "U_CX727_MY2021_Tx" SG_ 377 AirCondClutch_B_Stats 1;
BA_ "U_U55X_MY2022_Tx" SG_ 377 AirCondClutch_B_Stats 1;
BA_ "U_CD542_MY2021_Tx" SG_ 377 AirCondClutch_B_Stats 1;
BA_ "U_T6_MCA_MY2020_Tx" SG_ 377 AirCondClutch_B_Stats 1;
BA_ "U_P702_MY2021_Tx" SG_ 377 AirCondClutch_B_Stats 1;
BA_ "ContentDependant" SG_ 377 AirCondClutch_B_Stats 1;
BA_ "U_CD542_MY2021_Tx" SG_ 377 EngAoutTqActl_D_Qf 1;
BA_ "U_CX727_MY2021_Tx" SG_ 377 EngAoutTqActl_D_Qf 1;
BA_ "U_CD542_MY2021_Rx" SG_ 377 EngAoutTqActl_D_Qf 1;
BA_ "U_CX727_MY2021_Rx" SG_ 377 EngAoutTqActl_D_Qf 1;
BA_ "MetaData" SG_ 377 EngAoutTqActl_D_Qf 1;
BA_ "U_CX727_MY2021_Tx" SG_ 376 GasPrtc_D_RqDsply 1;
BA_ "U_U55X_MY2022_Tx" SG_ 376 GasPrtc_D_RqDsply 1;
BA_ "U_CD542_MY2021_Tx" SG_ 376 GasPrtc_D_RqDsply 1;
BA_ "U_T6_MCA_MY2020_Tx" SG_ 376 GasPrtc_D_RqDsply 1;
BA_ "U_P702_MY2021_Tx" SG_ 376 GasPrtc_D_RqDsply 1;
BA_ "U_T6_MCA_MY2020_Tx" SG_ 376 LnchCtlSys_D_Stat 1;
BA_ "U_CD542_MY2021_Rx" SG_ 376 LnchCtlSys_D_Stat 1;
BA_ "U_T6_MCA_MY2020_Rx" SG_ 376 LnchCtlSys_D_Stat 1;
BA_ "U_CX727_MY2021_Tx" SG_ 376 EngAout_Aa_Actl 1;
BA_ "U_U55X_MY2022_Tx" SG_ 376 EngAout_Aa_Actl 1;
BA_ "U_CD542_MY2021_Tx" SG_ 376 EngAout_Aa_Actl 1;
BA_ "U_T6_MCA_MY2020_Tx" SG_ 376 EngAout_Aa_Actl 1;
BA_ "U_P702_MY2021_Tx" SG_ 376 EngAout_Aa_Actl 1;
BA_ "U_U55X_MY2022_Rx" SG_ 376 EngAout_Aa_Actl 1;
BA_ "U_CD542_MY2021_Rx" SG_ 376 EngAout_Aa_Actl 1;
BA_ "U_T6_MCA_MY2020_Rx" SG_ 376 EngAout_Aa_Actl 1;
BA_ "U_P702_MY2021_Rx" SG_ 376 EngAout_Aa_Actl 1;
BA_ "U_CX727_MY2021_Rx" SG_ 376 EngAout_Aa_Actl 1;
BA_ "ContentDependant" SG_ 376 EngAout_Aa_Actl 1;
BA_ "U_CX727_MY2021_Tx" SG_ 376 DynoMde_B_Cmd 1;
BA_ "U_U55X_MY2022_Tx" SG_ 376 DynoMde_B_Cmd 1;
BA_ "U_CD542_MY2021_Tx" SG_ 376 DynoMde_B_Cmd 1;
BA_ "U_T6_MCA_MY2020_Tx" SG_ 376 DynoMde_B_Cmd 1;
BA_ "U_P702_MY2021_Tx" SG_ 376 DynoMde_B_Cmd 1;
BA_ "U_U55X_MY2022_Rx" SG_ 376 DynoMde_B_Cmd 1;
BA_ "U_CD542_MY2021_Rx" SG_ 376 DynoMde_B_Cmd 1;
BA_ "U_T6_MCA_MY2020_Rx" SG_ 376 DynoMde_B_Cmd 1;
BA_ "U_P702_MY2021_Rx" SG_ 376 DynoMde_B_Cmd 1;
BA_ "U_CX727_MY2021_Rx" SG_ 376 DynoMde_B_Cmd 1;
BA_ "U_CX727_MY2021_Tx" SG_ 376 AslChime_B_Rq 1;
BA_ "U_CD542_MY2021_Tx" SG_ 376 AslChime_B_Rq 1;
BA_ "U_T6_MCA_MY2020_Tx" SG_ 376 AslChime_B_Rq 1;
BA_ "U_P702_MY2021_Tx" SG_ 376 AslChime_B_Rq 1;
BA_ "U_CD542_MY2021_Tx" SG_ 376 HvacHtrCore2_Te_Actl 1;
BA_ "U_CX727_MY2021_Tx" SG_ 376 HvacHtrCore2_Te_Actl 1;
BA_ "U_P702_MY2021_Tx" SG_ 376 HvacHtrCore2_Te_Actl 1;
BA_ "U_CD542_MY2021_Rx" SG_ 376 HvacHtrCore2_Te_Actl 1;
BA_ "U_P702_MY2021_Rx" SG_ 376 HvacHtrCore2_Te_Actl 1;
BA_ "U_CX727_MY2021_Rx" SG_ 376 HvacHtrCore2_Te_Actl 1;
BA_ "GenSigStartValueInteger" SG_ 376 HvacHtrCore2_Te_Actl 200;
BA_ "U_CD542_MY2021_Tx" SG_ 376 PtcHtr_D_Cmd 1;
BA_ "U_CX727_MY2021_Tx" SG_ 376 PtcHtr_D_Cmd 1;
BA_ "U_CD542_MY2021_Rx" SG_ 376 PtcHtr_D_Cmd 1;
BA_ "U_CX727_MY2021_Rx" SG_ 376 PtcHtr_D_Cmd 1;
BA_ "U_T6_MCA_MY2020_Tx" SG_ 376 EcssLamp_D_RqDsply 1;
BA_ "U_P702_MY2021_Tx" SG_ 376 EcssLamp_D_RqDsply 1;
BA_ "U_CX727_MY2021_Tx" SG_ 376 AirAmbTe_D_Qf 1;
BA_ "U_U55X_MY2022_Tx" SG_ 376 AirAmbTe_D_Qf 1;
BA_ "U_CD542_MY2021_Tx" SG_ 376 AirAmbTe_D_Qf 1;
BA_ "U_T6_MCA_MY2020_Tx" SG_ 376 AirAmbTe_D_Qf 1;
BA_ "U_P702_MY2021_Tx" SG_ 376 AirAmbTe_D_Qf 1;
BA_ "U_U55X_MY2022_Rx" SG_ 376 AirAmbTe_D_Qf 1;
BA_ "U_T6_MCA_MY2020_Rx" SG_ 376 AirAmbTe_D_Qf 1;
BA_ "U_CD542_MY2021_Rx" SG_ 376 AirAmbTe_D_Qf 1;
BA_ "U_P702_MY2021_Rx" SG_ 376 AirAmbTe_D_Qf 1;
BA_ "U_CX727_MY2021_Rx" SG_ 376 AirAmbTe_D_Qf 1;
BA_ "GenSigStartValue" SG_ 376 AirAmbTe_D_Qf 1;
BA_ "MetaData" SG_ 376 AirAmbTe_D_Qf 1;
BA_ "GenSigStartValueInteger" SG_ 376 AirAmbTe_D_Qf 1;
BA_ "U_CX727_MY2021_Tx" SG_ 376 AirAmb_Te_ActlFilt 1;
BA_ "U_U55X_MY2022_Tx" SG_ 376 AirAmb_Te_ActlFilt 1;
BA_ "U_CD542_MY2021_Tx" SG_ 376 AirAmb_Te_ActlFilt 1;
BA_ "U_T6_MCA_MY2020_Tx" SG_ 376 AirAmb_Te_ActlFilt 1;
BA_ "U_P702_MY2021_Tx" SG_ 376 AirAmb_Te_ActlFilt 1;
BA_ "ECGUsedRxSignal" SG_ 376 AirAmb_Te_ActlFilt 1;
BA_ "U_T6_MCA_MY2020_Rx" SG_ 376 AirAmb_Te_ActlFilt 1;
BA_ "U_CD542_MY2021_Rx" SG_ 376 AirAmb_Te_ActlFilt 1;
BA_ "U_P702_MY2021_Rx" SG_ 376 AirAmb_Te_ActlFilt 1;
BA_ "U_CX727_MY2021_Rx" SG_ 376 AirAmb_Te_ActlFilt 1;
BA_ "GenSigStartValueInteger" SG_ 376 AirAmb_Te_ActlFilt 512;
BA_ "U_CX727_MY2021_Tx" SG_ 376 AirAmb_P_Actl 1;
BA_ "U_U55X_MY2022_Tx" SG_ 376 AirAmb_P_Actl 1;
BA_ "U_CD542_MY2021_Tx" SG_ 376 AirAmb_P_Actl 1;
BA_ "U_T6_MCA_MY2020_Tx" SG_ 376 AirAmb_P_Actl 1;
BA_ "U_P702_MY2021_Tx" SG_ 376 AirAmb_P_Actl 1;
BA_ "U_U55X_MY2022_Rx" SG_ 376 AirAmb_P_Actl 1;
BA_ "U_CD542_MY2021_Rx" SG_ 376 AirAmb_P_Actl 1;
BA_ "U_T6_MCA_MY2020_Rx" SG_ 376 AirAmb_P_Actl 1;
BA_ "U_P702_MY2021_Rx" SG_ 376 AirAmb_P_Actl 1;
BA_ "U_CX727_MY2021_Rx" SG_ 376 AirAmb_P_Actl 1;
BA_ "U_CX727_MY2021_Tx" SG_ 376 AslIconDsply_D_Rq 1;
BA_ "U_CD542_MY2021_Tx" SG_ 376 AslIconDsply_D_Rq 1;
BA_ "U_T6_MCA_MY2020_Tx" SG_ 376 AslIconDsply_D_Rq 1;
BA_ "U_P702_MY2021_Tx" SG_ 376 AslIconDsply_D_Rq 1;
BA_ "U_CX727_MY2021_Tx" SG_ 376 AirAmb_Te_Actl 1;
BA_ "U_U55X_MY2022_Tx" SG_ 376 AirAmb_Te_Actl 1;
BA_ "U_CD542_MY2021_Tx" SG_ 376 AirAmb_Te_Actl 1;
BA_ "U_T6_MCA_MY2020_Tx" SG_ 376 AirAmb_Te_Actl 1;
BA_ "U_P702_MY2021_Tx" SG_ 376 AirAmb_Te_Actl 1;
BA_ "U_U55X_MY2022_Rx" SG_ 376 AirAmb_Te_Actl 1;
BA_ "U_CD542_MY2021_Rx" SG_ 376 AirAmb_Te_Actl 1;
BA_ "U_T6_MCA_MY2020_Rx" SG_ 376 AirAmb_Te_Actl 1;
BA_ "U_P702_MY2021_Rx" SG_ 376 AirAmb_Te_Actl 1;
BA_ "U_CX727_MY2021_Rx" SG_ 376 AirAmb_Te_Actl 1;
BA_ "GenSigStartValueInteger" SG_ 376 AirAmb_Te_Actl 512;
BA_ "U_T6_MCA_MY2020_Tx" SG_ 373 DieslPrtc2_D_RqDsply 1;
BA_ "U_P702_MY2021_Tx" SG_ 373 DieslPrtc2_D_RqDsply 1;
BA_ "ECGUsedRxSignal" SG_ 373 DieslPrtc2_D_RqDsply 1;
BA_ "U_T6_MCA_MY2020_Rx" SG_ 373 DieslPrtc2_D_RqDsply 1;
BA_ "U_T6_MCA_MY2020_Tx" SG_ 373 DieslPrtcRgen_D_Actl 1;
BA_ "U_P702_MY2021_Tx" SG_ 373 DieslPrtcRgen_D_Actl 1;
BA_ "U_T6_MCA_MY2020_Rx" SG_ 373 DieslPrtcRgen_D_Actl 1;
BA_ "U_P702_MY2021_Rx" SG_ 373 DieslPrtcRgen_D_Actl 1;
BA_ "U_CD542_MY2021_Tx" SG_ 373 EngFuelCutFull_B_Allw 1;
BA_ "U_CX727_MY2021_Tx" SG_ 373 EngFuelCutFull_B_Allw 1;
BA_ "U_CD542_MY2021_Rx" SG_ 373 EngFuelCutFull_B_Allw 1;
BA_ "U_CX727_MY2021_Rx" SG_ 373 EngFuelCutFull_B_Allw 1;
BA_ "ContentDependant" SG_ 373 EngFuelCutFull_B_Allw 1;
BA_ "U_T6_MCA_MY2020_Tx" SG_ 373 EngTeColdPrtct_D_Stats 1;
BA_ "U_P702_MY2021_Tx" SG_ 373 EngTeColdPrtct_D_Stats 1;
BA_ "U_T6_MCA_MY2020_Tx" SG_ 373 EngExhOvrTe_B_RqDsply 1;
BA_ "U_P702_MY2021_Tx" SG_ 373 EngExhOvrTe_B_RqDsply 1;
BA_ "ECGUsedRxSignal" SG_ 373 EngExhOvrTe_B_RqDsply 1;
BA_ "U_T6_MCA_MY2020_Rx" SG_ 373 EngExhOvrTe_B_RqDsply 1;
BA_ "U_CD542_MY2021_Tx" SG_ 373 EngAout_Tq_MxActlN 1;
BA_ "ContentDependant" SG_ 373 EngAout_Tq_MxActlN 1;
BA_ "U_P702_MY2021_Tx" SG_ 359 PrplWhlRgenMn_Tq_Actl 1;
BA_ "U_CD542_MY2021_Tx" SG_ 359 PrplWhlRgenMn_Tq_Actl 1;
BA_ "U_CX727_MY2021_Tx" SG_ 359 PrplWhlRgenMn_Tq_Actl 1;
BA_ "U_CD542_MY2021_Rx" SG_ 359 PrplWhlRgenMn_Tq_Actl 1;
BA_ "U_P702_MY2021_Rx" SG_ 359 PrplWhlRgenMn_Tq_Actl 1;
BA_ "U_CX727_MY2021_Rx" SG_ 359 PrplWhlRgenMn_Tq_Actl 1;
BA_ "GenSigStartValueInteger" SG_ 359 PrplWhlRgenMn_Tq_Actl 4095;
BA_ "U_U55X_MY2022_Tx" SG_ 359 ElPw_D_StatStrtStop 1;
BA_ "U_T6_MCA_MY2020_Tx" SG_ 359 ElPw_D_StatStrtStop 1;
BA_ "U_P702_MY2021_Tx" SG_ 359 ElPw_D_StatStrtStop 1;
BA_ "U_CD542_MY2021_Tx" SG_ 359 ElPw_D_StatStrtStop 1;
BA_ "U_CX727_MY2021_Tx" SG_ 359 ElPw_D_StatStrtStop 1;
BA_ "U_U55X_MY2022_Rx" SG_ 359 ElPw_D_StatStrtStop 1;
BA_ "U_CD542_MY2021_Rx" SG_ 359 ElPw_D_StatStrtStop 1;
BA_ "U_T6_MCA_MY2020_Rx" SG_ 359 ElPw_D_StatStrtStop 1;
BA_ "U_P702_MY2021_Rx" SG_ 359 ElPw_D_StatStrtStop 1;
BA_ "U_U55X_MY2022_Tx" SG_ 359 TrnAin_Tq_Actl 1;
BA_ "U_T6_MCA_MY2020_Tx" SG_ 359 TrnAin_Tq_Actl 1;
BA_ "U_P702_MY2021_Tx" SG_ 359 TrnAin_Tq_Actl 1;
BA_ "U_CD542_MY2021_Tx" SG_ 359 TrnAin_Tq_Actl 1;
BA_ "U_CX727_MY2021_Tx" SG_ 359 TrnAin_Tq_Actl 1;
BA_ "U_U55X_MY2022_Rx" SG_ 359 TrnAin_Tq_Actl 1;
BA_ "U_CD542_MY2021_Rx" SG_ 359 TrnAin_Tq_Actl 1;
BA_ "U_T6_MCA_MY2020_Rx" SG_ 359 TrnAin_Tq_Actl 1;
BA_ "U_P702_MY2021_Rx" SG_ 359 TrnAin_Tq_Actl 1;
BA_ "U_CX727_MY2021_Rx" SG_ 359 TrnAin_Tq_Actl 1;
BA_ "ContentDependant" SG_ 359 TrnAin_Tq_Actl 1;
BA_ "U_U55X_MY2022_Tx" SG_ 359 PrplWhlTot2_Tq_Actl 1;
BA_ "U_T6_MCA_MY2020_Tx" SG_ 359 PrplWhlTot2_Tq_Actl 1;
BA_ "U_P702_MY2021_Tx" SG_ 359 PrplWhlTot2_Tq_Actl 1;
BA_ "U_CD542_MY2021_Tx" SG_ 359 PrplWhlTot2_Tq_Actl 1;
BA_ "U_CX727_MY2021_Tx" SG_ 359 PrplWhlTot2_Tq_Actl 1;
BA_ "ECGUsedRxSignal" SG_ 359 PrplWhlTot2_Tq_Actl 1;
BA_ "U_U55X_MY2022_Rx" SG_ 359 PrplWhlTot2_Tq_Actl 1;
BA_ "U_CD542_MY2021_Rx" SG_ 359 PrplWhlTot2_Tq_Actl 1;
BA_ "U_T6_MCA_MY2020_Rx" SG_ 359 PrplWhlTot2_Tq_Actl 1;
BA_ "U_CX727_MY2021_Rx" SG_ 359 PrplWhlTot2_Tq_Actl 1;
BA_ "U_P702_MY2021_Rx" SG_ 359 PrplWhlTot2_Tq_Actl 1;
BA_ "U_CD542_MY2021_Tx" SG_ 359 LscmbbDeny_B_ActlPrpl 1;
BA_ "U_CX727_MY2021_Tx" SG_ 359 LscmbbDeny_B_ActlPrpl 1;
BA_ "U_CD542_MY2021_Tx" SG_ 359 LscmbbEngTqMn_B_Actl 1;
BA_ "U_CX727_MY2021_Tx" SG_ 359 LscmbbEngTqMn_B_Actl 1;
BA_ "U_U55X_MY2022_Tx" SG_ 359 PwPckTq_D_Stat 1;
BA_ "U_T6_MCA_MY2020_Tx" SG_ 359 PwPckTq_D_Stat 1;
BA_ "U_P702_MY2021_Tx" SG_ 359 PwPckTq_D_Stat 1;
BA_ "U_CD542_MY2021_Tx" SG_ 359 PwPckTq_D_Stat 1;
BA_ "U_CX727_MY2021_Tx" SG_ 359 PwPckTq_D_Stat 1;
BA_ "ECGUsedRxSignal" SG_ 359 PwPckTq_D_Stat 1;
BA_ "U_U55X_MY2022_Rx" SG_ 359 PwPckTq_D_Stat 1;
BA_ "U_CD542_MY2021_Rx" SG_ 359 PwPckTq_D_Stat 1;
BA_ "U_CX727_MY2021_Rx" SG_ 359 PwPckTq_D_Stat 1;
BA_ "U_P702_MY2021_Rx" SG_ 359 PwPckTq_D_Stat 1;
BA_ "U_T6_MCA_MY2020_Rx" SG_ 359 PwPckTq_D_Stat 1;
BA_ "U_U55X_MY2022_Tx" SG_ 359 Eng_D_Stat 1;
BA_ "U_T6_MCA_MY2020_Tx" SG_ 359 Eng_D_Stat 1;
BA_ "U_P702_MY2021_Tx" SG_ 359 Eng_D_Stat 1;
BA_ "U_CD542_MY2021_Tx" SG_ 359 Eng_D_Stat 1;
BA_ "U_CX727_MY2021_Tx" SG_ 359 Eng_D_Stat 1;
BA_ "ECGUsedRxSignal" SG_ 359 Eng_D_Stat 1;
BA_ "U_U55X_MY2022_Rx" SG_ 359 Eng_D_Stat 1;
BA_ "U_CD542_MY2021_Rx" SG_ 359 Eng_D_Stat 1;
BA_ "U_T6_MCA_MY2020_Rx" SG_ 359 Eng_D_Stat 1;
BA_ "U_P702_MY2021_Rx" SG_ 359 Eng_D_Stat 1;
BA_ "U_CX727_MY2021_Rx" SG_ 359 Eng_D_Stat 1;
BA_ "U_CD542_MY2021_Tx" SG_ 359 PlgActvArb_B_Actl 1;
BA_ "U_CX727_MY2021_Tx" SG_ 359 PlgActvArb_B_Actl 1;
BA_ "ECGUsedRxSignal" SG_ 359 PlgActvArb_B_Actl 1;
BA_ "U_T6_MCA_MY2020_Rx" SG_ 359 PlgActvArb_B_Actl 1;
BA_ "U_CD542_MY2021_Rx" SG_ 359 PlgActvArb_B_Actl 1;
BA_ "GenSigStartValue" SG_ 359 PlgActvArb_B_Actl 1;
BA_ "ContentDependant" SG_ 359 PlgActvArb_B_Actl 1;
BA_ "GenSigStartValueInteger" SG_ 359 PlgActvArb_B_Actl 1;
BA_ "U_U55X_MY2022_Tx" SG_ 359 ElPw_D_Stat 1;
BA_ "U_T6_MCA_MY2020_Tx" SG_ 359 ElPw_D_Stat 1;
BA_ "U_P702_MY2021_Tx" SG_ 359 ElPw_D_Stat 1;
BA_ "U_CD542_MY2021_Tx" SG_ 359 ElPw_D_Stat 1;
BA_ "U_CX727_MY2021_Tx" SG_ 359 ElPw_D_Stat 1;
BA_ "U_U55X_MY2022_Rx" SG_ 359 ElPw_D_Stat 1;
BA_ "U_CX727_MY2021_Rx" SG_ 359 ElPw_D_Stat 1;
BA_ "U_CD542_MY2021_Rx" SG_ 359 ElPw_D_Stat 1;
BA_ "U_P702_MY2021_Rx" SG_ 359 ElPw_D_Stat 1;
BA_ "U_T6_MCA_MY2020_Rx" SG_ 359 ElPw_D_Stat 1;
BA_ "U_U55X_MY2022_Tx" SG_ 359 TrnAinTq_D_Qf 1;
BA_ "U_T6_MCA_MY2020_Tx" SG_ 359 TrnAinTq_D_Qf 1;
BA_ "U_P702_MY2021_Tx" SG_ 359 TrnAinTq_D_Qf 1;
BA_ "U_CD542_MY2021_Tx" SG_ 359 TrnAinTq_D_Qf 1;
BA_ "U_CX727_MY2021_Tx" SG_ 359 TrnAinTq_D_Qf 1;
BA_ "U_U55X_MY2022_Rx" SG_ 359 TrnAinTq_D_Qf 1;
BA_ "U_CD542_MY2021_Rx" SG_ 359 TrnAinTq_D_Qf 1;
BA_ "U_T6_MCA_MY2020_Rx" SG_ 359 TrnAinTq_D_Qf 1;
BA_ "U_P702_MY2021_Rx" SG_ 359 TrnAinTq_D_Qf 1;
BA_ "U_CX727_MY2021_Rx" SG_ 359 TrnAinTq_D_Qf 1;
BA_ "MetaData" SG_ 359 TrnAinTq_D_Qf 1;
BA_ "ContentDependant" SG_ 359 TrnAinTq_D_Qf 1;
BA_ "U_U55X_MY2022_Tx" SG_ 358 StopStrtStdby_D_Indic 1;
BA_ "U_CD542_MY2021_Tx" SG_ 358 StopStrtStdby_D_Indic 1;
BA_ "U_T6_MCA_MY2020_Tx" SG_ 358 StopStrtStdby_D_Indic 1;
BA_ "U_P702_MY2021_Tx" SG_ 358 StopStrtStdby_D_Indic 1;
BA_ "U_U55X_MY2022_Tx" SG_ 358 StopStrtIODTxt_D_Rq 1;
BA_ "U_CD542_MY2021_Tx" SG_ 358 StopStrtIODTxt_D_Rq 1;
BA_ "U_T6_MCA_MY2020_Tx" SG_ 358 StopStrtIODTxt_D_Rq 1;
BA_ "U_P702_MY2021_Tx" SG_ 358 StopStrtIODTxt_D_Rq 1;
BA_ "U_U55X_MY2022_Tx" SG_ 358 StopStrtDrvMde_D_Indic 1;
BA_ "U_CD542_MY2021_Tx" SG_ 358 StopStrtDrvMde_D_Indic 1;
BA_ "U_T6_MCA_MY2020_Tx" SG_ 358 StopStrtDrvMde_D_Indic 1;
BA_ "U_P702_MY2021_Tx" SG_ 358 StopStrtDrvMde_D_Indic 1;
BA_ "U_U55X_MY2022_Tx" SG_ 358 StopStrtMsgTxt_D_Rq 1;
BA_ "U_CD542_MY2021_Tx" SG_ 358 StopStrtMsgTxt_D_Rq 1;
BA_ "U_T6_MCA_MY2020_Tx" SG_ 358 StopStrtMsgTxt_D_Rq 1;
BA_ "U_P702_MY2021_Tx" SG_ 358 StopStrtMsgTxt_D_Rq 1;
BA_ "U_CX727_MY2021_Tx" SG_ 358 OdoTripVerify_L_Actl 1;
BA_ "U_U55X_MY2022_Tx" SG_ 358 OdoTripVerify_L_Actl 1;
BA_ "U_CD542_MY2021_Tx" SG_ 358 OdoTripVerify_L_Actl 1;
BA_ "U_T6_MCA_MY2020_Tx" SG_ 358 OdoTripVerify_L_Actl 1;
BA_ "U_P702_MY2021_Tx" SG_ 358 OdoTripVerify_L_Actl 1;
BA_ "U_U55X_MY2022_Tx" SG_ 358 HiElPwInhbt_B_Stat 1;
BA_ "U_CD542_MY2021_Tx" SG_ 358 HiElPwInhbt_B_Stat 1;
BA_ "U_T6_MCA_MY2020_Tx" SG_ 358 HiElPwInhbt_B_Stat 1;
BA_ "U_P702_MY2021_Tx" SG_ 358 HiElPwInhbt_B_Stat 1;
BA_ "ContentDependant" SG_ 358 HiElPwInhbt_B_Stat 1;
BA_ "U_U55X_MY2022_Tx" SG_ 358 AutoStopPtDelta_I_Est 1;
BA_ "U_CD542_MY2021_Tx" SG_ 358 AutoStopPtDelta_I_Est 1;
BA_ "U_T6_MCA_MY2020_Tx" SG_ 358 AutoStopPtDelta_I_Est 1;
BA_ "U_P702_MY2021_Tx" SG_ 358 AutoStopPtDelta_I_Est 1;
BA_ "ContentDependant" SG_ 358 AutoStopPtDelta_I_Est 1;
BA_ "GenSigStartValueInteger" SG_ 358 AutoStopPtDelta_I_Est 127;
BA_ "U_U55X_MY2022_Tx" SG_ 357 BPedDrvAppl_D_QF 1;
BA_ "U_T6_MCA_MY2020_Tx" SG_ 357 BPedDrvAppl_D_QF 1;
BA_ "U_P702_MY2021_Tx" SG_ 357 BPedDrvAppl_D_QF 1;
BA_ "U_CD542_MY2021_Tx" SG_ 357 BPedDrvAppl_D_QF 1;
BA_ "U_CX727_MY2021_Tx" SG_ 357 BPedDrvAppl_D_QF 1;
BA_ "U_U55X_MY2022_Rx" SG_ 357 BPedDrvAppl_D_QF 1;
BA_ "U_T6_MCA_MY2020_Rx" SG_ 357 BPedDrvAppl_D_QF 1;
BA_ "U_CD542_MY2021_Rx" SG_ 357 BPedDrvAppl_D_QF 1;
BA_ "U_P702_MY2021_Rx" SG_ 357 BPedDrvAppl_D_QF 1;
BA_ "U_CX727_MY2021_Rx" SG_ 357 BPedDrvAppl_D_QF 1;
BA_ "GenSigStartValue" SG_ 357 BPedDrvAppl_D_QF 1;
BA_ "MetaData" SG_ 357 BPedDrvAppl_D_QF 1;
BA_ "GenSigStartValueInteger" SG_ 357 BPedDrvAppl_D_QF 1;
BA_ "U_U55X_MY2022_Tx" SG_ 357 CmbbDeny_B_ActlPrpl 1;
BA_ "U_T6_MCA_MY2020_Tx" SG_ 357 CmbbDeny_B_ActlPrpl 1;
BA_ "U_P702_MY2021_Tx" SG_ 357 CmbbDeny_B_ActlPrpl 1;
BA_ "U_CD542_MY2021_Tx" SG_ 357 CmbbDeny_B_ActlPrpl 1;
BA_ "U_CX727_MY2021_Tx" SG_ 357 CmbbDeny_B_ActlPrpl 1;
BA_ "U_CD542_MY2021_Rx" SG_ 357 CmbbDeny_B_ActlPrpl 1;
BA_ "U_T6_MCA_MY2020_Rx" SG_ 357 CmbbDeny_B_ActlPrpl 1;
BA_ "MetaData" SG_ 357 BpedDrvAppl_No_Cs 1;
BA_ "U_CX727_MY2021_Tx" SG_ 357 PrplTqMnSat_B_Actl 1;
BA_ "U_CD542_MY2021_Tx" SG_ 357 PrplTqMnSat_B_Actl 1;
BA_ "U_T6_MCA_MY2020_Tx" SG_ 357 PrplTqMnSat_B_Actl 1;
BA_ "U_P702_MY2021_Tx" SG_ 357 PrplTqMnSat_B_Actl 1;
BA_ "U_CD542_MY2021_Rx" SG_ 357 PrplTqMnSat_B_Actl 1;
BA_ "U_T6_MCA_MY2020_Rx" SG_ 357 PrplTqMnSat_B_Actl 1;
BA_ "U_CD542_MY2021_Tx" SG_ 357 VehStrtStop_D_Rq 1;
BA_ "U_CX727_MY2021_Tx" SG_ 357 VehStrtStop_D_Rq 1;
BA_ "U_CD542_MY2021_Rx" SG_ 357 VehStrtStop_D_Rq 1;
BA_ "U_CX727_MY2021_Rx" SG_ 357 VehStrtStop_D_Rq 1;
BA_ "U_U55X_MY2022_Tx" SG_ 357 BpedDrvAppl_No_Cnt 1;
BA_ "MetaData" SG_ 357 BpedDrvAppl_No_Cnt 1;
BA_ "U_CX727_MY2021_Tx" SG_ 357 BpedDrvAppl_D_Actl 1;
BA_ "U_U55X_MY2022_Tx" SG_ 357 BpedDrvAppl_D_Actl 1;
BA_ "U_CD542_MY2021_Tx" SG_ 357 BpedDrvAppl_D_Actl 1;
BA_ "U_T6_MCA_MY2020_Tx" SG_ 357 BpedDrvAppl_D_Actl 1;
BA_ "U_P702_MY2021_Tx" SG_ 357 BpedDrvAppl_D_Actl 1;
BA_ "ECGUsedRxSignal" SG_ 357 BpedDrvAppl_D_Actl 1;
BA_ "U_U55X_MY2022_Rx" SG_ 357 BpedDrvAppl_D_Actl 1;
BA_ "U_T6_MCA_MY2020_Rx" SG_ 357 BpedDrvAppl_D_Actl 1;
BA_ "U_CD542_MY2021_Rx" SG_ 357 BpedDrvAppl_D_Actl 1;
BA_ "U_P702_MY2021_Rx" SG_ 357 BpedDrvAppl_D_Actl 1;
BA_ "U_CX727_MY2021_Rx" SG_ 357 BpedDrvAppl_D_Actl 1;
BA_ "GenSigStartValue" SG_ 357 BpedDrvAppl_D_Actl 1;
BA_ "GenSigStartValueInteger" SG_ 357 BpedDrvAppl_D_Actl 1;
BA_ "U_CX727_MY2021_Tx" SG_ 357 CmbbEngTqMn_B_Actl 1;
BA_ "U_U55X_MY2022_Tx" SG_ 357 CmbbEngTqMn_B_Actl 1;
BA_ "U_CD542_MY2021_Tx" SG_ 357 CmbbEngTqMn_B_Actl 1;
BA_ "U_T6_MCA_MY2020_Tx" SG_ 357 CmbbEngTqMn_B_Actl 1;
BA_ "U_P702_MY2021_Tx" SG_ 357 CmbbEngTqMn_B_Actl 1;
BA_ "U_CD542_MY2021_Rx" SG_ 357 CmbbEngTqMn_B_Actl 1;
BA_ "U_T6_MCA_MY2020_Rx" SG_ 357 CmbbEngTqMn_B_Actl 1;
BA_ "U_CX727_MY2021_Tx" SG_ 357 Veh_V_DsplyCcSet 1;
BA_ "U_U55X_MY2022_Tx" SG_ 357 Veh_V_DsplyCcSet 1;
BA_ "U_CD542_MY2021_Tx" SG_ 357 Veh_V_DsplyCcSet 1;
BA_ "U_T6_MCA_MY2020_Tx" SG_ 357 Veh_V_DsplyCcSet 1;
BA_ "U_P702_MY2021_Tx" SG_ 357 Veh_V_DsplyCcSet 1;
BA_ "U_CD542_MY2021_Rx" SG_ 357 Veh_V_DsplyCcSet 1;
BA_ "U_T6_MCA_MY2020_Rx" SG_ 357 Veh_V_DsplyCcSet 1;
BA_ "U_CX727_MY2021_Tx" SG_ 357 AccEngStat_D_Actl 1;
BA_ "U_U55X_MY2022_Tx" SG_ 357 AccEngStat_D_Actl 1;
BA_ "U_CD542_MY2021_Tx" SG_ 357 AccEngStat_D_Actl 1;
BA_ "U_T6_MCA_MY2020_Tx" SG_ 357 AccEngStat_D_Actl 1;
BA_ "U_P702_MY2021_Tx" SG_ 357 AccEngStat_D_Actl 1;
BA_ "U_CD542_MY2021_Rx" SG_ 357 AccEngStat_D_Actl 1;
BA_ "U_T6_MCA_MY2020_Rx" SG_ 357 AccEngStat_D_Actl 1;
BA_ "U_CX727_MY2021_Tx" SG_ 357 CcMde_D_Actl 1;
BA_ "U_U55X_MY2022_Tx" SG_ 357 CcMde_D_Actl 1;
BA_ "U_CD542_MY2021_Tx" SG_ 357 CcMde_D_Actl 1;
BA_ "U_T6_MCA_MY2020_Tx" SG_ 357 CcMde_D_Actl 1;
BA_ "U_P702_MY2021_Tx" SG_ 357 CcMde_D_Actl 1;
BA_ "U_U55X_MY2022_Rx" SG_ 357 CcMde_D_Actl 1;
BA_ "U_T6_MCA_MY2020_Rx" SG_ 357 CcMde_D_Actl 1;
BA_ "U_P702_MY2021_Rx" SG_ 357 CcMde_D_Actl 1;
BA_ "U_CX727_MY2021_Rx" SG_ 357 CcMde_D_Actl 1;
BA_ "U_CX727_MY2021_Tx" SG_ 357 CcStat_D_Actl 1;
BA_ "U_U55X_MY2022_Tx" SG_ 357 CcStat_D_Actl 1;
BA_ "U_CD542_MY2021_Tx" SG_ 357 CcStat_D_Actl 1;
BA_ "U_T6_MCA_MY2020_Tx" SG_ 357 CcStat_D_Actl 1;
BA_ "U_P702_MY2021_Tx" SG_ 357 CcStat_D_Actl 1;
BA_ "U_U55X_MY2022_Rx" SG_ 357 CcStat_D_Actl 1;
BA_ "U_T6_MCA_MY2020_Rx" SG_ 357 CcStat_D_Actl 1;
BA_ "U_CD542_MY2021_Rx" SG_ 357 CcStat_D_Actl 1;
BA_ "U_P702_MY2021_Rx" SG_ 357 CcStat_D_Actl 1;
BA_ "U_CX727_MY2021_Rx" SG_ 357 CcStat_D_Actl 1;
BA_ "U_CD542_MY2021_Tx" SG_ 357 EngAout_N_MnAllw 1;
BA_ "U_CX727_MY2021_Tx" SG_ 357 EngAout_N_MnAllw 1;
BA_ "U_P702_MY2021_Tx" SG_ 357 EngAout_N_MnAllw 1;
BA_ "U_CD542_MY2021_Rx" SG_ 357 EngAout_N_MnAllw 1;
BA_ "U_P702_MY2021_Rx" SG_ 357 EngAout_N_MnAllw 1;
BA_ "U_CX727_MY2021_Rx" SG_ 357 EngAout_N_MnAllw 1;
BA_ "U_CX727_MY2021_Tx" SG_ 357 CcOvrrdActv_B_Actl 1;
BA_ "U_U55X_MY2022_Tx" SG_ 357 CcOvrrdActv_B_Actl 1;
BA_ "U_CD542_MY2021_Tx" SG_ 357 CcOvrrdActv_B_Actl 1;
BA_ "U_T6_MCA_MY2020_Tx" SG_ 357 CcOvrrdActv_B_Actl 1;
BA_ "U_P702_MY2021_Tx" SG_ 357 CcOvrrdActv_B_Actl 1;
BA_ "U_U55X_MY2022_Rx" SG_ 357 CcOvrrdActv_B_Actl 1;
BA_ "U_CD542_MY2021_Rx" SG_ 357 CcOvrrdActv_B_Actl 1;
BA_ "U_CX727_MY2021_Rx" SG_ 357 CcOvrrdActv_B_Actl 1;
BA_ "U_T6_MCA_MY2020_Rx" SG_ 357 CcOvrrdActv_B_Actl 1;
BA_ "U_P702_MY2021_Rx" SG_ 357 CcOvrrdActv_B_Actl 1;
BA_ "U_CX727_MY2021_Tx" SG_ 357 AccStopMde_D_Rq 1;
BA_ "U_U55X_MY2022_Tx" SG_ 357 AccStopMde_D_Rq 1;
BA_ "U_CD542_MY2021_Tx" SG_ 357 AccStopMde_D_Rq 1;
BA_ "U_T6_MCA_MY2020_Tx" SG_ 357 AccStopMde_D_Rq 1;
BA_ "U_P702_MY2021_Tx" SG_ 357 AccStopMde_D_Rq 1;
BA_ "U_U55X_MY2022_Rx" SG_ 357 AccStopMde_D_Rq 1;
BA_ "U_CD542_MY2021_Rx" SG_ 357 AccStopMde_D_Rq 1;
BA_ "U_T6_MCA_MY2020_Rx" SG_ 357 AccStopMde_D_Rq 1;
BA_ "U_P702_MY2021_Rx" SG_ 357 AccStopMde_D_Rq 1;
BA_ "U_CX727_MY2021_Rx" SG_ 357 AccStopMde_D_Rq 1;
BA_ "U_T6_MCA_MY2020_Tx" SG_ 355 AutoRgenTxt_B_RqDsply 1;
BA_ "U_P702_MY2021_Tx" SG_ 355 AutoRgenTxt_B_RqDsply 1;
BA_ "ECGUsedRxSignal" SG_ 355 AutoRgenTxt_B_RqDsply 1;
BA_ "U_T6_MCA_MY2020_Tx" SG_ 355 AccFllwMdeActv_B_Actl 1;
BA_ "U_P702_MY2021_Tx" SG_ 355 AccFllwMdeActv_B_Actl 1;
BA_ "U_T6_MCA_MY2020_Tx" SG_ 355 EngPtoMde_D_Actl 1;
BA_ "U_P702_MY2021_Tx" SG_ 355 EngPtoMde_D_Actl 1;
BA_ "U_T6_MCA_MY2020_Tx" SG_ 355 ManRgenTxt_D_RqDsply 1;
BA_ "U_P702_MY2021_Tx" SG_ 355 ManRgenTxt_D_RqDsply 1;
BA_ "ECGUsedRxSignal" SG_ 355 ManRgenTxt_D_RqDsply 1;
BA_ "U_T6_MCA_MY2020_Tx" SG_ 355 ManRgenSoot_Pc_RqDsply 1;
BA_ "U_P702_MY2021_Tx" SG_ 355 ManRgenSoot_Pc_RqDsply 1;
BA_ "ECGUsedRxSignal" SG_ 355 ManRgenSoot_Pc_RqDsply 1;
BA_ "U_T6_MCA_MY2020_Tx" SG_ 355 DieslMsgTxt_D_Rq 1;
BA_ "U_P702_MY2021_Tx" SG_ 355 DieslMsgTxt_D_Rq 1;
BA_ "U_CD542_MY2021_Tx" SG_ 342 HtrLoop_B_Stat 1;
BA_ "U_CX727_MY2021_Tx" SG_ 342 HtrLoop_B_Stat 1;
BA_ "U_CD542_MY2021_Rx" SG_ 342 HtrLoop_B_Stat 1;
BA_ "U_CX727_MY2021_Rx" SG_ 342 HtrLoop_B_Stat 1;
BA_ "U_CX727_MY2021_Tx" SG_ 342 EngOvrhtMitgActv_D_Ind 1;
BA_ "U_U55X_MY2022_Tx" SG_ 342 EngOvrhtMitgActv_D_Ind 1;
BA_ "U_CD542_MY2021_Tx" SG_ 342 EngOvrhtMitgActv_D_Ind 1;
BA_ "U_T6_MCA_MY2020_Tx" SG_ 342 EngOvrhtMitgActv_D_Ind 1;
BA_ "U_P702_MY2021_Tx" SG_ 342 EngOvrhtMitgActv_D_Ind 1;
BA_ "ContentDependant" SG_ 342 EngOvrhtMitgActv_D_Ind 1;
BA_ "U_CX727_MY2021_Tx" SG_ 342 EngClntTe_D_Qf 1;
BA_ "U_U55X_MY2022_Tx" SG_ 342 EngClntTe_D_Qf 1;
BA_ "U_CD542_MY2021_Tx" SG_ 342 EngClntTe_D_Qf 1;
BA_ "U_T6_MCA_MY2020_Tx" SG_ 342 EngClntTe_D_Qf 1;
BA_ "U_P702_MY2021_Tx" SG_ 342 EngClntTe_D_Qf 1;
BA_ "U_T6_MCA_MY2020_Rx" SG_ 342 EngClntTe_D_Qf 1;
BA_ "U_CD542_MY2021_Rx" SG_ 342 EngClntTe_D_Qf 1;
BA_ "U_P702_MY2021_Rx" SG_ 342 EngClntTe_D_Qf 1;
BA_ "U_CX727_MY2021_Rx" SG_ 342 EngClntTe_D_Qf 1;
BA_ "MetaData" SG_ 342 EngClntTe_D_Qf 1;
BA_ "U_CD542_MY2021_Tx" SG_ 342 EngGoutLss_Tq_Est 1;
BA_ "U_CX727_MY2021_Tx" SG_ 342 EngGoutLss_Tq_Est 1;
BA_ "U_P702_MY2021_Tx" SG_ 342 EngGoutLss_Tq_Est 1;
BA_ "U_CD542_MY2021_Rx" SG_ 342 EngGoutLss_Tq_Est 1;
BA_ "U_P702_MY2021_Rx" SG_ 342 EngGoutLss_Tq_Est 1;
BA_ "U_CX727_MY2021_Rx" SG_ 342 EngGoutLss_Tq_Est 1;
BA_ "ContentDependant" SG_ 342 EngGoutLss_Tq_Est 1;
BA_ "U_T6_MCA_MY2020_Tx" SG_ 342 EngOil_Te_Actl 1;
BA_ "U_P702_MY2021_Tx" SG_ 342 EngOil_Te_Actl 1;
BA_ "U_T6_MCA_MY2020_Rx" SG_ 342 EngOil_Te_Actl 1;
BA_ "U_CX727_MY2021_Tx" SG_ 342 EngClnt_Te_Actl 1;
BA_ "U_U55X_MY2022_Tx" SG_ 342 EngClnt_Te_Actl 1;
BA_ "U_CD542_MY2021_Tx" SG_ 342 EngClnt_Te_Actl 1;
BA_ "U_T6_MCA_MY2020_Tx" SG_ 342 EngClnt_Te_Actl 1;
BA_ "U_P702_MY2021_Tx" SG_ 342 EngClnt_Te_Actl 1;
BA_ "ECGUsedRxSignal" SG_ 342 EngClnt_Te_Actl 1;
BA_ "U_T6_MCA_MY2020_Rx" SG_ 342 EngClnt_Te_Actl 1;
BA_ "U_CD542_MY2021_Rx" SG_ 342 EngClnt_Te_Actl 1;
BA_ "U_P702_MY2021_Rx" SG_ 342 EngClnt_Te_Actl 1;
BA_ "U_CX727_MY2021_Rx" SG_ 342 EngClnt_Te_Actl 1;
BA_ "U_T6_MCA_MY2020_Tx" SG_ 1520 AWD_GWOnBoardTester 1;
BA_ "GenSigStartValue" SG_ 1520 AWD_GWOnBoardTester 255;
BA_ "ContentDependant" SG_ 1520 AWD_GWOnBoardTester 1;
BA_ "GenSigStartValueInteger" SG_ 1520 AWD_GWOnBoardTester 255;
BA_ "U_T6_MCA_MY2020_Tx" SG_ 1520 AWD_GWNMProxy 1;
BA_ "GenSigStartValue" SG_ 1520 AWD_GWNMProxy 255;
BA_ "ContentDependant" SG_ 1520 AWD_GWNMProxy 1;
BA_ "GenSigStartValueInteger" SG_ 1520 AWD_GWNMProxy 255;
BA_ "U_T6_MCA_MY2020_Tx" SG_ 1520 AWD_AutoSarNMReserved4 1;
BA_ "GenSigStartValue" SG_ 1520 AWD_AutoSarNMReserved4 255;
BA_ "ContentDependant" SG_ 1520 AWD_AutoSarNMReserved4 1;
BA_ "GenSigStartValueInteger" SG_ 1520 AWD_AutoSarNMReserved4 255;
BA_ "U_T6_MCA_MY2020_Tx" SG_ 1520 AWD_AutoSarNMReserved3 1;
BA_ "GenSigStartValue" SG_ 1520 AWD_AutoSarNMReserved3 255;
BA_ "ContentDependant" SG_ 1520 AWD_AutoSarNMReserved3 1;
BA_ "GenSigStartValueInteger" SG_ 1520 AWD_AutoSarNMReserved3 255;
BA_ "U_T6_MCA_MY2020_Tx" SG_ 1520 AWD_AutoSarNMReserved2 1;
BA_ "GenSigStartValue" SG_ 1520 AWD_AutoSarNMReserved2 255;
BA_ "ContentDependant" SG_ 1520 AWD_AutoSarNMReserved2 1;
BA_ "GenSigStartValueInteger" SG_ 1520 AWD_AutoSarNMReserved2 255;
BA_ "U_T6_MCA_MY2020_Tx" SG_ 1520 AWD_AutoSarNMReserved1 1;
BA_ "GenSigStartValue" SG_ 1520 AWD_AutoSarNMReserved1 255;
BA_ "ContentDependant" SG_ 1520 AWD_AutoSarNMReserved1 1;
BA_ "GenSigStartValueInteger" SG_ 1520 AWD_AutoSarNMReserved1 255;
BA_ "U_T6_MCA_MY2020_Tx" SG_ 1520 AWD_AutoSarNMNodeId 1;
BA_ "GenSigStartValue" SG_ 1520 AWD_AutoSarNMNodeId 240;
BA_ "ContentDependant" SG_ 1520 AWD_AutoSarNMNodeId 1;
BA_ "GenSigStartValueInteger" SG_ 1520 AWD_AutoSarNMNodeId 240;
BA_ "U_T6_MCA_MY2020_Tx" SG_ 1520 AWD_AutoSarNMControl 1;
BA_ "ContentDependant" SG_ 1520 AWD_AutoSarNMControl 1;
BA_ "U_U55X_MY2022_Tx" SG_ 71 immoTarget1Status 1;
BA_ "U_T6_MCA_MY2020_Tx" SG_ 71 immoTarget1Status 1;
BA_ "U_CD542_MY2021_Tx" SG_ 71 immoTarget1Status 1;
BA_ "U_P702_MY2021_Tx" SG_ 71 immoTarget1Status 1;
BA_ "U_CX727_MY2021_Tx" SG_ 71 immoTarget1Status 1;
BA_ "U_U55X_MY2022_Rx" SG_ 71 immoTarget1Status 1;
BA_ "U_CD542_MY2021_Rx" SG_ 71 immoTarget1Status 1;
BA_ "U_CX727_MY2021_Rx" SG_ 71 immoTarget1Status 1;
BA_ "U_T6_MCA_MY2020_Rx" SG_ 71 immoTarget1Status 1;
BA_ "U_P702_MY2021_Rx" SG_ 71 immoTarget1Status 1;
BA_ "U_U55X_MY2022_Tx" SG_ 71 immoTarget1Data 1;
BA_ "U_T6_MCA_MY2020_Tx" SG_ 71 immoTarget1Data 1;
BA_ "U_CD542_MY2021_Tx" SG_ 71 immoTarget1Data 1;
BA_ "U_P702_MY2021_Tx" SG_ 71 immoTarget1Data 1;
BA_ "U_CX727_MY2021_Tx" SG_ 71 immoTarget1Data 1;
BA_ "U_U55X_MY2022_Rx" SG_ 71 immoTarget1Data 1;
BA_ "U_CD542_MY2021_Rx" SG_ 71 immoTarget1Data 1;
BA_ "U_T6_MCA_MY2020_Rx" SG_ 71 immoTarget1Data 1;
BA_ "U_P702_MY2021_Rx" SG_ 71 immoTarget1Data 1;
BA_ "U_CX727_MY2021_Rx" SG_ 71 immoTarget1Data 1;
BA_ "U_U55X_MY2022_Tx" SG_ 71 immoTarget1Cmd 1;
BA_ "U_T6_MCA_MY2020_Tx" SG_ 71 immoTarget1Cmd 1;
BA_ "U_CD542_MY2021_Tx" SG_ 71 immoTarget1Cmd 1;
BA_ "U_P702_MY2021_Tx" SG_ 71 immoTarget1Cmd 1;
BA_ "U_CX727_MY2021_Tx" SG_ 71 immoTarget1Cmd 1;
BA_ "U_U55X_MY2022_Rx" SG_ 71 immoTarget1Cmd 1;
BA_ "U_CD542_MY2021_Rx" SG_ 71 immoTarget1Cmd 1;
BA_ "U_T6_MCA_MY2020_Rx" SG_ 71 immoTarget1Cmd 1;
BA_ "U_P702_MY2021_Rx" SG_ 71 immoTarget1Cmd 1;
BA_ "U_CX727_MY2021_Rx" SG_ 71 immoTarget1Cmd 1;
BA_ "ECGUsedTxSignal" SG_ 824 DteCldTrlrOn_B_Stat 1;
BA_ "GenSigSendType" SG_ 824 DteCldTrlrOn_B_Stat 3;
BA_ "ECGUsedTxSignal" SG_ 824 DteCldTrlrOff_B_Stat 1;
BA_ "GenSigSendType" SG_ 824 DteCldTrlrOff_B_Stat 3;
BA_ "ECGUsedTxSignal" SG_ 824 DteCldTraffic_B_Stat 1;
BA_ "GenSigSendType" SG_ 824 DteCldTraffic_B_Stat 3;
BA_ "ECGUsedTxSignal" SG_ 824 DteCldTerrain_B_Stat 1;
BA_ "GenSigSendType" SG_ 824 DteCldTerrain_B_Stat 3;
BA_ "ECGUsedTxSignal" SG_ 824 DteCldRoute_B_Stat 1;
BA_ "GenSigSendType" SG_ 824 DteCldRoute_B_Stat 3;
BA_ "ECGUsedTxSignal" SG_ 824 DteCldPayload_B_Stat 1;
BA_ "GenSigSendType" SG_ 824 DteCldPayload_B_Stat 3;
BA_ "ECGUsedTxSignal" SG_ 824 DteCldId_No_Actl 1;
BA_ "GenSigSendType" SG_ 824 DteCldId_No_Actl 3;
BA_ "ECGUsedTxSignal" SG_ 824 DteCldExtTe_B_Stat 1;
BA_ "GenSigSendType" SG_ 824 DteCldExtTe_B_Stat 3;
BA_ "ECGUsedTxSignal" SG_ 824 DteCldExt_Eff_Actl 1;
BA_ "GenSigStartValue" SG_ 824 DteCldExt_Eff_Actl 100;
BA_ "ECGUsedTxSignal" SG_ 824 DteCldDrv_Eff_Actl 1;
BA_ "GenSigStartValue" SG_ 824 DteCldDrv_Eff_Actl 100;
BA_ "ECGUsedTxSignal" SG_ 824 DteCldDcac_B_Stat 1;
BA_ "GenSigSendType" SG_ 824 DteCldDcac_B_Stat 3;
BA_ "ECGUsedTxSignal" SG_ 824 DteCldClimt_Eff_Actl 1;
BA_ "GenSigStartValue" SG_ 824 DteCldClimt_Eff_Actl 100;
BA_ "ECGUsedTxSignal" SG_ 824 DteCldBattULo_Eff_Actl 1;
BA_ "GenSigStartValue" SG_ 824 DteCldBattULo_Eff_Actl 100;
BA_ "ECGUsedTxSignal" SG_ 824 DteCldTrip_L2_Actl 1;
BA_ "GenSigStartValue" SG_ 824 DteCldTrip_L2_Actl 8190;
BA_ "ECGUsedRxSignal" SG_ 823 DteVehPwId_No_Actl 1;
BA_ "GenSigSendType" SG_ 823 DteVehPwId_No_Actl 3;
BA_ "ECGUsedRxSignal" SG_ 823 DteVehEId_No_Actl 1;
BA_ "ECGUsedRxSignal" SG_ 823 DteVehEffId_No_Actl 1;
BA_ "ECGUsedRxSignal" SG_ 823 DteVeh_Pw_Actl 1;
BA_ "ECGUsedRxSignal" SG_ 823 DteVeh_Eff_Actl 1;
BA_ "GenSigStartValue" SG_ 823 DteVeh_Eff_Actl 100;
BA_ "ECGUsedRxSignal" SG_ 823 DteVeh_E_Actl 1;
BA_ "ECGUsedRxSignal" SG_ 823 DteAcceptNew_B_Rq 1;
BA_ "GenSigSendType" SG_ 823 DteAcceptNew_B_Rq 3;
BA_ "ECGUsedRxSignal" SG_ 823 DteVehE_T_Actl 1;
BA_ "GenSigSendType" SG_ 1920 TesterPhysicalReqSGM 3;
BA_ "GenSigStartValue" SG_ 811 ScMnSoc_Pc_RqMnu 126;
BA_ "GenSigStartValue" SG_ 811 DistToStopover_L_Actl 65535;
BA_ "WakeupSignal" SG_ 811 ExtLghtRight_D_RqMnu 1;
BA_ "WakeupSignal" SG_ 811 AutoLghtOvrrd_B_RqDrv 1;
BA_ "WakeupSignal" SG_ 811 ExtLghtRear_D_RqMnu 1;
BA_ "WakeupSignal" SG_ 811 ExtLghtLeft_D_RqMnu 1;
BA_ "WakeupSignal" SG_ 811 ExtLghtFront_D_RqMnu 1;
BA_ "GenSigStartValue" SG_ 811 GoTEditMnte_T_RqMnu 14;
BA_ "GenSigStartValue" SG_ 811 GoTEditHr_T_RqMnu 30;
BA_ "WakeupSignal" SG_ 811 BecRleas_No_RqMnu 1;
BA_ "WakeupSignal" SG_ 811 TrnkFrontRleas_No_RqMnu 1;
BA_ "GenSigSendType" SG_ 785 EcoIdl_D_Stat 3;
BA_ "GenSigStartValue" SG_ 785 DteVehOffst_L_Dsply 8190;
BA_ "GenSigSendType" SG_ 785 DteVehOffstMsgTxt_D_Rq 3;
BA_ "GenSigSendType" SG_ 785 PwPckTqRdyChime_B_Rq 3;
BA_ "ECGUsedRxSignal" SG_ 785 BattTracLoThres_D_Stat 1;
BA_ "GenSigSendType" SG_ 785 BattTracLoThres_D_Stat 3;
BA_ "GenSigSendType" SG_ 785 BattTracLoMsgTxt_D_Rq 3;
BA_ "GenSigSendType" SG_ 785 DestSocRqd_Pc_Dsply 3;
BA_ "GenSigSendType" SG_ 785 DestChrgEndMin_No_Actl 3;
BA_ "GenSigSendType" SG_ 785 DestChrgEndHr_No_Actl 3;
BA_ "GenSigSendType" SG_ 785 DestChrgEndDay_No_Actl 3;
BA_ "GenSigStartValue" SG_ 785 DestChrgEndDay_No_Actl 1;
BA_ "ECGUsedRxSignal" SG_ 785 BattTracLoSoc_D_Dsply 1;
BA_ "GenSigSendType" SG_ 785 BattTracLoSoc_D_Dsply 3;
BA_ "ECGUsedRxSignal" SG_ 770 ScMnSoc_Pc_Actl 1;
BA_ "GenSigSendType" SG_ 770 ScMnSoc_Pc_Actl 3;
BA_ "GenSigStartValue" SG_ 770 ScMnSoc_Pc_Actl 100;
BA_ "GenSigSendType" SG_ 770 CurntTrgtSoc_Pc_Rq 3;
BA_ "GenSigStartValue" SG_ 770 CurntTrgtSoc_Pc_Rq 100;
BA_ "ECGUsedRxSignal" SG_ 770 FstChrgBulk_T_Est 1;
BA_ "GenSigSendType" SG_ 770 FstChrgBulk_T_Est 3;
BA_ "ECGUsedRxSignal" SG_ 770 CurntTrgtSoc_Pc_Dsply 1;
BA_ "GenSigSendType" SG_ 770 CurntTrgtSoc_Pc_Dsply 3;
BA_ "GenSigStartValue" SG_ 770 CurntTrgtSoc_Pc_Dsply 100;
BA_ "ECGUsedRxSignal" SG_ 770 ScPayloadUpdate_B_Stat 1;
BA_ "GenSigSendType" SG_ 770 ScPayloadUpdate_B_Stat 3;
BA_ "ECGUsedRxSignal" SG_ 770 ScLocPwId_No_Stat 1;
BA_ "GenSigSendType" SG_ 770 ScLocPwId_No_Stat 3;
BA_ "ECGUsedRxSignal" SG_ 770 ScChrgrPwMax_Pw_Actl 1;
BA_ "ECGUsedRxSignal" SG_ 770 ScLocIdCurnt_No_Stat 1;
BA_ "GenSigSendType" SG_ 770 ScLocIdCurnt_No_Stat 3;
BA_ "ECGUsedRxSignal" SG_ 770 ScEnbl_B_Stat 1;
BA_ "GenSigSendType" SG_ 770 ScEnbl_B_Stat 3;
BA_ "GenSigSendType" SG_ 1205 CstmDrvMdeCfg2_B_Avail 3;
BA_ "GenSigSendType" SG_ 1205 CstmDrvMdeCfg1_B_Avail 3;
BA_ "GenSigSendType" SG_ 1205 CstmDrvMde_No_Confg2 3;
BA_ "GenSigStartValue" SG_ 1205 CstmDrvMde_No_Confg2 63;
BA_ "GenSigSendType" SG_ 1205 CstmDrvMde_No_Confg1 3;
BA_ "GenSigStartValue" SG_ 1205 CstmDrvMde_No_Confg1 63;
BA_ "GenSigSendType" SG_ 1205 CstmDrvMde_No_Confg 3;
BA_ "GenSigSendType" SG_ 1205 CstmDrvMde5_No_Confg2 3;
BA_ "GenSigStartValue" SG_ 1205 CstmDrvMde5_No_Confg2 15;
BA_ "GenSigSendType" SG_ 1205 CstmDrvMde5_No_Confg1 3;
BA_ "GenSigStartValue" SG_ 1205 CstmDrvMde5_No_Confg1 15;
BA_ "GenSigSendType" SG_ 1205 CstmDrvMde4_No_Confg2 3;
BA_ "GenSigStartValue" SG_ 1205 CstmDrvMde4_No_Confg2 15;
BA_ "GenSigSendType" SG_ 1205 CstmDrvMde4_No_Confg1 3;
BA_ "GenSigStartValue" SG_ 1205 CstmDrvMde4_No_Confg1 15;
BA_ "GenSigSendType" SG_ 1205 CstmDrvMde3_No_Confg2 3;
BA_ "GenSigStartValue" SG_ 1205 CstmDrvMde3_No_Confg2 15;
BA_ "GenSigSendType" SG_ 1205 CstmDrvMde3_No_Confg1 3;
BA_ "GenSigStartValue" SG_ 1205 CstmDrvMde3_No_Confg1 15;
BA_ "GenSigSendType" SG_ 1205 CstmDrvMde2_No_Confg2 3;
BA_ "GenSigStartValue" SG_ 1205 CstmDrvMde2_No_Confg2 15;
BA_ "GenSigSendType" SG_ 1205 CstmDrvMde2_No_Confg1 3;
BA_ "GenSigStartValue" SG_ 1205 CstmDrvMde2_No_Confg1 15;
BA_ "GenSigSendType" SG_ 1205 CstmDrvMde1_No_Confg2 3;
BA_ "GenSigStartValue" SG_ 1205 CstmDrvMde1_No_Confg2 15;
BA_ "GenSigSendType" SG_ 1205 CstmDrvMde1_No_Confg1 3;
BA_ "GenSigStartValue" SG_ 1205 CstmDrvMde1_No_Confg1 15;
BA_ "GenSigSendType" SG_ 942 PrkAidAcsyRear_D_Stat 3;
BA_ "GenSigSendType" SG_ 942 PrkAidAcsyFront_D_Stat 3;
BA_ "GenSigSendType" SG_ 942 PrkAidRdiusRight_L_Dsply 3;
BA_ "GenSigSendType" SG_ 942 PrkAidRdiusLeft_L_Dsply 3;
BA_ "GenSigSendType" SG_ 942 PrkAidDrvDir_D_Stat 3;
BA_ "GenSigStartValue" SG_ 123 BattTrac_U2_Actl 4094;
BA_ "GenSigStartValueInteger" SG_ 123 BattTrac_U2_Actl 1022;
BA_ "GenSigStartValue" SG_ 123 BattTrac_I2_Actl 262142;
BA_ "GenSigStartValueInteger" SG_ 123 BattTrac_I2_Actl 15000;
BA_ "ECGUsedTxSignal" SG_ 2612052184 PARSEDPushFcGWM_ECGtoPSCM 1;
BA_ "U_CD542_MY2021_Rx" SG_ 2612052184 PARSEDPushFcGWM_ECGtoPSCM 1;
BA_ "GenSigSendType" SG_ 2612052184 PARSEDPushFcGWM_ECGtoPSCM 3;
BA_ "ECGUsedRxSignal" SG_ 2612224187 PARSEDPushFcCMRtoGWM_ECG 1;
BA_ "U_T6_MCA_MY2020_Rx" SG_ 2612224187 PARSEDPushFcCMRtoGWM_ECG 1;
BA_ "GenSigSendType" SG_ 2612224187 PARSEDPushFcCMRtoGWM_ECG 3;
BA_ "U_T6_MCA_MY2020_Tx" SG_ 1201 FrontDiffLck_D_RqDrv2 1;
BA_ "GenSigSendType" SG_ 1201 FrontDiffLck_D_RqDrv2 3;
BA_ "GenSigStartValue" SG_ 1201 FrontDiffLck_D_RqDrv2 2;
BA_ "GenSigStartValueInteger" SG_ 1201 FrontDiffLck_D_RqDrv2 2;
BA_ "U_T6_MCA_MY2020_Tx" SG_ 1201 RearDiffLck_D_RqDrv2 1;
BA_ "GenSigSendType" SG_ 1201 RearDiffLck_D_RqDrv2 3;
BA_ "GenSigStartValue" SG_ 1201 RearDiffLck_D_RqDrv2 2;
BA_ "GenSigStartValueInteger" SG_ 1201 RearDiffLck_D_RqDrv2 2;
BA_ "U_T6_MCA_MY2020_Tx" SG_ 1201 DrvSlipCtlMde_B_Rq5 1;
BA_ "GenSigSendType" SG_ 1201 DrvSlipCtlMde_B_Rq5 3;
BA_ "U_T6_MCA_MY2020_Tx" SG_ 1201 StabBarCnncButtn_D_Sta2 1;
BA_ "GenSigSendType" SG_ 1201 StabBarCnncButtn_D_Sta2 3;
BA_ "U_T6_MCA_MY2020_Tx" SG_ 1201 OrtaSwtch_D_Stat 1;
BA_ "U_U55X_MY2022_Rx" SG_ 1201 OrtaSwtch_D_Stat 1;
BA_ "U_T6_MCA_MY2020_Rx" SG_ 1201 OrtaSwtch_D_Stat 1;
BA_ "GenSigSendType" SG_ 1201 OrtaSwtch_D_Stat 3;
BA_ "GenSigSendType" SG_ 1912 TesterPhysicalResSIMA 3;
BA_ "GenSigSendType" SG_ 1904 TesterPhysicalReqSIMA 3;
BA_ "U_T6_MCA_MY2020_Tx" SG_ 1527 SIMA_GWOnBoardTester 1;
BA_ "GenSigStartValue" SG_ 1527 SIMA_GWOnBoardTester 255;
BA_ "ContentDependant" SG_ 1527 SIMA_GWOnBoardTester 1;
BA_ "GenSigStartValueInteger" SG_ 1527 SIMA_GWOnBoardTester 255;
BA_ "U_T6_MCA_MY2020_Tx" SG_ 1527 SIMA_GWNMProxy 1;
BA_ "GenSigStartValue" SG_ 1527 SIMA_GWNMProxy 255;
BA_ "ContentDependant" SG_ 1527 SIMA_GWNMProxy 1;
BA_ "GenSigStartValueInteger" SG_ 1527 SIMA_GWNMProxy 255;
BA_ "U_T6_MCA_MY2020_Tx" SG_ 1527 SIMA_AutoSarNMReserved4 1;
BA_ "GenSigStartValue" SG_ 1527 SIMA_AutoSarNMReserved4 255;
BA_ "ContentDependant" SG_ 1527 SIMA_AutoSarNMReserved4 1;
BA_ "GenSigStartValueInteger" SG_ 1527 SIMA_AutoSarNMReserved4 255;
BA_ "U_T6_MCA_MY2020_Tx" SG_ 1527 SIMA_AutoSarNMReserved3 1;
BA_ "GenSigStartValue" SG_ 1527 SIMA_AutoSarNMReserved3 255;
BA_ "ContentDependant" SG_ 1527 SIMA_AutoSarNMReserved3 1;
BA_ "GenSigStartValueInteger" SG_ 1527 SIMA_AutoSarNMReserved3 255;
BA_ "U_T6_MCA_MY2020_Tx" SG_ 1527 SIMA_AutoSarNMReserved2 1;
BA_ "GenSigStartValue" SG_ 1527 SIMA_AutoSarNMReserved2 255;
BA_ "ContentDependant" SG_ 1527 SIMA_AutoSarNMReserved2 1;
BA_ "GenSigStartValueInteger" SG_ 1527 SIMA_AutoSarNMReserved2 255;
BA_ "U_T6_MCA_MY2020_Tx" SG_ 1527 SIMA_AutoSarNMReserved1 1;
BA_ "GenSigStartValue" SG_ 1527 SIMA_AutoSarNMReserved1 255;
BA_ "ContentDependant" SG_ 1527 SIMA_AutoSarNMReserved1 1;
BA_ "GenSigStartValueInteger" SG_ 1527 SIMA_AutoSarNMReserved1 255;
BA_ "U_T6_MCA_MY2020_Tx" SG_ 1527 SIMA_AutoSarNMNodeId 1;
BA_ "GenSigStartValue" SG_ 1527 SIMA_AutoSarNMNodeId 247;
BA_ "ContentDependant" SG_ 1527 SIMA_AutoSarNMNodeId 1;
BA_ "GenSigStartValueInteger" SG_ 1527 SIMA_AutoSarNMNodeId 166;
BA_ "U_T6_MCA_MY2020_Tx" SG_ 1527 SIMA_AutoSarNMControl 1;
BA_ "ContentDependant" SG_ 1527 SIMA_AutoSarNMControl 1;
BA_ "U_T6_MCA_MY2020_Rx" SG_ 949 Tire_Press_RR_ORR_Data 1;
BA_ "GenSigStartValue" SG_ 949 Tire_Press_RR_ORR_Data 65533;
BA_ "GenSigStartValueInteger" SG_ 949 Tire_Press_RR_ORR_Data 65533;
BA_ "U_T6_MCA_MY2020_Rx" SG_ 949 Tire_Press_LR_OLR_Data 1;
BA_ "GenSigStartValue" SG_ 949 Tire_Press_LR_OLR_Data 65533;
BA_ "GenSigStartValueInteger" SG_ 949 Tire_Press_LR_OLR_Data 65533;
BA_ "U_T6_MCA_MY2020_Rx" SG_ 949 Tire_Press_LF_Data 1;
BA_ "GenSigStartValue" SG_ 949 Tire_Press_LF_Data 65533;
BA_ "GenSigStartValueInteger" SG_ 949 Tire_Press_LF_Data 65533;
BA_ "U_T6_MCA_MY2020_Rx" SG_ 949 Tire_Press_RF_Data 1;
BA_ "GenSigStartValue" SG_ 949 Tire_Press_RF_Data 65533;
BA_ "GenSigStartValueInteger" SG_ 949 Tire_Press_RF_Data 65533;
BA_ "ECGUsedTxSignal" SG_ 2612118744 PARSEDPushFcGWM_ECGtoHCM 1;
BA_ "GenSigSendType" SG_ 2612118744 PARSEDPushFcGWM_ECGtoHCM 3;
BA_ "ECGUsedTxSignal" SG_ 2612074712 PARSEDPushFcGWMtoSODCMD 1;
BA_ "GenSigSendType" SG_ 2612074712 PARSEDPushFcGWMtoSODCMD 3;
BA_ "ECGUsedTxSignal" SG_ 2612024536 PARSEDPushFcGWM_ECGtoCCM 1;
BA_ "GenSigSendType" SG_ 2612024536 PARSEDPushFcGWM_ECGtoCCM 3;
BA_ "ECGUsedTxSignal" SG_ 2612036824 PARSEDPushFcGWM_ECGtoIPMA 1;
BA_ "GenSigSendType" SG_ 2612036824 PARSEDPushFcGWM_ECGtoIPMA 3;
BA_ "ECGUsedTxSignal" SG_ 2612103384 PARSEDPushFcGWM_ECGtoSODL 1;
BA_ "GenSigSendType" SG_ 2612103384 PARSEDPushFcGWM_ECGtoSODL 3;
BA_ "ECGUsedTxSignal" SG_ 639 OfbChrgPrflUpdate_B_Rq 1;
BA_ "GenSigSendType" SG_ 639 OfbChrgPrflUpdate_B_Rq 3;
BA_ "ECGUsedTxSignal" SG_ 639 OfbChrgClearAll_B_Rq 1;
BA_ "GenSigSendType" SG_ 639 OfbChrgClearAll_B_Rq 3;
BA_ "ECGUsedTxSignal" SG_ 639 OfbChrgGoTTouch_D_Rq 1;
BA_ "GenSigSendType" SG_ 639 OfbChrgGoTTouch_D_Rq 3;
BA_ "ECGUsedTxSignal" SG_ 639 OfbChrgGoTPrcond_D_Rq 1;
BA_ "ECGUsedTxSignal" SG_ 639 OfbChrgGoTOn_D_Rq 1;
BA_ "GenSigSendType" SG_ 639 OfbChrgGoTOn_D_Rq 3;
BA_ "GenSigStartValueInteger" SG_ 639 OfbChrgGoTOn_D_Rq 2;
BA_ "ECGUsedTxSignal" SG_ 639 OfbChrgGoTMnte_D_Rq 1;
BA_ "ECGUsedTxSignal" SG_ 639 OfbChrgGoTHr_T_Rq 1;
BA_ "GenSigStartValue" SG_ 639 OfbChrgGoTHr_T_Rq 30;
BA_ "GenSigStartValueInteger" SG_ 639 OfbChrgGoTHr_T_Rq 30;
BA_ "ECGUsedTxSignal" SG_ 639 OfbChrgGoTExtHtr_D_Rq 1;
BA_ "GenSigSendType" SG_ 639 OfbChrgGoTExtHtr_D_Rq 3;
BA_ "ECGUsedTxSignal" SG_ 639 OfbChrgGoTElement_D_Rq 1;
BA_ "GenSigSendType" SG_ 639 OfbChrgGoTElement_D_Rq 3;
BA_ "ECGUsedTxSignal" SG_ 639 OfbChrgGoTDelete_B_Rq 1;
BA_ "ECGUsedTxSignal" SG_ 639 OfbChrgGoTUpdate_B_Rq 1;
BA_ "GenSigSendType" SG_ 639 OfbChrgGoTUpdate_B_Rq 3;
BA_ "ECGUsedTxSignal" SG_ 530 OfbChrgLocIdTrgt_No_Rq 1;
BA_ "GenSigSendType" SG_ 530 OfbChrgLocIdTrgt_No_Rq 3;
BA_ "ECGUsedTxSignal" SG_ 530 OfbChrgToPcWknd_D_Actl 1;
BA_ "ECGUsedTxSignal" SG_ 530 OfbChrgToPcWkdy_D_Actl 1;
BA_ "ECGUsedTxSignal" SG_ 530 OfbChrgSetNow_D_Rq 1;
BA_ "ECGUsedTxSignal" SG_ 530 OfbChrgSetDelete_B_Rq 1;
BA_ "ECGUsedTxSignal" SG_ 530 OfbChrgPrflWknd_No_Rq 1;
BA_ "ECGUsedTxSignal" SG_ 530 OfbChrgPrflWkdy_No_Rq 1;
BA_ "ECGUsedTxSignal" SG_ 530 OfbChrgLocIdUns_B_Rq 1;
BA_ "ECGUsedTxSignal" SG_ 550 PtWakeupActv1_B_Rq 1;
BA_ "GenSigSendType" SG_ 550 PtWakeupActv1_B_Rq 3;
BA_ "WakeupSignal" SG_ 550 PtWakeupActv1_B_Rq 1;
BA_ "GenSigStartValue" SG_ 1455 BCMD_GWOnBoardTester 255;
BA_ "ContentDependant" SG_ 1455 BCMD_GWOnBoardTester 1;
BA_ "GenSigStartValueInteger" SG_ 1455 BCMD_GWOnBoardTester 255;
BA_ "GenSigStartValue" SG_ 1455 BCMD_GWNMProxy 255;
BA_ "ContentDependant" SG_ 1455 BCMD_GWNMProxy 1;
BA_ "GenSigStartValueInteger" SG_ 1455 BCMD_GWNMProxy 255;
BA_ "GenSigStartValue" SG_ 1455 BCMD_AutoSarNMReserved4 255;
BA_ "ContentDependant" SG_ 1455 BCMD_AutoSarNMReserved4 1;
BA_ "GenSigStartValueInteger" SG_ 1455 BCMD_AutoSarNMReserved4 255;
BA_ "GenSigStartValue" SG_ 1455 BCMD_AutoSarNMReserved3 255;
BA_ "ContentDependant" SG_ 1455 BCMD_AutoSarNMReserved3 1;
BA_ "GenSigStartValueInteger" SG_ 1455 BCMD_AutoSarNMReserved3 255;
BA_ "GenSigStartValue" SG_ 1455 BCMD_AutoSarNMReserved2 255;
BA_ "ContentDependant" SG_ 1455 BCMD_AutoSarNMReserved2 1;
BA_ "GenSigStartValueInteger" SG_ 1455 BCMD_AutoSarNMReserved2 255;
BA_ "GenSigStartValue" SG_ 1455 BCMD_AutoSarNMReserved1 255;
BA_ "ContentDependant" SG_ 1455 BCMD_AutoSarNMReserved1 1;
BA_ "GenSigStartValueInteger" SG_ 1455 BCMD_AutoSarNMReserved1 255;
BA_ "GenSigStartValue" SG_ 1455 BCMD_AutoSarNMNodeId 175;
BA_ "ContentDependant" SG_ 1455 BCMD_AutoSarNMNodeId 1;
BA_ "GenSigStartValueInteger" SG_ 1455 BCMD_AutoSarNMNodeId 175;
BA_ "ContentDependant" SG_ 1455 BCMD_AutoSarNMControl 1;
BA_ "GenSigSendType" SG_ 1775 TesterPhysicalResBCMD_IPDB 3;
BA_ "GenSigSendType" SG_ 1767 TesterPhysicalReqBCMD_IPDB 3;
BA_ "ECGUsedTxSignal" SG_ 2612019416 PARSEDPushFcGWM_ECGtoPCM 1;
BA_ "U_T6_MCA_MY2020_Rx" SG_ 2612019416 PARSEDPushFcGWM_ECGtoPCM 1;
BA_ "U_U55X_MY2022_Rx" SG_ 2612019416 PARSEDPushFcGWM_ECGtoPCM 1;
BA_ "U_CD542_MY2021_Rx" SG_ 2612019416 PARSEDPushFcGWM_ECGtoPCM 1;
BA_ "GenSigSendType" SG_ 2612019416 PARSEDPushFcGWM_ECGtoPCM 3;
BA_ "ECGUsedTxSignal" SG_ 885 BattULoChrg_D_RqOta 1;
BA_ "U_T6_MCA_MY2020_Tx" SG_ 885 BattULoChrg_D_RqOta 1;
BA_ "ECGUsedTxSignal" SG_ 885 VehStrtInhbt_T_Dsply 1;
BA_ "U_T6_MCA_MY2020_Tx" SG_ 885 VehStrtInhbt_T_Dsply 1;
BA_ "ECGUsedTxSignal" SG_ 885 VehStrtInhbt_D_Dsply 1;
BA_ "U_T6_MCA_MY2020_Tx" SG_ 885 VehStrtInhbt_D_Dsply 1;
BA_ "ECGUsedTxSignal" SG_ 885 VehOnRqstr_D_Stat 1;
BA_ "U_T6_MCA_MY2020_Tx" SG_ 885 VehOnRqstr_D_Stat 1;
BA_ "ECGUsedTxSignal" SG_ 885 VehStrtInhbt_D_RqCld 1;
BA_ "U_T6_MCA_MY2020_Tx" SG_ 885 VehStrtInhbt_D_RqCld 1;
BA_ "ECGUsedTxSignal" SG_ 885 VehOn_D_RqCld 1;
BA_ "U_T6_MCA_MY2020_Tx" SG_ 885 VehOn_D_RqCld 1;
BA_ "ECGUsedTxSignal" SG_ 885 CanMsg375_No_Cnt 1;
BA_ "U_T6_MCA_MY2020_Tx" SG_ 885 CanMsg375_No_Cnt 1;
BA_ "MetaData" SG_ 885 CanMsg375_No_Cnt 1;
BA_ "ECGUsedTxSignal" SG_ 885 CanMsg375_No_Crc 1;
BA_ "U_T6_MCA_MY2020_Tx" SG_ 885 CanMsg375_No_Crc 1;
BA_ "ECGUsedTxSignal" SG_ 885 OtaActv_D_Stat 1;
BA_ "U_T6_MCA_MY2020_Tx" SG_ 885 OtaActv_D_Stat 1;
BA_ "U_T6_MCA_MY2020_Rx" SG_ 885 OtaActv_D_Stat 1;
BA_ "ECGUsedTxSignal" SG_ 2612104408 PARSEDPushFcGWM_ECGtoSODR 1;
BA_ "GenSigSendType" SG_ 2612104408 PARSEDPushFcGWM_ECGtoSODR 3;
BA_ "ECGUsedTxSignal" SG_ 2612020440 PARSEDPushFcGWMtoSOBDMC 1;
BA_ "GenSigSendType" SG_ 2612020440 PARSEDPushFcGWMtoSOBDMC 3;
BA_ "U_CD542_MY2021_Rx" SG_ 979 LatCtlPrecision_D_Rq 1;
BA_ "U_CD542_MY2021_Rx" SG_ 979 LatCtlPathOffst_L_Actl 1;
BA_ "GenSigStartValueInteger" SG_ 979 LatCtlPathOffst_L_Actl 512;
BA_ "U_CD542_MY2021_Rx" SG_ 979 LatCtlPath_An_Actl 1;
BA_ "GenSigStartValueInteger" SG_ 979 LatCtlPath_An_Actl 1000;
BA_ "GenSigStartValueInteger" SG_ 979 LatCtlCurv_NoRate_Actl 4096;
BA_ "U_CD542_MY2021_Rx" SG_ 979 LatCtlCurv_No_Actl 1;
BA_ "GenSigStartValueInteger" SG_ 979 LatCtlCurv_No_Actl 1000;
BA_ "WakeupSignal" SG_ 739 HMI_HMIMode_St 1;
BA_ "ECGUsedTxSignal" SG_ 1160 DgtlCommPncReset_B_Req 1;
BA_ "GenSigSendType" SG_ 1160 DgtlCommPncReset_B_Req 3;
BA_ "ECGUsedTxSignal" SG_ 1160 DgtlCommPnc_D_Rq 1;
BA_ "GenSigSendType" SG_ 1160 DgtlCommPnc_D_Rq 3;
BA_ "ECGUsedTxSignal" SG_ 1160 DataMntrSustn_B_Rq 1;
BA_ "GenSigSendType" SG_ 1160 DataMntrSustn_B_Rq 3;
BA_ "ECGUsedTxSignal" SG_ 1160 PwSustnRdata_B_RqTelem 1;
BA_ "GenSigSendType" SG_ 1160 PwSustnRdata_B_RqTelem 3;
BA_ "U_T6_MCA_MY2020_Rx" SG_ 1825 TesterPhysicalReqVDM 1;
BA_ "GenSigSendType" SG_ 1825 TesterPhysicalReqVDM 3;
BA_ "GenSigStartValue" SG_ 1001 PersIndexSuma_D_Actl 4;
BA_ "GenSigStartValueInteger" SG_ 1001 PersIndexSuma_D_Actl 4;
BA_ "GenSigStartValueInteger" SG_ 1077 AirSprngRear_P_Actl 592;
BA_ "GenSigStartValueInteger" SG_ 1077 AirSprngFront_P_Actl 592;
BA_ "WakeupSignal" SG_ 945 KeyPadCodeDgt6_D_Dsply 1;
BA_ "WakeupSignal" SG_ 945 KeyPadCodeDgt5_D_Dsply 1;
BA_ "WakeupSignal" SG_ 945 KeyPadCodeDgt4_D_Dsply 1;
BA_ "WakeupSignal" SG_ 945 KeyPadCodeDgt3_D_Dsply 1;
BA_ "WakeupSignal" SG_ 945 KeyPadCodeDgt2_D_Dsply 1;
BA_ "WakeupSignal" SG_ 945 KeyPadCodeDgt1_D_Dsply 1;
BA_ "ECGUsedTxSignal" SG_ 2612073688 PARSEDPushFcGWMtoSODCMC 1;
BA_ "GenSigSendType" SG_ 2612073688 PARSEDPushFcGWMtoSODCMC 3;
BA_ "ECGUsedRxSignal" SG_ 771 ScLocSetId_No_Stat 1;
BA_ "GenSigSendType" SG_ 771 ScLocSetId_No_Stat 3;
BA_ "ECGUsedRxSignal" SG_ 771 ScLocRdius_L_Actl 1;
BA_ "GenSigSendType" SG_ 771 ScLocRdius_L_Actl 3;
BA_ "ECGUsedRxSignal" SG_ 771 ScDayOfWeekId_D_Stat 1;
BA_ "GenSigSendType" SG_ 771 ScDayOfWeekId_D_Stat 3;
BA_ "GenSigStartValue" SG_ 771 ScDayOfWeekId_D_Stat 1;
BA_ "ECGUsedRxSignal" SG_ 771 ScChrgToPc_Pc_Actl 1;
BA_ "GenSigSendType" SG_ 771 ScChrgToPc_Pc_Actl 3;
BA_ "ECGUsedRxSignal" SG_ 771 ScChrgPrfl_No_Actl 1;
BA_ "GenSigSendType" SG_ 771 ScChrgPrfl_No_Actl 3;
BA_ "ECGUsedRxSignal" SG_ 771 ScChrgDurSet_B_Stat 1;
BA_ "GenSigSendType" SG_ 771 ScChrgDurSet_B_Stat 3;
BA_ "ECGUsedRxSignal" SG_ 771 ScChrgDur_T_Actl 1;
BA_ "GenSigSendType" SG_ 771 ScChrgDur_T_Actl 3;
BA_ "ECGUsedRxSignal" SG_ 777 ScLocSaved_B_Dsply 1;
BA_ "GenSigSendType" SG_ 777 ScLocSaved_B_Dsply 3;
BA_ "ECGUsedRxSignal" SG_ 777 ScLocLongPostv_B_Stat 1;
BA_ "GenSigSendType" SG_ 777 ScLocLongPostv_B_Stat 3;
BA_ "ECGUsedRxSignal" SG_ 777 ScLocLongFrct_An_Actl 1;
BA_ "GenSigSendType" SG_ 777 ScLocLongFrct_An_Actl 3;
BA_ "GenSigStartValue" SG_ 777 ScLocLongFrct_An_Actl 1048575;
BA_ "ECGUsedRxSignal" SG_ 777 ScLocLongDeg_An_Actl 1;
BA_ "GenSigSendType" SG_ 777 ScLocLongDeg_An_Actl 3;
BA_ "ECGUsedRxSignal" SG_ 777 ScLocLattPostv_B_Stat 1;
BA_ "GenSigSendType" SG_ 777 ScLocLattPostv_B_Stat 3;
BA_ "ECGUsedRxSignal" SG_ 777 ScLocLattFrct_An_Actl 1;
BA_ "GenSigSendType" SG_ 777 ScLocLattFrct_An_Actl 3;
BA_ "GenSigStartValue" SG_ 777 ScLocLattFrct_An_Actl 1048575;
BA_ "ECGUsedRxSignal" SG_ 777 ScLocLattDeg_An_Actl 1;
BA_ "GenSigSendType" SG_ 777 ScLocLattDeg_An_Actl 3;
BA_ "ECGUsedRxSignal" SG_ 777 ScLocId_No_Stat 1;
BA_ "GenSigSendType" SG_ 777 ScLocId_No_Stat 3;
BA_ "GenSigSendType" SG_ 1043 SelDrvMdeHmi02_D_Rq 3;
BA_ "GenSigSendType" SG_ 1043 SelDrvMdeHmi04_D_Rq 3;
BA_ "GenSigSendType" SG_ 1043 IndvMdeSusp_No_Stat 3;
BA_ "GenSigStartValue" SG_ 1043 IndvMdeSusp_No_Stat 15;
BA_ "GenSigSendType" SG_ 1043 IndvMdeSte_No_Stat 3;
BA_ "GenSigStartValue" SG_ 1043 IndvMdeSte_No_Stat 15;
BA_ "GenSigSendType" SG_ 1043 IndvMdeSel_No_Rq 3;
BA_ "GenSigStartValue" SG_ 1043 IndvMdeSel_No_Rq 15;
BA_ "GenSigSendType" SG_ 1043 IndvMdeSel_D_Stat 3;
BA_ "GenSigSendType" SG_ 1043 IndvMdeMsgTxt_D_Rq 3;
BA_ "GenSigSendType" SG_ 1043 IndvMde5_B_Avail 3;
BA_ "GenSigSendType" SG_ 1043 IndvMde4_B_Avail 3;
BA_ "GenSigSendType" SG_ 1043 IndvMde3_B_Avail 3;
BA_ "GenSigSendType" SG_ 1043 IndvMde2_B_Avail 3;
BA_ "GenSigSendType" SG_ 1043 IndvMde1_B_Avail 3;
BA_ "U_T6_MCA_MY2020_Tx" SG_ 1043 TrailOnePdlMde_D_Ind 1;
BA_ "GenSigSendType" SG_ 1043 TrailOnePdlMde_D_Ind 3;
BA_ "U_T6_MCA_MY2020_Tx" SG_ 1043 TrailOnePdlMsgTxt_D_Rq 1;
BA_ "GenSigSendType" SG_ 1043 TrailOnePdlMsgTxt_D_Rq 3;
BA_ "U_U55X_MY2022_Tx" SG_ 1043 OrtaSwtchLamp_B_Rq 1;
BA_ "U_T6_MCA_MY2020_Tx" SG_ 1043 OrtaSwtchLamp_B_Rq 1;
BA_ "U_T6_MCA_MY2020_Rx" SG_ 1043 OrtaSwtchLamp_B_Rq 1;
BA_ "GenSigSendType" SG_ 1043 OrtaSwtchLamp_B_Rq 3;
BA_ "U_U55X_MY2022_Tx" SG_ 1043 OrtaMsgTxt_D_Rq 1;
BA_ "U_T6_MCA_MY2020_Tx" SG_ 1043 OrtaMsgTxt_D_Rq 1;
BA_ "GenSigSendType" SG_ 1043 OrtaMsgTxt_D_Rq 3;
BA_ "U_U55X_MY2022_Tx" SG_ 1043 OrtaMde_D_Ind 1;
BA_ "U_T6_MCA_MY2020_Tx" SG_ 1043 OrtaMde_D_Ind 1;
BA_ "GenSigSendType" SG_ 1043 OrtaMde_D_Ind 3;
BA_ "U_T6_MCA_MY2020_Tx" SG_ 1833 TesterPhysicalResVDM 1;
BA_ "GenSigSendType" SG_ 1833 TesterPhysicalResVDM 3;
BA_ "GenSigSendType" SG_ 991 PersIndexVdm_D_Actl 3;
BA_ "GenSigStartValue" SG_ 991 PersIndexVdm_D_Actl 4;
BA_ "GenSigStartValueInteger" SG_ 991 PersIndexVdm_D_Actl 4;
BA_ "GenSigSendType" SG_ 991 FeatNoVdmActl 3;
BA_ "GenSigSendType" SG_ 991 FeatConfigVdmActl 3;
BA_ "U_T6_MCA_MY2020_Rx" SG_ 395 SelDrvMdeCnfm_D_Stat 1;
BA_ "GenSigStartValue" SG_ 395 HudShifPoint_N_Rq 30;
BA_ "GenSigStartValueInteger" SG_ 395 HudShifPoint_N_Rq 30;
BA_ "U_T6_MCA_MY2020_Tx" SG_ 1689 UUDTAWDResponse2 1;
BA_ "U_T6_MCA_MY2020_Tx" SG_ 515 PtIgnSwtch_D_Stat 1;
BA_ "GenSigSendType" SG_ 515 PtIgnSwtch_D_Stat 3;
BA_ "GenSigStartValue" SG_ 515 PtIgnSwtch_D_Stat 2;
BA_ "GenSigStartValueInteger" SG_ 515 PtIgnSwtch_D_Stat 2;
BA_ "U_CD542_MY2021_Tx" SG_ 982 LatCtlCrv_NoRate2_Actl 1;
BA_ "U_T6_MCA_MY2020_Tx" SG_ 982 LatCtlCrv_NoRate2_Actl 1;
BA_ "U_CD542_MY2021_Rx" SG_ 982 LatCtlCrv_NoRate2_Actl 1;
BA_ "GenSigStartValue" SG_ 982 LatCtlCrv_NoRate2_Actl 1024;
BA_ "U_CD542_MY2021_Tx" SG_ 982 LatCtlPath_No_Cnt 1;
BA_ "U_T6_MCA_MY2020_Tx" SG_ 982 LatCtlPath_No_Cnt 1;
BA_ "MetaData" SG_ 982 LatCtlPath_No_Cnt 1;
BA_ "ContentDependant" SG_ 982 LatCtlPath_No_Cnt 1;
BA_ "U_CD542_MY2021_Tx" SG_ 982 LatCtlPath_No_Cs 1;
BA_ "U_T6_MCA_MY2020_Tx" SG_ 982 LatCtlPath_No_Cs 1;
BA_ "MetaData" SG_ 982 LatCtlPath_No_Cs 1;
BA_ "ContentDependant" SG_ 982 LatCtlPath_No_Cs 1;
BA_ "U_CD542_MY2021_Tx" SG_ 982 LatCtl_D2_Rq 1;
BA_ "U_T6_MCA_MY2020_Tx" SG_ 982 LatCtl_D2_Rq 1;
BA_ "U_CD542_MY2021_Rx" SG_ 982 LatCtl_D2_Rq 1;
BA_ "U_CD542_MY2021_Rx" SG_ 982 LatCtlPrecision_D_Rq 1;
BA_ "U_CD542_MY2021_Rx" SG_ 982 LatCtlPathOffst_L_Actl 1;
BA_ "GenSigStartValueInteger" SG_ 982 LatCtlPathOffst_L_Actl 512;
BA_ "U_CD542_MY2021_Rx" SG_ 982 LatCtlPath_An_Actl 1;
BA_ "GenSigStartValueInteger" SG_ 982 LatCtlPath_An_Actl 1000;
BA_ "U_CD542_MY2021_Rx" SG_ 982 LatCtlCurv_No_Actl 1;
BA_ "GenSigStartValueInteger" SG_ 982 LatCtlCurv_No_Actl 1000;
BA_ "U_T6_MCA_MY2020_Tx" SG_ 1104 DrvEngageLevel_No_Cs 1;
BA_ "U_CD542_MY2021_Rx" SG_ 1104 DrvEngageLevel_No_Cs 1;
BA_ "U_T6_MCA_MY2020_Rx" SG_ 1104 DrvEngageLevel_No_Cs 1;
BA_ "MetaData" SG_ 1104 DrvEngageLevel_No_Cs 1;
BA_ "ContentDependant" SG_ 1104 DrvEngageLevel_No_Cs 1;
BA_ "U_T6_MCA_MY2020_Tx" SG_ 1104 DrvEngageLevel_No_Cnt 1;
BA_ "U_CD542_MY2021_Rx" SG_ 1104 DrvEngageLevel_No_Cnt 1;
BA_ "U_T6_MCA_MY2020_Rx" SG_ 1104 DrvEngageLevel_No_Cnt 1;
BA_ "MetaData" SG_ 1104 DrvEngageLevel_No_Cnt 1;
BA_ "ContentDependant" SG_ 1104 DrvEngageLevel_No_Cnt 1;
BA_ "U_T6_MCA_MY2020_Tx" SG_ 1104 DrvEngageLevel_D_Stat 1;
BA_ "U_CD542_MY2021_Rx" SG_ 1104 DrvEngageLevel_D_Stat 1;
BA_ "U_T6_MCA_MY2020_Rx" SG_ 1104 DrvEngageLevel_D_Stat 1;
BA_ "U_T6_MCA_MY2020_Tx" SG_ 1104 DrvImpLvlConfid_D_Stat 1;
BA_ "U_CD542_MY2021_Rx" SG_ 1104 DrvImpLvlConfid_D_Stat 1;
BA_ "U_T6_MCA_MY2020_Rx" SG_ 1104 DrvImpLvlConfid_D_Stat 1;
BA_ "U_T6_MCA_MY2020_Tx" SG_ 1104 DrvImpairLvl_D_Stat 1;
BA_ "U_CD542_MY2021_Rx" SG_ 1104 DrvImpairLvl_D_Stat 1;
BA_ "U_T6_MCA_MY2020_Rx" SG_ 1104 DrvImpairLvl_D_Stat 1;
BA_ "U_T6_MCA_MY2020_Tx" SG_ 1104 DrvEngLvlConfid_D_Stat 1;
BA_ "U_CD542_MY2021_Rx" SG_ 1104 DrvEngLvlConfid_D_Stat 1;
BA_ "U_T6_MCA_MY2020_Rx" SG_ 1104 DrvEngLvlConfid_D_Stat 1;
BA_ "U_T6_MCA_MY2020_Tx" SG_ 1104 DrvCamPassIR_D_Stat 1;
BA_ "U_CD542_MY2021_Rx" SG_ 1104 DrvCamPassIR_D_Stat 1;
BA_ "U_T6_MCA_MY2020_Rx" SG_ 1104 DrvCamPassIR_D_Stat 1;
BA_ "U_T6_MCA_MY2020_Tx" SG_ 1104 DrvCamera_D_Stat 1;
BA_ "U_CD542_MY2021_Rx" SG_ 1104 DrvCamera_D_Stat 1;
BA_ "U_T6_MCA_MY2020_Rx" SG_ 1104 DrvCamera_D_Stat 1;
BA_ "U_T6_MCA_MY2020_Tx" SG_ 1104 DrvCamDrvIR_D_Stat 1;
BA_ "U_CD542_MY2021_Rx" SG_ 1104 DrvCamDrvIR_D_Stat 1;
BA_ "U_T6_MCA_MY2020_Rx" SG_ 1104 DrvCamDrvIR_D_Stat 1;
BA_ "U_T6_MCA_MY2020_Tx" SG_ 1104 DrvAttentZone_D_Stat 1;
BA_ "U_CD542_MY2021_Rx" SG_ 1104 DrvAttentZone_D_Stat 1;
BA_ "U_T6_MCA_MY2020_Rx" SG_ 1104 DrvAttentZone_D_Stat 1;
BA_ "U_T6_MCA_MY2020_Tx" SG_ 1104 DrvAlertSt_D_Stat 1;
BA_ "U_CD542_MY2021_Rx" SG_ 1104 DrvAlertSt_D_Stat 1;
BA_ "U_T6_MCA_MY2020_Rx" SG_ 1104 DrvAlertSt_D_Stat 1;
BA_ "GenSigStartValue" SG_ 829 DcdcUHi3_I_Actl 2046;
BA_ "ECGUsedTxSignal" SG_ 2611070168 PARSEDPhysGWM_ECGtoHCM 1;
BA_ "GenSigSendType" SG_ 2611070168 PARSEDPhysGWM_ECGtoHCM 3;
BA_ "ECGUsedRxSignal" SG_ 2611175537 PARSEDPhysHCMtoGWM_ECG 1;
BA_ "U_T6_MCA_MY2020_Rx" SG_ 2611175537 PARSEDPhysHCMtoGWM_ECG 1;
BA_ "GenSigSendType" SG_ 2611175537 PARSEDPhysHCMtoGWM_ECG 3;
BA_ "ECGUsedRxSignal" SG_ 2612224113 PARSEDPushHCMtoGWM_ECG 1;
BA_ "U_T6_MCA_MY2020_Rx" SG_ 2612224113 PARSEDPushHCMtoGWM_ECG 1;
BA_ "GenSigSendType" SG_ 2612224113 PARSEDPushHCMtoGWM_ECG 3;
BA_ "ECGUsedTxSignal" SG_ 2610021592 OTAPhysGWM_ECGtoHCM 1;
BA_ "GenSigSendType" SG_ 2610021592 OTAPhysGWM_ECGtoHCM 3;
BA_ "ECGUsedRxSignal" SG_ 2610126961 OTAPhysHCMtoGWM_ECG 1;
BA_ "U_T6_MCA_MY2020_Rx" SG_ 2610126961 OTAPhysHCMtoGWM_ECG 1;
BA_ "GenSigSendType" SG_ 2610126961 OTAPhysHCMtoGWM_ECG 3;
BA_ "ECGUsedTxSignal" SG_ 2610975960 PARSEDPhysGWM_ECGtoCCM 1;
BA_ "U_CD542_MY2021_Rx" SG_ 2610975960 PARSEDPhysGWM_ECGtoCCM 1;
BA_ "U_T6_MCA_MY2020_Rx" SG_ 2610975960 PARSEDPhysGWM_ECGtoCCM 1;
BA_ "GenSigSendType" SG_ 2610975960 PARSEDPhysGWM_ECGtoCCM 3;
BA_ "U_CD542_MY2021_Tx" SG_ 2611175445 PARSEDPhysCCMtoGWM_ECG 1;
BA_ "U_T6_MCA_MY2020_Tx" SG_ 2611175445 PARSEDPhysCCMtoGWM_ECG 1;
BA_ "ECGUsedRxSignal" SG_ 2611175445 PARSEDPhysCCMtoGWM_ECG 1;
BA_ "U_T6_MCA_MY2020_Rx" SG_ 2611175445 PARSEDPhysCCMtoGWM_ECG 1;
BA_ "GenSigSendType" SG_ 2611175445 PARSEDPhysCCMtoGWM_ECG 3;
BA_ "U_CD542_MY2021_Tx" SG_ 2612224021 PARSEDPushCCMtoGWM_ECG 1;
BA_ "U_T6_MCA_MY2020_Tx" SG_ 2612224021 PARSEDPushCCMtoGWM_ECG 1;
BA_ "ECGUsedRxSignal" SG_ 2612224021 PARSEDPushCCMtoGWM_ECG 1;
BA_ "U_T6_MCA_MY2020_Rx" SG_ 2612224021 PARSEDPushCCMtoGWM_ECG 1;
BA_ "GenSigSendType" SG_ 2612224021 PARSEDPushCCMtoGWM_ECG 3;
BA_ "ECGUsedTxSignal" SG_ 2611025112 PARSEDPhysGWM_ECGtoSODCMC 1;
BA_ "U_T6_MCA_MY2020_Rx" SG_ 2611025112 PARSEDPhysGWM_ECGtoSODCMC 1;
BA_ "GenSigSendType" SG_ 2611025112 PARSEDPhysGWM_ECGtoSODCMC 3;
BA_ "U_CD542_MY2021_Tx" SG_ 2611175493 PARSEDPhysSODCMCtoGWM_ECG 1;
BA_ "U_T6_MCA_MY2020_Tx" SG_ 2611175493 PARSEDPhysSODCMCtoGWM_ECG 1;
BA_ "ECGUsedRxSignal" SG_ 2611175493 PARSEDPhysSODCMCtoGWM_ECG 1;
BA_ "U_T6_MCA_MY2020_Rx" SG_ 2611175493 PARSEDPhysSODCMCtoGWM_ECG 1;
BA_ "GenSigSendType" SG_ 2611175493 PARSEDPhysSODCMCtoGWM_ECG 3;
BA_ "U_CD542_MY2021_Tx" SG_ 2612224069 PARSEDPushSODCMCtoGWM 1;
BA_ "U_T6_MCA_MY2020_Tx" SG_ 2612224069 PARSEDPushSODCMCtoGWM 1;
BA_ "ECGUsedRxSignal" SG_ 2612224069 PARSEDPushSODCMCtoGWM 1;
BA_ "U_T6_MCA_MY2020_Rx" SG_ 2612224069 PARSEDPushSODCMCtoGWM 1;
BA_ "GenSigSendType" SG_ 2612224069 PARSEDPushSODCMCtoGWM 3;
VAL_ 1069 SlMde_D_Stat 3 "IsaNotConfigured" 2 "Manual_Mode" 1 "Auto_Mode" 0 "Null" ;
VAL_ 1069 SlMde_D_RqDsply 3 "NotUsed" 2 "ManualSpeed_LimiterSymbol" 1 "AutoSpeed_LimiterSymbol" 0 "NoSpeed_LimiterSymbol" ;
VAL_ 1069 IsaOffst_D_Stat 15 "Faulty" 14 "Null" 13 "Thirteen" 12 "Twelve" 11 "Eleven" 10 "Ten" 9 "Nine" 8 "Eight" 7 "Seven" 6 "Six" 5 "Five" 4 "Four" 3 "Three" 2 "Two" 1 "One" 0 "Zero" ;
VAL_ 1069 ReFuelSysStat_D_Dsply 7 "NotUsed3" 6 "NotUsed2" 5 "NotUsed1" 4 "Refuel_Err" 3 "Close_Fuel_Door" 2 "Refuel_Ready" 1 "Wait_To_Fuel" 0 "Null" ;
VAL_ 1069 ULoSrcOnPlg_B_Cmd 1 "Activate" 0 "Deactivate" ;
VAL_ 1069 EngOilMaint_B_Stat 1 "On" 0 "Off" ;
VAL_ 1069 GrllShtrPos_D_Cmd 15 "Fully_Open" 14 "Position14" 13 "Position13" 12 "Position12" 11 "Position11" 10 "Position10" 9 "Position9" 8 "Position8" 7 "Position7" 6 "Position6" 5 "Position5" 4 "Position4" 3 "Position3" 2 "Position2" 1 "Position1" 0 "Fully_Closed" ;
VAL_ 1069 GrllShtrPos_B_Falt 1 "Fault" 0 "No_Fault" ;
VAL_ 1069 ObdWarmUp_B_Complt 1 "Yes" 0 "No" ;
VAL_ 1069 EngMsgTxt_D_Rq 3 "Undefined_2" 2 "Undefined_1" 1 "Power_Reduced_to_LowerTemp" 0 "No_Message" ;
VAL_ 1069 EngAirIn_Te_Actl 1023 "Fault" 1022 "Unknown" ;
VAL_ 1069 TracKeyMdeEnbl_B_Stat 1 "On" 0 "Off" ;
VAL_ 1060 RearDiffOilTeWarn_B_Rq 1 "On" 0 "Off" ;
VAL_ 1060 EngExhMdeQuiet_D_Stat 3 "Faulty" 2 "QuietExhaust" 1 "LoudExhaust" 0 "Null" ;
VAL_ 1060 RearDiffOil_Te_Actl 511 "Faulty" ;
VAL_ 1060 BpedDrvMsgTxt_B_Dsply 1 "On" 0 "Off" ;
VAL_ 1060 FuelLvlWarn_D_ActlEng 7 "DteLevel5Lowest" 6 "DteLevel4" 5 "DteLevel3" 4 "DteLevel2NonMyKey" 3 "DteLevel1MyKey" 2 "VeryLow" 1 "Low" 0 "OK" ;
VAL_ 1060 SelDrvMdePt_D_Stat 0 "NotAvailable" 1 "Available" 2 "TemporarilyNotAvailable" 3 "Faulty" ;
VAL_ 1057 FohEng_D_Rq 3 "AutoEnable_ParkEnable" 2 "AutoDisable_ParkEnable" 1 "AutoEnable_ParkDisable" 0 "Disable_Stop" ;
VAL_ 1057 EngIdlShutDwnTxt_D_Rq 3 "NotUsed" 2 "EngineShutdownOnPrevDrive" 1 "FeatureDisabledDueToFault" 0 "NoMessage" ;
VAL_ 1057 EngIdlShutDown_D_Stat 3 "Not_used" 2 "Engine_Shutdown" 1 "Initiated_Countdown" 0 "Normal_Operation" ;
VAL_ 1057 FUEL_ALCOHOL_PERCNT 255 "Invalid" ;
VAL_ 1057 TrnTotTq_Rt_Est 65535 "Fault" 65534 "Unknown" ;
VAL_ 1057 TrnTotLss_Tq_Est 255 "Fault" 254 "Unknown" ;
VAL_ 1057 ECMMILRequest 3 "Not_Used" 2 "Flash" 1 "On" 0 "Off" ;
VAL_ 1057 AirCondFluidHi_P_Actl 255 "Fault" 254 "Unknown" ;
VAL_ 1057 OilPressureWarning 1 "Low_Pressure_Lamp_On" 0 "Normal_Pressure_Lamp_Off" ;
VAL_ 1057 VehVLimStat_D_Actl 7 "Undefined_3" 6 "Undefined_2" 5 "Undefined_1" 4 "ASL_Fault_Condition" 3 "Active_and_Limiting" 2 "Active_but_Not_Limiting" 1 "Standby" 0 "Off" ;
VAL_ 1057 VehVLimActv_B_Actl 1 "Active" 0 "Inactive" ;
VAL_ 1057 CoolantFanStepAct 31 "Unused7" 30 "Unused6" 29 "Unused5" 28 "Unused4" 27 "Unused3" 26 "Unused2" 25 "Unused1" 23 "Step23" 22 "Step22" 21 "Step21" 20 "Step20" 19 "Step19" 18 "Step18" 17 "Step17" 16 "Step16" 15 "Step15" 14 "Step14" 13 "Step13" 12 "Step12" 11 "Step11" 10 "Step10" 9 "Step9" 8 "Step8" 7 "Step7" 6 "Step6" 5 "Step5" 4 "Step4" 3 "Step3" 2 "Step2" 1 "Step1" 24 "Max_Fan_Speed_Req" 0 "Fan_Cmd_Off" ;
VAL_ 1055 EcoCochInstNeg_B_Dsply 1 "True" 0 "False" ;
VAL_ 562 GearNtrl_D_Stat 3 "Faulty" 2 "NoDataExists" 1 "Yes" 0 "No" ;
VAL_ 562 OnePdlDrv_D_Stat 3 "Enabled_BrkLampAndFbrk" 2 "Enabled_BrkLamp" 1 "Enabled_NoAction" 0 "Disabled" ;
VAL_ 523 EngAirFiltMsgTxt_D_Rq 7 "NotUsed_2" 6 "NotUsed_1" 5 "EngineAirFilterMonitorFalt" 4 "ResetComplete" 3 "Clogged" 2 "ReplaceNow" 1 "ReplaceSoon" 0 "NoMessage" ;
VAL_ 523 WaterInFuel_B_Falt 1 "Fault" 0 "No_Fault" ;
VAL_ 523 UreaMnAdd_L2_Actl 255 "Faulty" ;
VAL_ 523 UreaMxAdd_L2_Actl 511 "Faulty" ;
VAL_ 519 RearDiffLck_Tq_Rq 16383 "Faulty" 16382 "NoDataExists" ;
VAL_ 517 FapLc_B_Err 1 "Yes" 0 "No" ;
VAL_ 516 EngAoutNActl_D_QF 3 "OK" 2 "Not_Within_Specifications" 1 "No_Data_Exists" 0 "Faulty" ;
VAL_ 516 EngAout3_N_Actl 65535 "Invalid" ;
VAL_ 516 ApedPosPcActl_D_Qf 3 "OK" 2 "Not_Within_Specifications" 1 "No_Data_Exists" 0 "Faulty" ;
VAL_ 516 ApedPos_PcRate_ActlArb 255 "Fault" 254 "Unknown" ;
VAL_ 514 StrtrMtrDlyStrt_B_Stat 1 "Yes" 0 "No" ;
VAL_ 514 VehVTrlrAid_B_Avail 1 "Yes" 0 "No" ;
VAL_ 514 StrtrMtrCtlMsgTxt_D_Rq 7 "Start_In_Gear_Allowed" 6 "Pending_Start_Cancelled" 5 "Start_Pending_Please_Wait" 4 "Cranking_Limit_Exceeded" 3 "Press_Brk_and_Shift_to_P_N" 2 "Press_Clutch_and_Brake" 1 "Press_Clutch_To_Start" 0 "No_Display" ;
VAL_ 514 VehVActlEng_D_Qf 3 "OK" 2 "Not_Within_Specifications" 1 "No_Data_Exists" 0 "Faulty" ;
VAL_ 514 GearRvrse_D_Actl 7 "Fault" 6 "NotUsed_3" 5 "NotUsed_2" 4 "NotUsed_1" 3 "Active_confirmed" 2 "Active_not_confirmed" 1 "Inactive_confirmed" 0 "Inactive_not_confirmed" ;
VAL_ 514 StrtrMtrCtlMsgTxt_D2_Rq 3 "NoRequestPcmStartingMsgCtl" 2 "ShiftToNeutralToStart" 1 "ShiftToParkToStart" 0 "NoRequestBcmStartingMsgCtl" ;
VAL_ 512 PtDrvMde_D_Stat 15 "Faulty" 14 "NotUsed11" 13 "NotUsed10" 12 "NotUsed9" 11 "NotUsed8" 10 "NotUsed7" 9 "NotUsed6" 8 "NotUsed5" 7 "Drag" 6 "Rock" 5 "Baja" 4 "Sand" 3 "TowHaulGradeAssist" 2 "SnowWet" 1 "Sport" 0 "Normal" ;
VAL_ 382 EngMnfldChrg_Te_Actl 127 "Faulty" 126 "NoDataExists" ;
VAL_ 382 EngInnrClnt_Te_Actl 127 "Faulty" 126 "NoDataExists" ;
VAL_ 381 EngOilSrvcMsgTxt_D_Rq 7 "NotUsed3" 6 "NotUsed2" 5 "NotUsed1" 4 "ResetComplete" 3 "ResetInProgress" 2 "ChangeOilNow" 1 "ChangeOilSoon" 0 "NoText" ;
VAL_ 381 RunDryPrevent_B_Stat 1 "True" 0 "False" ;
VAL_ 381 WaterInFuel 1 "On" 0 "Off" ;
VAL_ 381 GlowIndication 1 "On" 0 "Off" ;
VAL_ 380 FuelMaintMde_D_Rq 3 "Feature_Not_Present" 2 "Fuel_Maint_Req_Now" 1 "Fuel_Maint_Req_Soon" 0 "NoRequest" ;
VAL_ 380 GrdAsstAllw_D_DsplyPt 3 "NotUsed" 2 "On" 1 "Off" 0 "NoModeSelected" ;
VAL_ 380 EngOilLvlWarn_D_Rq1 7 "Undefined_3" 6 "Undefined_2" 5 "Engine_Oil_Monitor_Fault" 3 "Engine_Oil_High" 2 "Engine_Oil_Critical_Low" 1 "Engine_Oil_Low" 0 "No_Message" 4 "Engine_Oil_Critical_High" ;
VAL_ 380 EngExhBrkOnLamp_B_Rq 1 "On" 0 "Off" ;
VAL_ 380 EngExhBrkAutoLamp_B_Rq 1 "On" 0 "Off" ;
VAL_ 380 EngExhBrkMde_D_Actl 6 "ExhBrkDisable_NoError" 5 "ExhBrkActive_AUTO" 4 "ExhBrkActive_ON" 3 "ExhBrkRequest_AUTO" 2 "ExhBrkRequest_ON" 1 "ExhBrkNoRequest_OFF" 0 "ExhBrkUnavailable_Error" ;
VAL_ 380 WhlRearDual_D_Stat 3 "NotUsed" 2 "Dual" 1 "Single" 0 "NoDataExists" ;
VAL_ 380 PwStep_D_DrvInhbt 3 "NotUsed" 2 "DriveInhibitMalfunction" 1 "DriveInhibited" 0 "DriveNotInhibited" ;
VAL_ 377 HvacAirFullOut_B_Rq 1 "Yes" 0 "No" ;
VAL_ 377 TrnManShif_D_IndDrv 7 "Undefined_3" 6 "Undefined_2" 5 "Shift_to_Neutral" 4 "Downshift_Recommendation" 3 "Upshift_Warning" 2 "Upshift_Performance" 1 "Upshift_Fuel_Economy" 0 "No_Indication" ;
VAL_ 377 TrnManShifGear_D_IndDrv 7 "Indicate_Reverse_Gear" 6 "Indicate_Gear6" 5 "Indicate_Gear5" 4 "Indicate_Gear4" 3 "Indicate_Gear3" 2 "Indicate_Gear2" 1 "Indicate_Gear1" 0 "No_Indication" ;
VAL_ 377 EngFuelCutFull_B_Inhbt 1 "Inhibit_DFSO" 0 "Normal" ;
VAL_ 377 EngDecelFuelCut_B_Allw 1 "Yes" 0 "No" ;
VAL_ 377 FuelFillInlet_B_Dsply 1 "Yes" 0 "No" ;
VAL_ 377 EngSrvcRqd_B_Rq 1 "Engine_Service_Required" 0 "No_engine_service_required" ;
VAL_ 377 OdoCount 255 "Invalid" ;
VAL_ 377 TrnKickDown_B_RqDrv 1 "Yes" 0 "No" ;
VAL_ 377 FuelFilterLamp_B_Dsply 1 "On" 0 "Off" ;
VAL_ 377 AirCondRec_B_Rq 1 "Yes" 0 "No" ;
VAL_ 377 AirCondClutch_B_Stats 1 "Yes" 0 "No" ;
VAL_ 377 EngAoutTqActl_D_Qf 3 "OK" 2 "Not_Within_Specifications" 1 "No_Data_Exists" 0 "Faulty" ;
VAL_ 376 GasPrtc_D_RqDsply 7 "NotUsed_5" 6 "NotUsed_4" 5 "NotUsed_3" 4 "NotUsed_2" 3 "NotUsed_1" 2 "GpfOverLimit" 1 "GpfAtLimit" 0 "NormalOperation" ;
VAL_ 376 LnchCtlSys_D_Stat 7 "NotUsed3" 6 "NotUsed2" 5 "NotUsed1" 4 "On_LC_Unavailable_TC_On" 3 "On_LC_Unavailable" 2 "On_LC_Available" 1 "On_LC_Active" 0 "LC_OFF" ;
VAL_ 376 DynoMde_B_Cmd 1 "DynomometerMode" 0 "NormalOperation" ;
VAL_ 376 AslChime_B_Rq 1 "Yes" 0 "No" ;
VAL_ 376 HvacHtrCore2_Te_Actl 1023 "Faulty" ;
VAL_ 376 PtcHtr_D_Cmd 3 "TurnOn" 2 "AutoMode" 1 "TurnOff" 0 "NoDecision_Initializing" ;
VAL_ 376 EcssLamp_D_RqDsply 3 "Not_Used" 2 "Flash" 1 "On" 0 "Off" ;
VAL_ 376 AirAmbTe_D_Qf 3 "OK" 2 "Not_Within_Specifications" 1 "No_Data_Exists" 0 "Faulty" ;
VAL_ 376 AirAmb_P_Actl 63 "Fault" 62 "NoDataExists" ;
VAL_ 376 AslIconDsply_D_Rq 3 "On_Passive_Overridden" 2 "On_Active" 1 "On_Passive" 0 "Off" ;
VAL_ 373 DieslPrtc2_D_RqDsply 15 "NotUsed4" 14 "NotUsed3" 13 "NotUsed2" 12 "NotUsed1" 11 "OCR_ExhFilterClean_Stopped" 10 "OCR_ExhFilterCleaned" 9 "RgnOff_AtLimit" 8 "RgnOff_Overloaded" 7 "RgnOff_Loaded" 6 "Exhaust_Filter_Full" 5 "DPF_Overlimit" 4 "DPF_AtLimit" 3 "ExhFilter_Drive_Completed" 2 "Cleaning_Exhaust_Filter" 1 "DPF_Overloaded" 0 "DPF_Normal_Operation" ;
VAL_ 373 DieslPrtc_D_RqDsply 7 "Unused_2" 6 "Unused_1" 5 "DPF_SOOT_Level3_Blocked" 4 "DPFSootLvl2_SevereOverload" 3 "DPFRegen_ExhFilterComplete" 2 "DPFRegen_CleanExhFilter" 1 "DPF_Soot_Level1_Overloaded" 0 "DPF_OK_Normal_Operation" ;
VAL_ 373 DieslPrtcRgen_D_Actl 3 "Undefined" 2 "Regen_Level_2" 1 "Regen_Level_1" 0 "No_regen" ;
VAL_ 373 DieslPrtcRgen_D_Rq 7 "Unused_2" 6 "Unused_1" 5 "Full_Regen_2" 4 "Full_Regen_1" 3 "HeatUp_3" 2 "HeatUp_2" 1 "HeatUp_1" 0 "Normal_Mode_NoRegen" ;
VAL_ 373 EngFuelCutFull_B_Allw 1 "Yes" 0 "No" ;
VAL_ 373 EngTurboMde_D_Actl 3 "Fault" 2 "One_Turbo_Active" 1 "Two_Turbos_Active" 0 "Initializing" ;
VAL_ 373 EngTeColdPrtct_D_Stats 3 "Engine_Warm_RdcPwr" 2 "OK_to_Drive" 1 "Engine_Warm_PlsWait" 0 "Normal_Operation" ;
VAL_ 373 EngExhOvrTe_B_RqDsply 1 "Active" 0 "Inactive" ;
VAL_ 373 EngPtoMde_D_Rq 7 "Undefined" 6 "Split_Shaft_Stationary" 5 "Not_Used_2" 4 "PTO_Mobile" 3 "Not_Used_1" 2 "PTO_Stationary" 1 "BCP" 0 "Off" ;
VAL_ 372 TrnAinTqDtrb_B_Actl 1 "Active" 0 "Inactive" ;
VAL_ 359 PrplWhlRgenMn_Tq_Actl 8191 "Faulty" ;
VAL_ 359 ElPw_D_StatStrtStop 15 "NotUsed6" 14 "NotUsed5" 13 "NotUsed4" 12 "NotUsed3" 11 "NotUsed2" 10 "NotUsed1" 9 "Supported_Level_4" 8 "Supported_Level_3" 7 "Supported_Level_2" 6 "Supported_Level_1" 5 "Limited_Support" 4 "Fault_Limited" 3 "LV_Event_in_Progress" 2 "Not_Supported_Imminent" 1 "Supported_All" 0 "Not_Supported" ;
VAL_ 359 PrplWhlTot2_Tq_Actl 65535 "Fault" 65534 "NoDataExists" ;
VAL_ 359 LscmbbDeny_B_ActlPrpl 1 "Denied" 0 "Allowed" ;
VAL_ 359 LscmbbEngTqMn_B_Actl 1 "Engine_Braking_Activated" 0 "Engine_Braking_Off" ;
VAL_ 359 PwPckTq_D_Stat 3 "PwPckOn_TqAvailable" 2 "StartInPrgrss_TqNotAvail" 1 "PwPckOn_TqNotAvailable" 0 "PwPckOff_TqNotAvailable" ;
VAL_ 359 Eng_D_Stat 3 "NotUsed" 2 "EngAutoStopped" 1 "EngOn" 0 "EngOff" ;
VAL_ 359 PlgActvArb_B_Actl 1 "On" 0 "Off" ;
VAL_ 359 ElPw_D_Stat 7 "NotUsed_3" 6 "NotUsed_2" 5 "NotUsed_1" 4 "Fault_Limited" 3 "LV_Event_In_Progress" 2 "Not_Supported_Imminent" 1 "Supported" 0 "Not_Supported" ;
VAL_ 359 TrnAinTq_D_Qf 3 "OK" 2 "Not_Within_Specifications" 1 "No_Data_Exists" 0 "Faulty" ;
VAL_ 358 StopStrtStdby_D_Indic 6 "NotUsed2" 5 "Telltale_Struck_Out" 4 "Telltale_Flashing_Amber" 3 "Telltale_On_Amber" 2 "Telltale_Flashing_Green" 1 "Telltale_On_Green" 0 "Telltale_Off" 7 "NotUsed3" ;
VAL_ 358 StopStrtIODTxt_D_Rq 31 "Message31" 30 "Message30" 29 "Message29" 28 "Message28" 27 "Message27" 26 "Message26" 25 "Message25" 24 "Message24" 23 "Message23" 22 "Message22" 21 "Message21" 20 "Message20" 19 "Message19" 18 "Message18" 17 "Message17" 16 "Message16" 15 "Message15" 14 "Message14" 13 "Message13" 12 "Message12" 11 "Message11" 10 "Message10" 9 "Message9" 8 "Message8" 7 "Message7" 6 "Message6" 5 "Message5" 4 "Message4" 3 "Message3" 2 "Message2" 1 "Message1" 0 "NoMessage" ;
VAL_ 358 StopStrtDrvMde_D_Indic 3 "NotUsed" 2 "StartStop_IndirectDeselect" 1 "StopStart_Deselected" 0 "StopStart_Selected" ;
VAL_ 358 StopStrtMsgTxt_D_Rq 15 "Message_15" 14 "Message_14" 13 "Message_13" 12 "Message_12" 11 "Message_11" 10 "Message_10" 9 "Message_9" 8 "Message_8" 7 "Message_7" 6 "Message_6" 5 "Message_5" 4 "Message_4" 3 "Message_3" 2 "Message_2" 1 "Message_1" 0 "NoMessage" ;
VAL_ 358 OdoTripVerify_L_Actl 16777215 "Fault" ;
VAL_ 358 HiElPwInhbt_B_Stat 1 "Inhibit" 0 "No_Inibit" ;
VAL_ 358 AutoStopPtDelta_I_Est 255 "Fault" ;
VAL_ 357 BPedDrvAppl_D_QF 3 "OK" 2 "Not_Within_Specifications" 1 "No_Data_Exists" 0 "Faulty" ;
VAL_ 357 CmbbDeny_B_ActlPrpl 1 "Yes" 0 "No" ;
VAL_ 357 PrplTqMnSat_B_Actl 1 "Yes" 0 "No" ;
VAL_ 357 VehStrtStop_D_Rq 3 "NotUsed" 2 "Vehicle_Start_Request" 1 "Vehicle_Stop_Request" 0 "NoRequest" ;
VAL_ 357 BpedDrvAppl_D_Actl 3 "_Not_Allowed" 2 "Driver_Braking" 1 "Driver_Not_Braking" 0 "Not_Allowed" ;
VAL_ 357 CmbbEngTqMn_B_Actl 1 "Yes" 0 "No" ;
VAL_ 357 Veh_V_DsplyCcSet 255 "Fault" 254 "Unknown" ;
VAL_ 357 AccEngStat_D_Actl 7 "Undefined_2" 6 "Undefined_1" 5 "ACCSoonCancel_due_Low_Spd" 4 "Shift_Down_Recommendation" 3 "Shift_Up_Recommendation" 2 "ACCNotAllowedToBeActivated" 1 "ACCStandby_due_Auto_Cancel" 0 "Normal_Operation" ;
VAL_ 357 CcMde_D_Actl 7 "TapDownWaiting" 6 "TapUpWaiting" 5 "Resuming_Low" 4 "Resuming_High" 3 "Decelerating" 2 "Accelerating" 1 "Keeping_Speed" 0 "Not_Active" ;
VAL_ 357 CcStat_D_Actl 7 "Undefined_2" 6 "Undefined_1" 5 "Active" 4 "Active_Que_Assist" 3 "Standby" 2 "Standby_Denied" 1 "Denied" 0 "Off" ;
VAL_ 357 CcOvrrdActv_B_Actl 1 "Cruise_Overridden" 0 "Cruise_Req_Not_Overridden" ;
VAL_ 357 AccStopMde_D_Rq 3 "Stop_Mode_Active" 2 "EPBApplyOrBrakeReleaseWarn" 1 "Limit_Rolling_Speed" 0 "Stop_Mode_Not_Active" ;
VAL_ 355 AutoRgenTxt_B_RqDsply 1 "AutExhFilterCleanOFF" 0 "AutExhFilterCleanON" ;
VAL_ 355 AccFllwMdeActv_B_Actl 1 "Active" 0 "Inactive" ;
VAL_ 355 EngPtoMde_D_Actl 7 "Undefined" 6 "Split_Shaft_Stationary" 5 "Not_Used_2" 4 "PTO_Mobile" 3 "Not_Used_1" 2 "PTO_Stationary" 1 "BCP" 0 "Off" ;
VAL_ 355 ManRgenVeh_V_MinAllw 127 "Fault" ;
VAL_ 355 ManRgenTxt_D_RqDsply 7 "NotUsed3" 6 "NotUsed2" 5 "NotUsed1" 4 "Cleaning_Aborted_Stopped" 3 "Cleaning_Completed" 2 "Cleaning_In_Progress" 1 "Cleaning_Allowed" 0 "Cleaning_Not_Allowed" ;
VAL_ 355 ManRgenSoot_Pc_RqDsply 127 "Fault" ;
VAL_ 355 ManRgenInhbt_T_RqDsply 65535 "Fault" ;
VAL_ 355 ManRgenInhbt_Pc_Soot 127 "Fault" ;
VAL_ 355 ManRgenInhbt_L_RqDsply 65535 "Fault" ;
VAL_ 355 DieslMsgTxt_D_Rq 3 "NotUsed2" 2 "NotUsed1" 1 "ReducedEnginePower" 0 "NoMessage" ;
VAL_ 342 HtrLoop_B_Stat 1 "Fault" 0 "No_Fault" ;
VAL_ 342 TqmTerrMdeChng_D_Rdy 7 "Fault" 6 "Undefined_2" 5 "Undefined_1" 4 "ModeUnavailDrInputRqd" 3 "SpOpModes_NotSupported" 2 "ModeUnavailDynamicCond" 1 "Module_In_Initialization" 0 "Mode_Change_Available" ;
VAL_ 342 TqmTerrMde_D_Actl 7 "Fail_Safe_Default" 6 "Dynamic_Mode" 5 "Rock_Crawl_Mode" 4 "Mud_Ruts_Mode" 3 "Sand_Mode" 2 "Undefined" 1 "Low_Mu_Mode" 0 "Special_Operating_Mode_Off" ;
VAL_ 342 EngOvrhtMitgActv_D_Ind 3 "Undefined" 2 "Mode2" 1 "Mode1" 0 "Normal_Mode" ;
VAL_ 342 EngClntTe_D_Qf 3 "OK" 2 "Not_Within_Specifications" 1 "No_Data_Exists" 0 "Faulty" ;
VAL_ 342 EngAcsyArcPmp_Tq_Actl 255 "Fault" 254 "Unknown" ;
VAL_ 342 EngOilLvlDsply_D_Rq 15 "EngOil_LevelSys_CheckFault" 14 "Reserved_2" 13 "Reserved_1" 12 "Conditions_Unsuitable" 11 "Dipstick_Below_Minimum" 10 "Dipstick_Above_Maximum" 9 "Dipstick_Minimum" 8 "Dipstick_12_5_MinMaxRange" 7 "Dipstick_25_MinMaxRange" 6 "Dipstick_37_5_MinMaxRange" 5 "Dipstick_50_MinMaxRange" 4 "Dipstick_62_5_MinMaxRange" 3 "Dipstick_75_MinMaxRange" 2 "Dipstick_87_5_MinMaxRange" 1 "Dipstick_Maximum_Displayed" 0 "No_Message" ;
VAL_ 342 EngOil_Te_Actl 255 "Fault" 254 "Unknown" ;
VAL_ 71 immoTarget1Status 7 "Unused4" 6 "Unused3" 5 "Unused2" 4 "ENABLED_LIMITEDMOTIVE_STAR" 3 "DISABLED_RESET   " 2 "ENABLED_NONMOTIVE_START" 1 "ENABLED_MOTIVE_START" 0 "DISABLED" ;
VAL_ 71 immoTarget1Cmd 7 "Unused4" 6 "Unused3" 5 "Unused2" 4 "Unused1" 3 "TARGET1_IDBLOCK2" 2 "TARGET1_IDBLOCK1" 1 "CHALLENGE" 0 "IDLE" ;
VAL_ 824 DteCldTrlrOn_B_Stat 1 "Yes" 0 "No" ;
VAL_ 824 DteCldTrlrOff_B_Stat 1 "Yes" 0 "No" ;
VAL_ 824 DteCldTraffic_B_Stat 1 "Yes" 0 "No" ;
VAL_ 824 DteCldTerrain_B_Stat 1 "Yes" 0 "No" ;
VAL_ 824 DteCldRoute_B_Stat 1 "Yes" 0 "No" ;
VAL_ 824 DteCldPayload_B_Stat 1 "Yes" 0 "No" ;
VAL_ 824 DteCldExtTe_B_Stat 1 "Yes" 0 "No" ;
VAL_ 824 DteCldDcac_B_Stat 1 "Yes" 0 "No" ;
VAL_ 824 DteCldTrip_L2_Actl 8191 "Faulty" 8190 "NoDataExists" ;
VAL_ 823 DteAcceptNew_B_Rq 1 "Yes" 0 "No" ;
VAL_ 811 SpeedoMajorUnit_D_Confg 3 "NotUsed" 2 "Kph" 1 "Mph" 0 "Null" ;
VAL_ 811 ScMnSoc_Pc_RqMnu 127 "Faulty" 126 "NoDataExists" ;
VAL_ 811 ScEnbl_D_RqMnu 3 "NotUsed" 2 "On" 1 "Off" 0 "Null" ;
VAL_ 811 OnePdlDrvButtn_B_Falt 1 "Faulted" 0 "NotFaulted" ;
VAL_ 811 OnePdlDrvButtn_B_Stat 1 "Pressed" 0 "Not_Pressed" ;
VAL_ 811 DistToStopover_L_Actl 65535 "Faulty" ;
VAL_ 811 StopoverType_D_Stat 7 "Faulty" 6 "NotUsed_1" 5 "Other" 4 "Work" 3 "Home" 2 "ChargeStation" 1 "FinalDestination" 0 "Null" ;
VAL_ 811 ExtLghtDsply_D_Stat 7 "NotUsed" 6 "PressToOn3" 5 "PressToOff3" 4 "PressToOn2" 3 "PressToOff2" 2 "PressToOn1" 1 "PressToOff1" 0 "Reset" ;
VAL_ 811 ExtLghtRight_D_RqMnu 7 "NotUsed" 6 "PressToOn3" 5 "PressToOff3" 4 "PressToOn2" 3 "PressToOff2" 2 "PressToOn1" 1 "PressToOff1" 0 "Reset" ;
VAL_ 811 AutoLghtOvrrd_B_RqDrv 1 "Allowed" 0 "NotAllowed" ;
VAL_ 811 ExtLghtRear_D_RqMnu 7 "NotUsed" 6 "PressToOn3" 5 "PressToOff3" 4 "PressToOn2" 3 "PressToOff2" 2 "PressToOn1" 1 "PressToOff1" 0 "Reset" ;
VAL_ 811 LongTermReset_B_RqMnu 1 "On" 0 "Off" ;
VAL_ 811 ExtLghtLeft_D_RqMnu 7 "NotUsed" 6 "PressToOn3" 5 "PressToOff3" 4 "PressToOn2" 3 "PressToOff2" 2 "PressToOn1" 1 "PressToOff1" 0 "Reset" ;
VAL_ 811 ExtLghtFront_D_RqMnu 7 "NotUsed" 6 "PressToOn3" 5 "PressToOff3" 4 "PressToOn2" 3 "PressToOff2" 2 "PressToOn1" 1 "PressToOff1" 0 "Reset" ;
VAL_ 811 GoTEditMnte_T_RqMnu 15 "Faulty" 14 "NoDataExists" 13 "NotUsed_2" 12 "NotUsed_1" 11 "Minute_55" 10 "Minute_50" 9 "Minute_45" 8 "Minute_40" 7 "Minute_35" 6 "Minute_30" 5 "Minute_25" 4 "Minute_20" 3 "Minute_15" 2 "Minute_10" 1 "Minute_5" 0 "Minute_0" ;
VAL_ 811 GoTEditHr_T_RqMnu 31 "Faulty" 30 "NoDataExists" ;
VAL_ 785 EcoIdl_D_Stat 3 "NotUsed" 2 "Enabled" 1 "Disabled" 0 "Null" ;
VAL_ 785 DteVehOffst_L_Dsply 8191 "Faulty" 8190 "NoDataExists" ;
VAL_ 785 DteVehOffstMsgTxt_D_Rq 15 "NotUsed_7" 14 "NotUsed_6" 13 "NotUsed_5" 12 "NotUsed_4" 11 "NotUsed_3" 10 "NotUsed_2" 9 "NotUsed_1" 8 "PowerToTheBox" 7 "Payload" 6 "TrailerTowing_Off" 5 "TrailerTowing_On" 4 "TrafficAlongRoute" 3 "ExternalTemperature" 2 "HillyTerrain" 1 "DestinationRoute" 0 "NoMessage" ;
VAL_ 785 PwPckTqRdyChime_B_Rq 3 "NotUsed" 2 "Shutdown" 1 "Startup" 0 "Null" ;
VAL_ 785 BattTracLoThres_D_Stat 7 "NotUsed" 6 "Thres80km_50mi" 5 "Thres50km_31mi" 4 "Thres30km_18mi" 3 "Thres50mi_80km" 2 "Thres30mi_48km" 1 "Thres20mi_32km" 0 "Null" ;
VAL_ 785 BattTracLoMsgTxt_D_Rq 7 "NotUsed_2" 6 "NotUsed_1" 5 "ZeroDteBatteryDepleted" 4 "ClimateLowDteSecondAlert" 3 "ClimateLowDteFirstAlert" 2 "LowDteSecondAlert" 1 "LowDteFirstAlert" 0 "Null" ;
VAL_ 785 BattTracLoSoc_D_Dsply 3 "NotUsed" 2 "ZeroDteDepletedBattery" 1 "LoDte" 0 "Null" ;
VAL_ 770 ScPayloadUpdate_B_Stat 3 "NotUsed" 2 "Complete" 1 "InProcess" 0 "Null" ;
VAL_ 770 ScChrgrPwMax_Pw_Actl 4095 "Faulty" ;
VAL_ 770 ScEnbl_B_Stat 1 "On" 0 "Off" ;
VAL_ 1205 CstmDrvMdeCfg2_B_Avail 1 "Available" 0 "NotAvailable" ;
VAL_ 1205 CstmDrvMdeCfg1_B_Avail 1 "Available" 0 "NotAvailable" ;
VAL_ 942 PrkAidAcsyRear_D_Stat 3 "NotUsed" 2 "On" 1 "Off" 0 "Null" ;
VAL_ 942 PrkAidAcsyFront_D_Stat 3 "NotUsed" 2 "On" 1 "Off" 0 "Null" ;
VAL_ 942 PrkAidDrvDir_D_Stat 7 "NotUsed_2" 6 "NotUsed_1" 5 "BackwardNegative" 4 "ForwardNegative" 3 "BackwardPositive" 2 "ForwardPositive" 1 "NoMotion" 0 "DirectionNotKnown" ;
VAL_ 123 BattTrac_U2_Actl 4095 "Faulty" 4094 "NoDataExists" ;
VAL_ 123 BattTrac_I2_Actl 262143 "Faulty" 262142 "NoDataExists" ;
VAL_ 1053 BattAuxCnnct_D_Cmd 7 "NotUsed_3" 6 "NotUsed_2" 5 "NotUsed_1" 4 "WeldCheck" 3 "OkToDischarge" 2 "Closed" 1 "Precharge" 0 "Open" ;
VAL_ 1201 FrontDiffLck_D_RqDrv2 3 "Faulty" 2 "NoRequest" 1 "On" 0 "Off" ;
VAL_ 1201 RearDiffLck_D_RqDrv2 3 "Faulty" 2 "NoRequest" 1 "On" 0 "Off" ;
VAL_ 1201 DrvSlipCtlMde_B_Rq5 1 "Pressed" 0 "Not_Pressed" ;
VAL_ 1201 StabBarCnncButtn_D_Sta2 3 "Faulty" 2 "NotUsed" 1 "Pressed" 0 "Not_Pressed" ;
VAL_ 1201 OrtaSwtch_D_Stat 3 "Faulty" 2 "NotUsed" 1 "Pressed" 0 "Not_Pressed" ;
VAL_ 949 Tire_Press_RR_ORR_Data 65535 "Not_Supported" 65534 "Invalid" 65533 "Unknown" ;
VAL_ 949 Tire_Press_LR_OLR_Data 65535 "Not_Supported" 65534 "Invalid" 65533 "Unknown" ;
VAL_ 949 Tire_Press_LF_Data 65535 "Not_Supported" 65534 "Invalid" 65533 "Unknown" ;
VAL_ 949 Tire_Press_RF_Data 65535 "Not_Supported" 65534 "Invalid" 65533 "Unknown" ;
VAL_ 639 OfbChrgPrflUpdate_B_Rq 1 "Request" 0 "NoRequest" ;
VAL_ 639 OfbChrgClearAll_B_Rq 1 "Request" 0 "NoRequest" ;
VAL_ 639 OfbChrgGoTTouch_D_Rq 3 "NotUsed" 2 "On" 1 "Off" 0 "Null" ;
VAL_ 639 OfbChrgGoTPrcond_D_Rq 3 "High" 2 "Medium" 1 "Low" 0 "Off" ;
VAL_ 639 OfbChrgGoTOn_D_Rq 3 "NotUsed" 2 "On" 1 "Off" 0 "Null" ;
VAL_ 639 OfbChrgGoTMnte_D_Rq 15 "NotUsed_4" 14 "NotUsed_3" 13 "NotUsed_2" 12 "NotUsed_1" 11 "Minute_55" 10 "Minute_50" 9 "Minute_45" 8 "Minute_40" 7 "Minute_35" 6 "Minute_30" 5 "Minute_25" 4 "Minute_20" 3 "Minute_15" 2 "Minute_10" 1 "Minute_5" 0 "Minute_0" ;
VAL_ 639 OfbChrgGoTHr_T_Rq 31 "Faulty" 30 "NoDataExists" ;
VAL_ 639 OfbChrgGoTExtHtr_D_Rq 3 "NotUsed" 2 "On" 1 "Off" 0 "Null" ;
VAL_ 639 OfbChrgGoTDelete_B_Rq 1 "Request" 0 "NoRequest" ;
VAL_ 639 OfbChrgGoTUpdate_B_Rq 1 "Request" 0 "NoRequest" ;
VAL_ 530 OfbChrgToPcWknd_D_Actl 7 "Percent_50" 6 "Percent_60" 5 "Percent_70" 4 "Percent_80" 3 "Percent_85" 2 "Percent_90" 1 "Percent_95" 0 "Percent_100" ;
VAL_ 530 OfbChrgToPcWkdy_D_Actl 7 "Percent_50" 6 "Percent_60" 5 "Percent_70" 4 "Percent_80" 3 "Percent_85" 2 "Percent_90" 1 "Percent_95" 0 "Percent_100" ;
VAL_ 530 OfbChrgSetNow_D_Rq 3 "NotUsed" 2 "On" 1 "Off" 0 "Null" ;
VAL_ 530 OfbChrgSetDelete_B_Rq 1 "Request" 0 "NoRequest" ;
VAL_ 530 OfbChrgLocIdUns_B_Rq 1 "Request" 0 "NoRequest" ;
VAL_ 550 PtWakeupActv1_B_Rq 1 "Wake_up_Powertrain_via_HW" 0 "Don_t_Wake_Up_Powertrain" ;
VAL_ 879 WndwRearHeat_I_Actl 2047 "Faulty" ;
VAL_ 879 WndwRearHeat_D_Stat 7 "NotUsed" 6 "FetLiftLimitReached" 5 "FetOpenCircuit" 4 "FetOutputShortToPower" 3 "FetOutputShortToGround" 2 "FetNotControlled" 1 "OnPowerToLoad" 0 "OffNoPowerToLoad" ;
VAL_ 885 BattULoChrg_D_RqOta 1 "Yes" 0 "No" ;
VAL_ 885 VehStrtInhbt_D_Dsply 15 "NotUsed_12" 14 "NotUsed_11" 13 "NotUsed_10" 12 "NotUsed_9" 11 "NotUsed_8" 10 "NotUsed_7" 9 "NotUsed_6" 8 "NotUsed_5" 7 "NotUsed_4" 6 "NotUsed_3" 5 "NotUsed_2" 4 "OtaSuccess" 3 "PostOtaActivatePermFail" 2 "PostOtaActivateWarning" 1 "DuringOtaActivate" 0 "NoMessage" ;
VAL_ 885 VehOnRqstr_D_Stat 11 "NotUsed_8" 10 "NotUsed_7" 9 "NotUsed_6" 8 "NotUsed_5" 7 "NotUsed_4" 6 "NotUsed_3" 5 "NotUsed_2" 4 "NotUsed_1" 3 "FleetVehInhbt" 2 "StolenVehInhbt" 1 "OverTheAir" 0 "NoRequestor" 15 "NotUsed_12" 14 "NotUsed_11" 13 "NotUsed_10" 12 "NotUsed_9" ;
VAL_ 885 VehStrtInhbt_D_RqCld 3 "NotUsed" 2 "On" 1 "Off" 0 "Null" ;
VAL_ 885 VehOn_D_RqCld 3 "NoControl" 2 "On" 1 "Off" 0 "Null" ;
VAL_ 885 OtaActv_D_Stat 15 "NotUsed_10" 14 "NotUsed_9" 13 "NotUsed_8" 12 "NotUsed_7" 11 "NotUsed_6" 10 "NotUsed_5" 9 "NotUsed_4" 8 "NotUsed_3" 7 "NotUsed_2" 6 "NotUsed_1" 5 "NonInterruptible_Pending" 4 "NonInterruptible_Config" 3 "NonInterruptible_ER" 2 "NonInterruptible_AB" 1 "Interruptible_AB" 0 "NoInVehicleOta" ;
VAL_ 979 LatCtlRampType_D_Rq 3 "Immediately" 2 "Fast" 1 "Medium" 0 "Slow" ;
VAL_ 979 LatCtlPrecision_D_Rq 3 "NotUsed2" 2 "NotUsed1" 1 "Precise" 0 "Comfortable" ;
VAL_ 979 LatCtl_D_Rq 7 "NotUsed4" 6 "NotUsed3" 5 "NotUsed2" 4 "NotUsed1" 3 "InterventionRight" 2 "InterventionLeft" 1 "ContinuousPathFollowing" 0 "NoLateralControl" ;
VAL_ 979 HandsOffCnfm_B_Rq 1 "Active" 0 "Inactive" ;
VAL_ 739 Partial_Amp_Shutdown 1 "Active" 0 "Inactive" ;
VAL_ 739 HMI_HMIMode_St 7 "NotUsed2" 6 "NotUsed1" 5 "Load_Shed_Active" 0 "Invalid" 1 "OffMode" 2 "On" 3 "Phone" 4 "Climate" ;
VAL_ 1160 DgtlCommPncReset_B_Req 1 "Yes" 0 "No" ;
VAL_ 1160 DgtlCommPnc_D_Rq 3 "NotUsed" 2 "Disable" 1 "Reset" 0 "NoRequest" ;
VAL_ 1160 DataMntrSustn_B_Rq 1 "Active" 0 "Inactive" ;
VAL_ 1160 PwSustnRdata_B_RqTelem 1 "Active" 0 "Inactive" ;
VAL_ 1001 AirSuspMsgTxt_D_Rq2 3 "NotUsed" 2 "Faulty" 1 "Override" 0 "NoMessage" ;
VAL_ 1001 PersIndexSuma_D_Actl 7 "Unused_3" 6 "Unused_2" 5 "Unused_1" 4 "Vehicle" 3 "PERS_4" 2 "PERS_3" 1 "PERS_2" 0 "PERS_1" ;
VAL_ 1077 AirSuspLoading_D_Stat 7 "Faulty" 6 "MeasurementInProgress" 5 "Overload_2" 4 "Overload_1" 3 "FullyLoaded" 2 "MediumLoaded" 1 "LightLoaded" 0 "LoadNotDetermined" ;
VAL_ 1077 AirSprngRear_P_Actl 4095 "Faulty" ;
VAL_ 1077 AirSprngRear_M_Actl 4095 "Faulty" ;
VAL_ 1077 AirSprngFront_P_Actl 4095 "Faulty" ;
VAL_ 1077 AirSprngFront_M_Actl 4095 "Faulty" ;
VAL_ 945 KeyPadCodeDgt7_D_Dsply 15 "NotUsed_4" 14 "NotUsed_3" 13 "NotUsed_2" 12 "NotUsed_1" 11 "Button7_8and9_0" 10 "Button0" 9 "Button9_0or9" 8 "Button8" 7 "Button7_8or7" 6 "Button6" 5 "Button5_6or5" 4 "Button4" 3 "Button3_4or3" 2 "Button2" 1 "Button1_2or1" 0 "EndofString" ;
VAL_ 945 KeyPadCodeDgt6_D_Dsply 15 "NotUsed_4" 14 "NotUsed_3" 13 "NotUsed_2" 12 "NotUsed_1" 11 "Button7_8and9_0" 10 "Button0" 9 "Button9_0or9" 8 "Button8" 7 "Button7_8or7" 6 "Button6" 5 "Button5_6or5" 4 "Button4" 3 "Button3_4or3" 2 "Button2" 1 "Button1_2or1" 0 "EndofString" ;
VAL_ 945 KeyPadCodeDgt5_D_Dsply 15 "NotUsed_4" 14 "NotUsed_3" 13 "NotUsed_2" 12 "NotUsed_1" 11 "Button7_8and9_0" 10 "Button0" 9 "Button9_0or9" 8 "Button8" 7 "Button7_8or7" 6 "Button6" 5 "Button5_6or5" 4 "Button4" 3 "Button3_4or3" 2 "Button2" 1 "Button1_2or1" 0 "EndofString" ;
VAL_ 945 KeyPadCodeDgt4_D_Dsply 15 "NotUsed_4" 14 "NotUsed_3" 13 "NotUsed_2" 12 "NotUsed_1" 11 "Button7_8and9_0" 10 "Button0" 9 "Button9_0or9" 8 "Button8" 7 "Button7_8or7" 6 "Button6" 5 "Button5_6or5" 4 "Button4" 3 "Button3_4or3" 2 "Button2" 1 "Button1_2or1" 0 "EndofString" ;
VAL_ 945 KeyPadCodeDgt3_D_Dsply 15 "NotUsed_4" 14 "NotUsed_3" 13 "NotUsed_2" 12 "NotUsed_1" 11 "Button7_8and9_0" 10 "Button0" 9 "Button9_0or9" 8 "Button8" 7 "Button7_8or7" 6 "Button6" 5 "Button5_6or5" 4 "Button4" 3 "Button3_4or3" 2 "Button2" 1 "Button1_2or1" 0 "EndofString" ;
VAL_ 945 KeyPadCodeDgt2_D_Dsply 15 "NotUsed_4" 14 "NotUsed_3" 13 "NotUsed_2" 12 "NotUsed_1" 11 "Button7_8and9_0" 10 "Button0" 9 "Button9_0or9" 8 "Button8" 7 "Button7_8or7" 6 "Button6" 5 "Button5_6or5" 4 "Button4" 3 "Button3_4or3" 2 "Button2" 1 "Button1_2or1" 0 "EndofString" ;
VAL_ 945 KeyPadCodeDgt1_D_Dsply 15 "NotUsed_4" 14 "NotUsed_3" 13 "NotUsed_2" 12 "NotUsed_1" 11 "Button7_8and9_0" 10 "Button0" 9 "Button9_0or9" 8 "Button8" 7 "Button7_8or7" 6 "Button6" 5 "Button5_6or5" 4 "Button4" 3 "Button3_4or3" 2 "Button2" 1 "Button1_2or1" 0 "EndofString" ;
VAL_ 945 KeyOffMde_D_Actl 15 "NotUsed_11" 14 "NotUsed_10" 13 "NotUsed_9" 12 "NotUsed_8" 11 "NotUsed_7" 10 "NotUsed_6" 9 "NotUsed_5" 8 "NotUsed_4" 7 "NotUsed_3" 6 "NotUsed_2" 5 "NotUsed_1" 4 "CriticalBattery" 3 "Hibernate" 2 "Transport" 1 "Factory" 0 "Normal" ;
VAL_ 945 PrkLckCtlLatch_B_Rq 1 "On" 0 "Off" ;
VAL_ 771 ScDayOfWeekId_D_Stat 7 "Sunday" 6 "Saturday" 5 "Friday" 4 "Thursday" 3 "Wednesday" 2 "Tuesday" 1 "Monday" 0 "NotUsed" ;
VAL_ 771 ScChrgDurSet_B_Stat 1 "On" 0 "Off" ;
VAL_ 777 ScLocSaved_B_Dsply 1 "Yes" 0 "No" ;
VAL_ 777 ScLocLongPostv_B_Stat 1 "Yes" 0 "No" ;
VAL_ 777 ScLocLattPostv_B_Stat 1 "Yes" 0 "No" ;
VAL_ 1043 SelDrvMdeHmi02_D_Rq 31 "Faulty" 30 "SelDrvMde31" 29 "SelDrvMde30" 28 "SelDrvMde29" 27 "SelDrvMde28" 26 "SelDrvMde27" 25 "SelDrvMde26" 24 "SelDrvMde25" 23 "SelDrvMde24" 22 "SelDrvMde23" 21 "SelDrvMde22" 20 "SelDrvMde21" 19 "SelDrvMde20" 18 "SelDrvMde19" 17 "SelDrvMde18" 16 "SelDrvMde17" 15 "SelDrvMde16" 14 "SelDrvMde15" 13 "SelDrvMde14" 12 "SelDrvMde13" 11 "SelDrvMde12" 10 "SelDrvMde11" 9 "SelDrvMde10" 8 "SelDrvMde09" 7 "SelDrvMde08" 6 "SelDrvMde07" 5 "SelDrvMde06" 4 "SelDrvMde05" 3 "SelDrvMde04" 2 "SelDrvMde03" 1 "SelDrvMde02" 0 "SelDrvMde01" ;
VAL_ 1043 SelDrvMdeHmi04_D_Rq 31 "Faulty" 30 "SelDrvMde31" 29 "SelDrvMde30" 28 "SelDrvMde29" 27 "SelDrvMde28" 26 "SelDrvMde27" 25 "SelDrvMde26" 24 "SelDrvMde25" 23 "SelDrvMde24" 22 "SelDrvMde23" 21 "SelDrvMde22" 20 "SelDrvMde21" 19 "SelDrvMde20" 18 "SelDrvMde19" 17 "SelDrvMde18" 16 "SelDrvMde17" 15 "SelDrvMde16" 14 "SelDrvMde15" 13 "SelDrvMde14" 12 "SelDrvMde13" 11 "SelDrvMde12" 10 "SelDrvMde11" 9 "SelDrvMde10" 8 "SelDrvMde09" 7 "SelDrvMde08" 6 "SelDrvMde07" 5 "SelDrvMde06" 4 "SelDrvMde05" 3 "SelDrvMde04" 2 "SelDrvMde03" 1 "SelDrvMde02" 0 "SelDrvMde01" ;
VAL_ 1043 IndvMdeSel_D_Stat 3 "NotUsed" 2 "DriveModeChangeRequest" 1 "DriveModeChangeSelection" 0 "NoDriveModeChangeRequest" ;
VAL_ 1043 IndvMdeMsgTxt_D_Rq 15 "Message15" 14 "Message14" 13 "Message13" 12 "Message12" 11 "Message11" 10 "Message10" 9 "Message9" 8 "Message8" 7 "Message7" 6 "Message6" 5 "Message5" 4 "Message4" 3 "Message3" 2 "Message2" 1 "Message1" 0 "NoMessage" ;
VAL_ 1043 IndvMde5_B_Avail 1 "Available" 0 "NotAvailable" ;
VAL_ 1043 IndvMde4_B_Avail 1 "Available" 0 "NotAvailable" ;
VAL_ 1043 IndvMde3_B_Avail 1 "Available" 0 "NotAvailable" ;
VAL_ 1043 IndvMde2_B_Avail 1 "Available" 0 "NotAvailable" ;
VAL_ 1043 IndvMde1_B_Avail 1 "Available" 0 "NotAvailable" ;
VAL_ 1043 TrailOnePdlMde_D_Ind 7 "NotUsed_4" 6 "NotUsed_3" 5 "NotUsed_2" 4 "NotUsed_1" 3 "Standby" 2 "Active" 1 "Fault" 0 "Off" ;
VAL_ 1043 TrailOnePdlMsgTxt_D_Rq 7 "Message7" 6 "Message6" 5 "Message5" 4 "Message4" 3 "Message3" 2 "Message2" 1 "Message1" 0 "NoMessage" ;
VAL_ 1043 OrtaSwtchLamp_B_Rq 1 "On" 0 "Off" ;
VAL_ 1043 OrtaMsgTxt_D_Rq 15 "Message15" 14 "Message14" 13 "Message13" 12 "Message12" 11 "Message11" 10 "Message10" 9 "Message9" 8 "Message8" 7 "Message7" 6 "Message6" 5 "Message5" 4 "Message4" 3 "Message3" 2 "Message2" 1 "Message1" 0 "NoMessage" ;
VAL_ 1043 OrtaMde_D_Ind 7 "Faulty" 6 "NotUsed_2" 5 "NotUsed_1" 4 "ActiveRight" 3 "ActiveLeft" 2 "StandbyRight" 1 "StandbyLeft" 0 "Off" ;
VAL_ 991 PersIndexVdm_D_Actl 7 "Unused_3" 6 "Unused_2" 5 "Unused_1" 4 "Vehicle" 3 "PERS_4" 2 "PERS_3" 1 "PERS_2" 0 "PERS_1" ;
VAL_ 395 SelDrvMdeCnfm_D_Stat 3 "NotUsed" 2 "Accepted" 1 "NotAccepted" 0 "Null" ;
VAL_ 395 HudMde_D_Rq 7 "NotUsed3" 6 "NotUsed2" 5 "NotUsed1" 4 "Manual" 3 "Drag" 2 "RoadCourse" 1 "Tach" 0 "Off" ;
VAL_ 395 HudLedMde_D_Rq 3 "Not_Used" 2 "Flash" 1 "On" 0 "Off" ;
VAL_ 395 HudLed9On_B_Rq 1 "On" 0 "Off" ;
VAL_ 395 HudLed8On_B_Rq 1 "On" 0 "Off" ;
VAL_ 395 HudLed7On_B_Rq 1 "On" 0 "Off" ;
VAL_ 395 HudLed6On_B_Rq 1 "On" 0 "Off" ;
VAL_ 395 HudLed5On_B_Rq 1 "On" 0 "Off" ;
VAL_ 395 HudLed4On_B_Rq 1 "On" 0 "Off" ;
VAL_ 395 HudLed3On_B_Rq 1 "On" 0 "Off" ;
VAL_ 395 HudLed2On_B_Rq 1 "On" 0 "Off" ;
VAL_ 395 HudLed1On_B_Rq 1 "On" 0 "Off" ;
VAL_ 395 HudLed18On_B_Rq 1 "On" 0 "Off" ;
VAL_ 395 HudLed17On_B_Rq 1 "On" 0 "Off" ;
VAL_ 395 HudLed16On_B_Rq 1 "On" 0 "Off" ;
VAL_ 395 HudLed15On_B_Rq 1 "On" 0 "Off" ;
VAL_ 395 HudLed14On_B_Rq 1 "On" 0 "Off" ;
VAL_ 395 HudLed13On_B_Rq 1 "On" 0 "Off" ;
VAL_ 395 HudLed12On_B_Rq 1 "On" 0 "Off" ;
VAL_ 395 HudLed11On_B_Rq 1 "On" 0 "Off" ;
VAL_ 395 HudLed10On_B_Rq 1 "On" 0 "Off" ;
VAL_ 515 PtIgnSwtch_D_Stat 3 "Faulty" 2 "No_Data_Exists" 1 "On" 0 "Off" ;
VAL_ 982 LatCtl_D2_Rq 7 "NotUsed_5" 6 "NotUsed_4" 5 "NotUsed_3" 4 "NotUsed_2" 3 "SafeRampOut" 2 "PathFollowingExtendedMode" 1 "PathFollowingLimitedMode" 0 "NoLateralControl" ;
VAL_ 982 HandsOffCnfm_B_Rq 1 "Active" 0 "Inactive" ;
VAL_ 982 LatCtlRampType_D_Rq 3 "Immediately" 2 "Fast" 1 "Medium" 0 "Slow" ;
VAL_ 982 LatCtlPrecision_D_Rq 3 "NotUsed2" 2 "NotUsed1" 1 "Precise" 0 "Comfortable" ;
VAL_ 1104 DrvEngageLevel_D_Stat 7 "Faulty" 6 "NotUsed_2" 5 "NotUsed_1" 4 "Disengaged" 3 "Distracted" 2 "Attentive" 1 "Invalid" 0 "NotDetermined" ;
VAL_ 1104 DrvImpLvlConfid_D_Stat 7 "Faulty" 6 "NotUsed" 5 "High" 4 "MediumHigh" 3 "Medium" 2 "LowMedium" 1 "Low" 0 "NotDetermined" ;
VAL_ 1104 DrvImpairLvl_D_Stat 15 "Faulty" 14 "NotUsed_5" 13 "NotUsed_4" 12 "NotUsed_3" 11 "NotUsed_2" 10 "NotUsed_1" 9 "Incapacitated" 8 "Asleep" 7 "Microsleep" 6 "MostDrowsy" 5 "Drowsy_4" 4 "Drowsy_3" 3 "Drowsy_2" 2 "LeastDrowsy" 1 "Alert" 0 "NotDetermined" ;
VAL_ 1104 DrvEngLvlConfid_D_Stat 7 "Faulty" 6 "NotUsed" 5 "High" 4 "MediumHigh" 3 "Medium" 2 "LowMedium" 1 "Low" 0 "NotDetermined" ;
VAL_ 1104 DrvCamPassIR_D_Stat 3 "Faulty" 2 "Blocked" 1 "Ok" 0 "TemporaryUnavailable" ;
VAL_ 1104 DrvCamera_D_Stat 3 "Faulty" 2 "Blocked" 1 "Ok" 0 "TemporaryUnavailable" ;
VAL_ 1104 DrvCamDrvIR_D_Stat 3 "Faulty" 2 "Blocked" 1 "Ok" 0 "TemporaryUnavailable" ;
VAL_ 1104 DrvAttentZone_D_Stat 15 "Faulty" 14 "NotUsed_5" 13 "NotUsed_4" 12 "NotUsed_3" 11 "NotConfigured" 10 "DriverLap" 9 "PassengerSideWindow" 8 "DriverSideWindow" 7 "DriverSideMirror" 6 "RearviewMirror" 5 "PassengerSideMirror" 4 "Infotainment" 3 "Cluster" 2 "FrontWindshield" 1 "Other" 0 "NotDetermined" ;
VAL_ 1104 DrvAlertSt_D_Stat 3 "Faulty" 2 "EyesOffRoad" 1 "EyesOnRoad" 0 "NotDetermined" ;
VAL_ 829 PwSrcULoMde2_D_Actl 3 "BuckSpecial" 2 "ReverseBoost" 1 "ForwardBuck" 0 "Standby" ;
VAL_ 829 DcdcUHi3_I_Actl 2047 "Faulty" 2046 "NoDataExists" ;
SIG_GROUP_ 982 SG_LatCtlPath 1 : LatCtlPathOffst_L_Actl LatCtl_D2_Rq LatCtlCrv_NoRate2_Actl LatCtlCurv_No_Actl LatCtlPath_No_Cnt LatCtlPath_No_Cs LatCtlPath_An_Actl;
SIG_GROUP_ 1104 SG_DrvStatMonData 1 : DrvEngLvlConfid_D_Stat DrvEngageLevel_D_Stat DrvEngageLevel_No_Cnt DrvEngageLevel_No_Cs;
